VERSION ""

NS_ :

BS_:

BU_: TPMS iBooster_ADAS IM ESC_ADAS EPS1_ADAS CGW_ADAS VCU_ADAS FCM

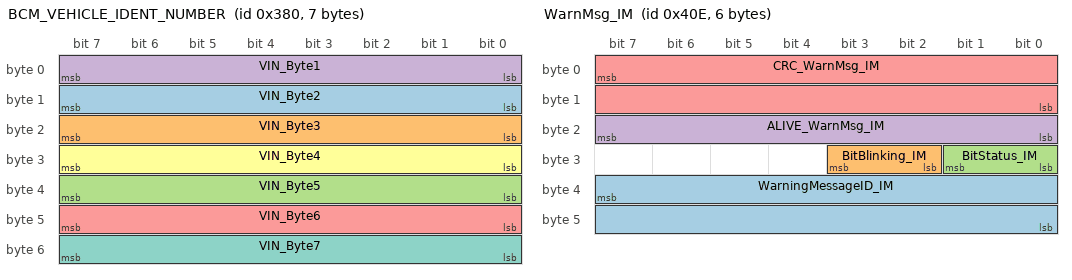
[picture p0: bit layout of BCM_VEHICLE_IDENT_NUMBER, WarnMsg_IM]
BO_ 896 BCM_VEHICLE_IDENT_NUMBER: 7 CGW_ADAS
 SG_ VIN_Byte2 : 15|8@0+ (1,0) [0|254] ""  VCU_ADAS,ESC_ADAS,iBooster_ADAS,EPS1_ADAS
 SG_ VIN_Byte3 : 23|8@0+ (1,0) [0|254] ""  VCU_ADAS,ESC_ADAS,iBooster_ADAS,EPS1_ADAS
 SG_ VIN_Byte5 : 39|8@0+ (1,0) [0|254] ""  VCU_ADAS,ESC_ADAS,iBooster_ADAS,EPS1_ADAS
 SG_ VIN_Byte1 : 7|8@0+ (1,0) [0|254] ""  VCU_ADAS,iBooster_ADAS,EPS1_ADAS,ESC_ADAS
 SG_ VIN_Byte6 : 47|8@0+ (1,0) [0|254] ""  VCU_ADAS,ESC_ADAS,iBooster_ADAS,EPS1_ADAS
 SG_ VIN_Byte4 : 31|8@0+ (1,0) [0|254] ""  VCU_ADAS,ESC_ADAS,iBooster_ADAS,EPS1_ADAS
 SG_ VIN_Byte7 : 55|8@0+ (1,0) [0|254] ""  VCU_ADAS,ESC_ADAS,iBooster_ADAS,EPS1_ADAS

BO_ 264 BCM_02_STAT_CENTRAL_LOCK_FLAP: 16 CGW_ADAS
 SG_ SSecOC_MAC_BCM_02 : 39|64@0+ (1,0) [0|1.84467440737096E+019] ""  FCM,ESC_ADAS,VCU_ADAS
 SG_ SSecOC_Fresh_BCM_02 : 31|8@0+ (1,0) [0|255] ""  FCM,ESC_ADAS,VCU_ADAS
 SG_ BCM_charging_flap_ajar_status : 115|2@0+ (1,0) [0|3] ""  VCU_ADAS,FCM,ESC_ADAS
 SG_ ALIVE_BCM_02 : 23|8@0+ (1,0) [0|255] ""  VCU_ADAS,FCM,ESC_ADAS
 SG_ CRC_BCM_02 : 7|16@0+ (1,0) [0|65535] ""  FCM,VCU_ADAS,ESC_ADAS
 SG_ STAT_BonnetAjar : 117|2@0+ (1,0) [0|3] "Bit"  VCU_ADAS,FCM,ESC_ADAS
 SG_ STAT_TrunkAjar : 119|2@0+ (1,0) [0|3] "Bit"  VCU_ADAS,FCM,ESC_ADAS
 SG_ STAT_DoorAjarRR : 105|2@0+ (1,0) [0|3] "Bit"  VCU_ADAS,FCM,ESC_ADAS
 SG_ STAT_DoorAjarPass : 109|2@0+ (1,0) [0|3] "Bit"  VCU_ADAS,FCM,ESC_ADAS
 SG_ STAT_DoorAjarRL : 107|2@0+ (1,0) [0|3] "Bit"  VCU_ADAS,FCM,ESC_ADAS
 SG_ STAT_DoorAjarDriver : 111|2@0+ (1,0) [0|3] "Bit"  VCU_ADAS,FCM,ESC_ADAS
 SG_ STAT_DoorLockPassenger : 101|2@0+ (1,0) [0|3] ""  VCU_ADAS,FCM,ESC_ADAS
 SG_ STAT_CDL_LED : 99|2@0+ (1,0) [0|3] ""  VCU_ADAS,FCM,ESC_ADAS
 SG_ STAT_ATWS : 127|3@0+ (1,0) [0|7] "Bit"  VCU_ADAS,FCM,ESC_ADAS
 SG_ STAT_DoorLockDriver : 103|2@0+ (1,0) [0|3] "Bit"  VCU_ADAS,FCM,ESC_ADAS

BO_ 433 CGW_01_CON_VEH: 16 CGW_ADAS
 SG_ SSecOC_MAC_CGW_01 : 39|64@0+ (1,0) [0|1.84467440737096E+019] ""  VCU_ADAS,ESC_ADAS,EPS1_ADAS,FCM,IM,iBooster_ADAS,TPMS
 SG_ ALIVE_CGW_01 : 23|8@0+ (1,0) [0|255] ""  VCU_ADAS,ESC_ADAS,EPS1_ADAS,FCM,IM,iBooster_ADAS,TPMS
 SG_ CRC_CGW_01 : 7|16@0+ (1,0) [0|65535] ""  VCU_ADAS,ESC_ADAS,EPS1_ADAS,FCM,IM,iBooster_ADAS,TPMS
 SG_ VEH_State : 103|4@0+ (1,0) [0|15] ""  VCU_ADAS,EPS1_ADAS,ESC_ADAS,FCM,IM,iBooster_ADAS,TPMS
 SG_ SSecOC_Fresh_CGW_01 : 31|8@0+ (1,0) [0|255] ""  VCU_ADAS,ESC_ADAS,EPS1_ADAS,FCM,IM,iBooster_ADAS,TPMS
 SG_ CGW_OBDConnectStatus : 99|2@0+ (1,0) [0|3] ""  VCU_ADAS,TPMS,IM,iBooster_ADAS,FCM,ESC_ADAS,EPS1_ADAS

BO_ 1040 WarnMsg_EPS1: 16 EPS1_ADAS
 SG_ SSecOC_MAC_EPS1WarnMsg : 39|64@0+ (1,0) [0|1.84467440737096E+019] ""  CGW_ADAS
 SG_ SSecOC_Fresh_EPS1WarnMsg : 31|8@0+ (1,0) [0|255] ""  CGW_ADAS
 SG_ WarningMessageID_EPS1 : 111|16@0+ (1,0) [0|65535] ""  CGW_ADAS
 SG_ BitBlinking_EPS1 : 99|2@0+ (1,0) [0|3] "Bit"  CGW_ADAS
 SG_ BitStatus_EPS1 : 97|2@0+ (1,0) [0|3] "Bit"  CGW_ADAS
 SG_ ALIVE_WarnMsg_EPS1 : 23|8@0+ (1,0) [0|255] ""  CGW_ADAS
 SG_ CRC_WarnMsg_EPS1 : 7|16@0+ (1,0) [0|65535] ""  CGW_ADAS

BO_ 1039 WarnMsg_ESC: 16 ESC_ADAS
 SG_ SSecOC_MAC_ESCWarnMsg : 39|64@0+ (1,0) [0|1.84467440737096E+019] ""  CGW_ADAS
 SG_ SSecOC_Fresh_ESCWarnMsg : 31|8@0+ (1,0) [0|255] ""  CGW_ADAS
 SG_ WarningMessageID_ESC : 111|16@0+ (1,0) [0|65535] ""  CGW_ADAS
 SG_ BitBlinking_ESC : 99|2@0+ (1,0) [0|3] "Bit"  CGW_ADAS
 SG_ BitStatus_ESC : 97|2@0+ (1,0) [0|3] "Bit"  CGW_ADAS
 SG_ ALIVE_WarnMsg_ESC : 23|8@0+ (1,0) [0|255] ""  CGW_ADAS
 SG_ CRC_WarnMsg_ESC : 7|16@0+ (1,0) [0|65535] ""  CGW_ADAS

BO_ 1038 WarnMsg_IM: 6 IM
 SG_ WarningMessageID_IM : 39|16@0+ (1,0) [0|65535] ""  CGW_ADAS
 SG_ BitBlinking_IM : 27|2@0+ (1,0) [0|3] "Bit"  CGW_ADAS
 SG_ BitStatus_IM : 25|2@0+ (1,0) [0|3] "Bit"  CGW_ADAS
 SG_ ALIVE_WarnMsg_IM : 23|8@0+ (1,0) [0|255] ""  CGW_ADAS
 SG_ CRC_WarnMsg_IM : 7|16@0+ (1,0) [0|65535] ""  CGW_ADAS

BO_ 247 BMS_01_HVB_status: 64 VCU_ADAS
 SG_ BMS_SOHlastUpdateInterval : 255|14@0+ (1,0) [0|16383] "km"  CGW_ADAS,FCM,EPS1_ADAS
 SG_ BMS_actPower : 503|10@0+ (1,-600) [-600|250] "kWh"  CGW_ADAS,FCM,EPS1_ADAS
 SG_ BMS_addedEnergyCharging : 204|9@0+ (1,-250) [-250|250] "kWh"  CGW_ADAS,FCM,EPS1_ADAS
 SG_ BMS_BattCellstartframeNum : 487|16@0+ (1,0) [1|65531] ""  CGW_ADAS,FCM,EPS1_ADAS
 SG_ BMS_HvBattSocinstalled : 109|10@0+ (0.1,0) [0|100] "percent (%)"  CGW_ADAS,EPS1_ADAS,FCM
 SG_ BMS_HvBattSt : 115|3@0+ (1,0) [0|7] ""  CGW_ADAS,FCM,EPS1_ADAS
 SG_ BMS_HvBattIMaxDchaLon : 223|11@0+ (1,0) [0|2047] "ampere (A)"  CGW_ADAS,EPS1_ADAS,FCM
 SG_ BMS_HvBattI : 327|16@0+ (0.1,-2047) [-2047|2047] "ampere (A)"  CGW_ADAS,EPS1_ADAS,FCM
 SG_ BMS_HvBattRlyPosSt : 157|2@0+ (1,0) [0|1] ""  CGW_ADAS,EPS1_ADAS,FCM
 SG_ BMS_HvBattRlyNegSt : 155|2@0+ (1,0) [0|1] ""  CGW_ADAS,EPS1_ADAS,FCM
 SG_ BMS_HvBattT30CVolt : 295|15@0+ (1,0) [0|32767] "mV"  CGW_ADAS,EPS1_ADAS,FCM
 SG_ BMS_HvBattPackUDchaLim : 151|10@0+ (1,0) [0|1023] "volt (V)"  CGW_ADAS,EPS1_ADAS,FCM
 SG_ BMS_HvBattSoeAct : 127|11@0+ (0.1,0) [0|204.7] "kWh"  CGW_ADAS,EPS1_ADAS,FCM
 SG_ BMS_HvBattU : 343|14@0+ (0.1,0) [0|1638.3] "volt (V)"  CGW_ADAS,EPS1_ADAS,FCM
 SG_ BMS_HvBattPackUChrgnLim : 167|10@0+ (1,0) [0|1023] "volt (V)"  CGW_ADAS,EPS1_ADAS,FCM
 SG_ BMS_HvBattDynChrgILim : 239|11@0+ (1,0) [0|2047] "ampere (A)"  CGW_ADAS,EPS1_ADAS,FCM
 SG_ SSecOC_MAC_BMS_01 : 39|64@0+ (1,0) [0|1.84467440737096E+019] ""  CGW_ADAS,EPS1_ADAS,FCM
 SG_ SSecOC_Fresh_BMS_01 : 31|8@0+ (1,0) [0|255] ""  CGW_ADAS,EPS1_ADAS,FCM
 SG_ ALIVE_BMS_01 : 23|8@0+ (1,0) [0|255] ""  CGW_ADAS,EPS1_ADAS,FCM
 SG_ CRC_BMS_01 : 7|16@0+ (1,0) [0|65535] ""  CGW_ADAS,EPS1_ADAS,FCM
 SG_ BMS_HvBattIMaxChrgLon : 271|11@0+ (1,0) [0|2047] "ampere (A)"  CGW_ADAS,EPS1_ADAS,FCM
 SG_ BMS_HvBattSoh : 143|7@0+ (1,0) [0|100] "percent (%)"  CGW_ADAS,EPS1_ADAS,FCM
 SG_ BMS_HvBattChrgnAllwd : 136|1@0+ (1,0) [0|1] ""  CGW_ADAS,EPS1_ADAS,FCM
 SG_ BMS_HvBattSdilSt : 425|2@0+ (1,0) [0|3] ""  CGW_ADAS,EPS1_ADAS,FCM
 SG_ BMS_HVBattCellVolt : 471|16@0+ (1,0) [0|65535] "mV"  CGW_ADAS,FCM,EPS1_ADAS
 SG_ BMS_HvBattIMaxDchaMidLon : 423|11@0+ (1,0) [0|2047] ""  CGW_ADAS,EPS1_ADAS,FCM
 SG_ BMS_HvBattUint : 407|13@0+ (0.1,0) [0|819.1] "volt (V)"  CGW_ADAS,EPS1_ADAS,FCM
 SG_ BMS_HvBattIsoR_status : 112|1@0+ (1,0) [0|1] ""  CGW_ADAS,EPS1_ADAS,FCM
 SG_ BMS_HvBattHvilSt : 427|2@0+ (1,0) [0|3] ""  CGW_ADAS,EPS1_ADAS,FCM
 SG_ BMS_HvBattIsoRNegGND_Ohm : 455|16@0+ (1,0) [0|65535] "kiloohm"  CGW_ADAS,EPS1_ADAS,FCM
 SG_ BMS_HvBattIsoRPosGND_Ohm : 439|16@0+ (1,0) [0|65535] "kiloohm"  CGW_ADAS,EPS1_ADAS,FCM
 SG_ BMS_HvBattCellVoltMax : 391|13@0+ (1,0) [0|8191] "mV"  CGW_ADAS,EPS1_ADAS,FCM
 SG_ BMS_HvBattCellVoltNom : 375|13@0+ (1,0) [0|8191] "mV"  CGW_ADAS,EPS1_ADAS,FCM
 SG_ BMS_HvBattCellVoltMin : 359|13@0+ (1,0) [0|8191] "mV"  CGW_ADAS,EPS1_ADAS,FCM
 SG_ BMS_HvBattT30Volt : 311|15@0+ (1,0) [0|32767] "mV"  CGW_ADAS,EPS1_ADAS,FCM
 SG_ BMS_HvBattRlyPrechSt : 153|2@0+ (1,0) [0|1] ""  CGW_ADAS,EPS1_ADAS,FCM
 SG_ BMS_HvBattIMaxChrgMidLon : 274|11@0+ (1,0) [0|2047] "ampere (A)"  CGW_ADAS,EPS1_ADAS,FCM
 SG_ BMS_HvBattDynDchaILim : 199|11@0+ (1,0) [0|2047] "ampere (A)"  CGW_ADAS,EPS1_ADAS,FCM
 SG_ BMS_HvBattCellUChrgnLim : 183|13@0+ (1,0) [0|8191] "mV"  CGW_ADAS,EPS1_ADAS,FCM
 SG_ BMS_HvBattSocAct_usable : 103|10@0+ (0.1,0) [0|100] "percent (%)"  CGW_ADAS,EPS1_ADAS,FCM

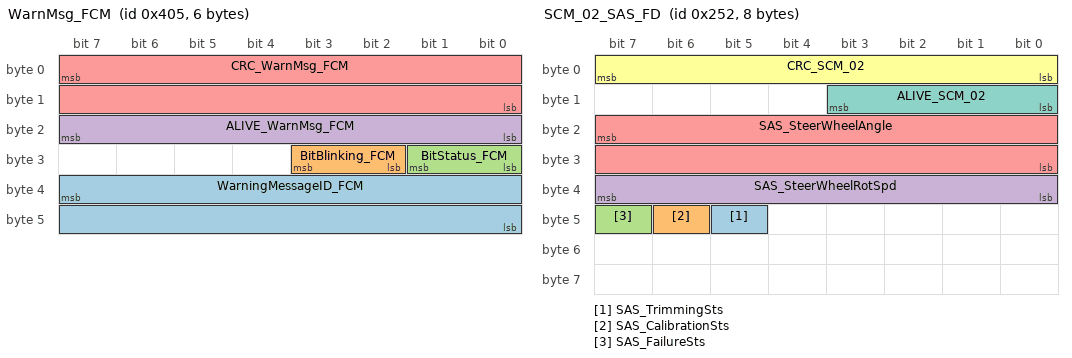
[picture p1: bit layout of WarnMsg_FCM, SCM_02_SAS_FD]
BO_ 1029 WarnMsg_FCM: 6 FCM
 SG_ WarningMessageID_FCM : 39|16@0+ (1,0) [0|65535] ""  CGW_ADAS
 SG_ BitBlinking_FCM : 27|2@0+ (1,0) [0|3] "Bit"  CGW_ADAS
 SG_ BitStatus_FCM : 25|2@0+ (1,0) [0|3] "Bit"  CGW_ADAS
 SG_ ALIVE_WarnMsg_FCM : 23|8@0+ (1,0) [0|255] ""  CGW_ADAS
 SG_ CRC_WarnMsg_FCM : 7|16@0+ (1,0) [0|65535] ""  CGW_ADAS

BO_ 258 BCM_01_LOGICAL_CLAMP: 16 CGW_ADAS
 SG_ SSecOC_MAC_BCM_01 : 39|64@0+ (1,0) [0|1.84467440737096E+019] ""  VCU_ADAS,TPMS,IM,iBooster_ADAS,FCM,ESC_ADAS,EPS1_ADAS
 SG_ SSecOC_Fresh_BCM_01 : 31|8@0+ (1,0) [0|255] ""  VCU_ADAS,TPMS,IM,iBooster_ADAS,FCM,ESC_ADAS,EPS1_ADAS
 SG_ STAT_StartStopButton : 115|2@0+ (1,0) [0|3] ""  VCU_ADAS,TPMS,IM,iBooster_ADAS,FCM,ESC_ADAS,EPS1_ADAS
 SG_ BCM_Cl30R_Off_Announcement : 125|2@0+ (1,0) [0|3] ""  VCU_ADAS,TPMS,IM,iBooster_ADAS,FCM,ESC_ADAS,EPS1_ADAS
 SG_ BCM_Cl30s_Off_Announcement : 127|2@0+ (1,0) [0|3] ""  VCU_ADAS,TPMS,IM,iBooster_ADAS,FCM,ESC_ADAS,EPS1_ADAS
 SG_ BCM_STAT_TransportMode : 117|2@0+ (1,0) [0|3] ""  VCU_ADAS,FCM,IM,ESC_ADAS,EPS1_ADAS,iBooster_ADAS,TPMS
 SG_ BCM_KL15_Off_Announcement : 119|2@0+ (1,0) [0|3] ""  VCU_ADAS,FCM,IM,ESC_ADAS,EPS1_ADAS,iBooster_ADAS,TPMS
 SG_ BCM_ST_KL : 108|4@0+ (1,0) [0|15] ""  VCU_ADAS,FCM,IM,ESC_ADAS,EPS1_ADAS,iBooster_ADAS,TPMS
 SG_ BCM_STAT_Terminal : 111|3@0+ (1,0) [0|7] ""  VCU_ADAS,FCM,IM,ESC_ADAS,EPS1_ADAS,iBooster_ADAS,TPMS
 SG_ BCM_STAT_CL30R_L : 99|2@0+ (1,0) [0|3] ""  VCU_ADAS,FCM,IM,ESC_ADAS,EPS1_ADAS,iBooster_ADAS,TPMS
 SG_ BCM_STAT_CL30s_L : 101|2@0+ (1,0) [0|3] ""  VCU_ADAS,FCM,IM,ESC_ADAS,EPS1_ADAS,iBooster_ADAS,TPMS
 SG_ CRC_BCM_01 : 7|16@0+ (1,0) [0|65535] ""  VCU_ADAS,FCM,IM,ESC_ADAS,EPS1_ADAS,iBooster_ADAS,TPMS
 SG_ ALIVE_BCM_01 : 23|8@0+ (1,0) [0|255] ""  VCU_ADAS,FCM,IM,ESC_ADAS,EPS1_ADAS,iBooster_ADAS,TPMS
 SG_ BCM_STAT_CL15_L : 103|2@0+ (1,0) [0|3] ""  VCU_ADAS,FCM,IM,ESC_ADAS,EPS1_ADAS,iBooster_ADAS,TPMS

BO_ 2564502513 Diag_FuncReq: 8 CGW_ADAS
 SG_ Diag_FuncReq_Data : 7|64@0+ (1,0) [0|1.84467440737096E+019] "N/A"  FCM,IM,ESC_ADAS,iBooster_ADAS,TPMS,EPS1_ADAS

BO_ 752 HU_OdoMeter: 16 CGW_ADAS
 SG_ SSecOC_MAC_HU_OdoMeter : 39|64@0+ (1,0) [0|255] ""  VCU_ADAS,IM,FCM,ESC_ADAS,iBooster_ADAS,EPS1_ADAS
 SG_ SSecOC_Fresh_HU_OdoMeter : 31|8@0+ (1,0) [0|255] ""  VCU_ADAS,IM,FCM,ESC_ADAS,iBooster_ADAS,EPS1_ADAS
 SG_ ALIVE_HU_OdoMeter : 23|8@0+ (1,0) [0|255] ""  VCU_ADAS,IM,FCM,ESC_ADAS,iBooster_ADAS,EPS1_ADAS
 SG_ CRC_HU_OdoMeter : 7|16@0+ (1,0) [0|65535] ""  VCU_ADAS,IM,FCM,ESC_ADAS,iBooster_ADAS,EPS1_ADAS
 SG_ HU_Odometer : 103|24@0+ (1,0) [0|16777215] "km"  VCU_ADAS,IM,FCM,ESC_ADAS,iBooster_ADAS,EPS1_ADAS

BO_ 513 ACM_02_SBR: 20 CGW_ADAS
 SG_ ST_OCS_CalRespSts : 147|2@0+ (1,0) [0|3] ""  VCU_ADAS,FCM,ESC_ADAS
 SG_ ST_OCS_CalVal : 150|3@0+ (1,0) [0|7] ""  VCU_ADAS,FCM,ESC_ADAS
 SG_ ST_OCS_EOL : 151|1@0+ (1,0) [0|1] ""  VCU_ADAS,FCM,ESC_ADAS
 SG_ ST_OCS_EcuFailr : 106|1@0+ (1,0) [0|1] ""  VCU_ADAS,FCM,ESC_ADAS
 SG_ ST_OCS_StsCntr : 139|4@0+ (1,0) [0|15] ""  VCU_ADAS,FCM,ESC_ADAS
 SG_ ST_OCS_AirbAllwdSts : 141|2@0+ (1,0) [0|3] ""  VCU_ADAS,FCM,ESC_ADAS
 SG_ ST_OCS_ERROR : 111|3@0+ (1,0) [0|7] ""  VCU_ADAS,FCM,ESC_ADAS
 SG_ SSecOC_MAC_ACM_02 : 39|64@0+ (1,0) [0|1.84467440737096E+019] ""  VCU_ADAS,FCM,ESC_ADAS
 SG_ SSecOC_Fresh_ACM_02 : 31|8@0+ (1,0) [0|255] ""  VCU_ADAS,FCM,ESC_ADAS
 SG_ ST_SEAT_POS_PAS : 127|2@0+ (1,0) [0|3] ""  VCU_ADAS,FCM,ESC_ADAS
 SG_ ST_SEAT_POS_DRV : 119|2@0+ (1,0) [0|3] ""  VCU_ADAS,FCM,ESC_ADAS
 SG_ ST_PAB_SW : 105|2@0+ (1,0) [0|3] ""  VCU_ADAS,FCM,ESC_ADAS
 SG_ ST_PAB_ON : 103|1@0+ (1,0) [0|1] ""  VCU_ADAS,FCM,ESC_ADAS
 SG_ ST_BELT_BUCK_RM : 129|2@0+ (1,0) [0|3] ""  VCU_ADAS,FCM,ESC_ADAS
 SG_ ST_IGN_ACM : 99|1@0+ (1,0) [0|1] ""  VCU_ADAS,FCM,ESC_ADAS
 SG_ ST_CRS_DET : 101|2@0+ (1,0) [0|3] ""  VCU_ADAS,FCM,ESC_ADAS
 SG_ ST_COD : 98|3@0+ (1,0) [0|7] ""  VCU_ADAS,FCM,ESC_ADAS
 SG_ ST_BELT_BUCK_RR : 143|2@0+ (1,0) [0|3] ""  VCU_ADAS,FCM,ESC_ADAS
 SG_ ST_BELT_BUCK_RL : 131|2@0+ (1,0) [0|3] ""  VCU_ADAS,FCM,ESC_ADAS
 SG_ ST_BELT_BUCK_PS : 133|2@0+ (1,0) [0|3] ""  VCU_ADAS,FCM,ESC_ADAS
 SG_ ST_SEAT_OCCU_PS : 108|2@0+ (1,0) [0|3] ""  VCU_ADAS,FCM,ESC_ADAS
 SG_ ST_BELT_BUCK_DR : 135|2@0+ (1,0) [0|3] ""  VCU_ADAS,FCM,ESC_ADAS
 SG_ ST_PAB_OFF : 102|1@0+ (1,0) [0|1] ""  VCU_ADAS,FCM,ESC_ADAS
 SG_ ALIVE_ACM_02 : 23|8@0+ (1,0) [0|255] ""  VCU_ADAS,FCM,ESC_ADAS
 SG_ CRC_ACM_02 : 7|16@0+ (1,0) [0|65535] ""  VCU_ADAS,FCM,ESC_ADAS

BO_ 2564485412 Diag_Resp_RadarRR: 64 FCM
 SG_ Diag_Resp_RadarRR : 7|64@0+ (1,0) [0|1.84467440737096E+019] "N/A"  CGW_ADAS

BO_ 2564485411 Diag_Resp_RadarRL: 64 FCM
 SG_ Diag_Resp_RadarRL : 7|64@0+ (1,0) [0|1.84467440737096E+019] "N/A"  CGW_ADAS

BO_ 2564485404 Diag_Resp_RF: 64 FCM
 SG_ Diag_Resp_RF : 7|64@0+ (1,0) [0|1.84467440737096E+019] "N/A"  CGW_ADAS

BO_ 2564433137 Diag_PhyReq_RadarRR: 64 CGW_ADAS
 SG_ Diag_PhyReq_RadarRR : 7|64@0+ (1,0) [0|1.84467440737096E+019] "N/A"  FCM

BO_ 2564432881 Diag_PhyReq_RadarRL: 64 CGW_ADAS
 SG_ Diag_PhyReq_RadarRL : 7|64@0+ (1,0) [0|1.84467440737096E+019] "N/A"  FCM

BO_ 2564431089 Diag_PhyReq_RF: 64 CGW_ADAS
 SG_ Diag_PhyReq_RF : 7|64@0+ (1,0) [0|1.84467440737096E+019] "N/A"  FCM

BO_ 1305 NM_TPMS: 8 TPMS
 SG_ usrData1_TPM_Bit7_ECUSPEC_AWAKE : 31|1@0+ (1,0) [0|1] ""  VCU_ADAS,IM,iBooster_ADAS,FCM,ESC_ADAS,EPS1_ADAS,CGW_ADAS
 SG_ usrData1_TPM_Bit6_DIAGN_AWAKE : 30|1@0+ (1,0) [0|1] ""  VCU_ADAS,IM,iBooster_ADAS,FCM,ESC_ADAS,EPS1_ADAS,CGW_ADAS
 SG_ usrData1_TPM_Bit5_IGNITION_AWAKE : 29|1@0+ (1,0) [0|1] ""  VCU_ADAS,IM,iBooster_ADAS,FCM,ESC_ADAS,EPS1_ADAS,CGW_ADAS
 SG_ usrData1_TPM_Bit4_NETWORK_AWAKE : 28|1@0+ (1,0) [0|1] ""  VCU_ADAS,IM,iBooster_ADAS,FCM,ESC_ADAS,EPS1_ADAS,CGW_ADAS
 SG_ usrData1_TPM_Bit3_ECUSPEC_WAKEUP : 27|1@0+ (1,0) [0|1] ""  VCU_ADAS,IM,iBooster_ADAS,FCM,ESC_ADAS,EPS1_ADAS,CGW_ADAS
 SG_ usrData1_TPM_Bit2_NETWORK_WAKEUP : 26|1@0+ (1,0) [0|1] ""  VCU_ADAS,IM,iBooster_ADAS,FCM,ESC_ADAS,EPS1_ADAS,CGW_ADAS
 SG_ usrData1_TPM_Bit1_RESET_WAKEUP : 25|1@0+ (1,0) [0|1] ""  VCU_ADAS,IM,iBooster_ADAS,FCM,ESC_ADAS,EPS1_ADAS,CGW_ADAS
 SG_ CtrlBitVector_TPM_Bit7_Res : 15|1@0+ (1,0) [0|1] ""  VCU_ADAS,IM,iBooster_ADAS,FCM,ESC_ADAS,EPS1_ADAS,CGW_ADAS
 SG_ CtrlBitVector_TPM_Bit6_PNI : 14|1@0+ (1,0) [0|1] ""  VCU_ADAS,IM,iBooster_ADAS,FCM,ESC_ADAS,EPS1_ADAS,CGW_ADAS
 SG_ CtrlBitVector_TPM_Bit5_Res : 13|1@0+ (1,0) [0|1] ""  VCU_ADAS,IM,iBooster_ADAS,FCM,ESC_ADAS,EPS1_ADAS,CGW_ADAS
 SG_ CtrlBitVector_TPM_Bit4_ActWake : 12|1@0+ (1,0) [0|1] ""  VCU_ADAS,IM,iBooster_ADAS,FCM,ESC_ADAS,EPS1_ADAS,CGW_ADAS
 SG_ CtrlBitVector_TPM_Bit3_NMCoord : 11|1@0+ (1,0) [0|1] ""  VCU_ADAS,IM,iBooster_ADAS,FCM,ESC_ADAS,EPS1_ADAS,CGW_ADAS
 SG_ CtrlBitVector_TPM_Bit2_Res : 10|1@0+ (1,0) [0|1] ""  VCU_ADAS,IM,iBooster_ADAS,FCM,ESC_ADAS,EPS1_ADAS,CGW_ADAS
 SG_ CtrlBitVector_TPM_Bit1_Res : 9|1@0+ (1,0) [0|1] ""  VCU_ADAS,IM,iBooster_ADAS,FCM,ESC_ADAS,EPS1_ADAS,CGW_ADAS
 SG_ usrData1_TPM_Bit0_IGN_WAKEUP : 24|1@0+ (1,0) [0|1] ""  VCU_ADAS,IM,iBooster_ADAS,FCM,ESC_ADAS,EPS1_ADAS,CGW_ADAS
 SG_ usrData0_TPM : 23|8@0+ (1,0) [0|255] ""  VCU_ADAS,IM,iBooster_ADAS,FCM,ESC_ADAS,EPS1_ADAS,CGW_ADAS
 SG_ srcNodeID_TPM : 7|8@0+ (1,0) [0|127] ""  VCU_ADAS,IM,iBooster_ADAS,FCM,ESC_ADAS,EPS1_ADAS,CGW_ADAS
 SG_ CtrlBitVector_TPM_Bit0_RMR : 8|1@0+ (1,0) [0|1] ""  VCU_ADAS,IM,iBooster_ADAS,FCM,ESC_ADAS,EPS1_ADAS,CGW_ADAS
 SG_ usrData2_TPM : 39|8@0+ (1,0) [0|255] ""  VCU_ADAS,IM,iBooster_ADAS,FCM,ESC_ADAS,EPS1_ADAS,CGW_ADAS
 SG_ usrData4_TPM_PN_Info1 : 55|8@0+ (1,0) [0|255] ""  VCU_ADAS,IM,iBooster_ADAS,FCM,ESC_ADAS,EPS1_ADAS,CGW_ADAS
 SG_ usrData5_TPM_PN_Info2 : 63|8@0+ (1,0) [0|255] ""  VCU_ADAS,IM,iBooster_ADAS,FCM,ESC_ADAS,EPS1_ADAS,CGW_ADAS
 SG_ usrData3_TPM : 47|8@0+ (1,0) [0|255] ""  VCU_ADAS,IM,iBooster_ADAS,FCM,ESC_ADAS,EPS1_ADAS,CGW_ADAS

BO_ 1913 Meas_TPMS_1: 8 TPMS
 SG_ TPMS_MEAS_ID M : 7|8@0+ (1,0) [0|0] ""  CGW_ADAS
 SG_ Meas_TPM_1H m1 : 63|8@0+ (1,0) [0|255] ""  CGW_ADAS
 SG_ Meas_TPM_1G m1 : 55|8@0+ (1,0) [0|255] ""  CGW_ADAS
 SG_ Meas_TPM_1F : 47|8@0+ (1,0) [0|255] ""  CGW_ADAS
 SG_ Meas_TPM_1E m2 : 39|8@0+ (1,0) [0|255] ""  CGW_ADAS
 SG_ Meas_TPM_1D m1 : 31|8@0+ (1,0) [0|255] ""  CGW_ADAS
 SG_ Meas_TPM_1C m1 : 23|8@0+ (1,0) [0|255] ""  CGW_ADAS
 SG_ Meas_TPM_1B m1 : 15|8@0+ (1,0) [0|255] ""  CGW_ADAS
 SG_ Meas_TPM_1A m1 : 39|8@0+ (1,0) [0|255] ""  CGW_ADAS

BO_ 1284 NM_VCU: 8 VCU_ADAS
 SG_ usrData1_VCU_Bit7_ECUSPEC_AWAKE : 31|1@0+ (1,0) [0|1] ""  TPMS,IM,iBooster_ADAS,FCM,ESC_ADAS,EPS1_ADAS
 SG_ usrData1_VCU_Bit6_DIAGN_AWAKE : 30|1@0+ (1,0) [0|1] ""  TPMS,IM,iBooster_ADAS,FCM,ESC_ADAS,EPS1_ADAS
 SG_ usrData1_VCU_Bit5_IGNITION_AWAKE : 29|1@0+ (1,0) [0|1] ""  TPMS,IM,iBooster_ADAS,FCM,ESC_ADAS,EPS1_ADAS
 SG_ usrData1_VCU_Bit4_NETWORK_AWAKE : 28|1@0+ (1,0) [0|1] ""  TPMS,IM,iBooster_ADAS,FCM,ESC_ADAS,EPS1_ADAS
 SG_ usrData1_VCU_Bit3_ECUSPEC_WAKEUP : 27|1@0+ (1,0) [0|1] ""  TPMS,IM,iBooster_ADAS,FCM,ESC_ADAS,EPS1_ADAS
 SG_ usrData1_VCU_Bit2_NETWORK_WAKEUP : 26|1@0+ (1,0) [0|1] ""  TPMS,IM,iBooster_ADAS,FCM,ESC_ADAS,EPS1_ADAS
 SG_ usrData1_VCU_Bit1_RESET_WAKEUP : 25|1@0+ (1,0) [0|1] ""  TPMS,IM,iBooster_ADAS,FCM,ESC_ADAS,EPS1_ADAS
 SG_ CtrlBitVector_VCU_Bit7_Res : 15|1@0+ (1,0) [0|1] ""  TPMS,IM,iBooster_ADAS,FCM,ESC_ADAS,EPS1_ADAS
 SG_ CtrlBitVector_VCU_Bit6_PNI : 14|1@0+ (1,0) [0|1] ""  TPMS,IM,iBooster_ADAS,FCM,ESC_ADAS,EPS1_ADAS
 SG_ CtrlBitVector_VCU_Bit5_Res : 13|1@0+ (1,0) [0|1] ""  TPMS,IM,iBooster_ADAS,FCM,ESC_ADAS,EPS1_ADAS
 SG_ CtrlBitVector_VCU_Bit4_ActWake : 12|1@0+ (1,0) [0|1] ""  TPMS,IM,iBooster_ADAS,FCM,ESC_ADAS,EPS1_ADAS
 SG_ CtrlBitVector_VCU_Bit3_NMCoord : 11|1@0+ (1,0) [0|1] ""  TPMS,IM,iBooster_ADAS,FCM,ESC_ADAS,EPS1_ADAS
 SG_ CtrlBitVector_VCU_Bit2_Res : 10|1@0+ (1,0) [0|1] ""  TPMS,IM,iBooster_ADAS,FCM,ESC_ADAS,EPS1_ADAS
 SG_ CtrlBitVector_VCU_Bit1_Res : 9|1@0+ (1,0) [0|1] ""  TPMS,IM,iBooster_ADAS,FCM,ESC_ADAS,EPS1_ADAS
 SG_ usrData1_VCU_Bit0_IGN_WAKEUP : 24|1@0+ (1,0) [0|1] ""  TPMS,IM,iBooster_ADAS,FCM,ESC_ADAS,EPS1_ADAS
 SG_ usrData0_VCU : 23|8@0+ (1,0) [0|255] ""  TPMS,IM,iBooster_ADAS,FCM,ESC_ADAS,EPS1_ADAS
 SG_ srcNodeID_VCU : 7|8@0+ (1,0) [0|127] ""  TPMS,IM,iBooster_ADAS,FCM,ESC_ADAS,EPS1_ADAS
 SG_ CtrlBitVector_VCU_Bit0_RMR : 8|1@0+ (1,0) [0|1] ""  TPMS,IM,iBooster_ADAS,FCM,ESC_ADAS,EPS1_ADAS
 SG_ usrData2_VCU : 39|8@0+ (1,0) [0|255] ""  TPMS,IM,iBooster_ADAS,FCM,ESC_ADAS,EPS1_ADAS
 SG_ usrData4_VCU_PN_Info1 : 55|8@0+ (1,0) [0|255] ""  TPMS,IM,iBooster_ADAS,FCM,ESC_ADAS,EPS1_ADAS
 SG_ usrData5_VCU_PN_Info2 : 63|8@0+ (1,0) [0|255] ""  TPMS,IM,iBooster_ADAS,FCM,ESC_ADAS,EPS1_ADAS
 SG_ usrData3_VCU : 47|8@0+ (1,0) [0|255] ""  TPMS,IM,iBooster_ADAS,FCM,ESC_ADAS,EPS1_ADAS

BO_ 594 SCM_02_SAS_FD: 8 CGW_ADAS
 SG_ SAS_TrimmingSts : 45|1@0+ (1,0) [0|1] ""  IM,FCM,EPS1_ADAS,VCU_ADAS
 SG_ SAS_CalibrationSts : 46|1@0+ (1,0) [0|1] ""  IM,FCM,EPS1_ADAS,VCU_ADAS
 SG_ SAS_FailureSts : 47|1@0+ (1,0) [0|1] ""  IM,FCM,EPS1_ADAS,VCU_ADAS
 SG_ SAS_SteerWheelRotSpd : 39|8@0+ (4,0) [0|1016] "deg/s"  IM,FCM,EPS1_ADAS,VCU_ADAS
 SG_ SAS_SteerWheelAngle : 23|16@0+ (0.1,-960) [-960|960] "deg"  IM,FCM,EPS1_ADAS,VCU_ADAS
 SG_ CRC_SCM_02 : 7|8@0+ (1,0) [0|255] ""  IM,FCM,EPS1_ADAS,VCU_ADAS
 SG_ ALIVE_SCM_02 : 11|4@0+ (1,0) [0|15] ""  IM,FCM,EPS1_ADAS,VCU_ADAS

BO_ 592 SCM_01_SwCtrl_FD: 8 CGW_ADAS
 SG_ SCM_SteeringWheel_rotation_flag : 55|1@0+ (1,0) [0|1] ""  FCM
 SG_ SCM_IHBC_MenuReq : 40|1@0+ (1,0) [0|1] ""  FCM
 SG_ SCM_IHBC_MenuReqInvalid : 41|1@0+ (1,0) [0|1] ""  FCM
 SG_ SCM_SW_MasterLightSwitch : 45|4@0+ (1,0) [0|15] ""  FCM
 SG_ SCM_SW_DaytimeLight : 46|1@0+ (1,0) [0|1] ""  FCM
 SG_ SCM_SW_DaytimeLightInvalid : 47|1@0+ (1,0) [0|1] ""  FCM
 SG_ SCM_SW_Trip : 33|2@0+ (1,0) [0|3] ""  FCM
 SG_ SCM_Req_TurnIndicationAct : 35|2@0+ (1,0) [0|3] ""  FCM
 SG_ SCM_RearWipingMode : 37|2@0+ (1,0) [0|3] ""  FCM
 SG_ SCM_SW_FrontFogLight : 38|1@0+ (1,0) [0|1] ""  FCM
 SG_ SCM_SW_FrontFogLightInvalid : 39|1@0+ (1,0) [0|1] ""  FCM
 SG_ SCM_SW_RearFogLight : 24|1@0+ (1,0) [0|1] ""  FCM
 SG_ SCM_SW_RearFogLightInvalid : 25|1@0+ (1,0) [0|1] ""  FCM
 SG_ SCM_WipingInterval_Sensitvity : 28|3@0+ (1,0) [0|7] ""  FCM
 SG_ SCM_FrontWipingMode : 31|3@0+ (1,0) [0|7] ""  FCM
 SG_ SCM_SW_FlashLightSts : 16|1@0+ (1,0) [0|1] ""  FCM
 SG_ SCM_SW_FlashLightStsInvalid : 17|1@0+ (1,0) [0|1] ""  FCM
 SG_ SCM_SW_RWasherSts : 18|1@0+ (1,0) [0|1] ""  FCM
 SG_ SCM_SW_RWasherStsInvalid : 19|1@0+ (1,0) [0|0] ""  FCM
 SG_ SCM_SW_FWasherSts : 20|1@0+ (1,0) [0|1] ""  FCM
 SG_ SCM_SW_FWasherStsInvalid : 21|1@0+ (1,0) [0|1] ""  FCM
 SG_ SCM_SW_HighBeam : 22|1@0+ (1,0) [0|1] ""  FCM
 SG_ SCM_SW_HighBeamInvalid : 23|1@0+ (1,0) [0|1] ""  FCM
 SG_ ALIVE_SCM_01 : 11|4@0+ (1,0) [0|15] ""  FCM
 SG_ CRC_SCM_01 : 7|8@0+ (1,0) [0|255] ""  FCM

BO_ 389 FCM_05_PDC: 32 FCM
 SG_ FCM_PDC_ROR_USSSts : 209|2@0+ (1,0) [0|3] ""  CGW_ADAS
 SG_ FCM_PDC_ROL_USSSts : 207|2@0+ (1,0) [0|3] ""  CGW_ADAS
 SG_ FCM_PDC_FOR_USSSts : 205|2@0+ (1,0) [0|3] ""  CGW_ADAS
 SG_ FCM_PDC_FOL_USSSts : 203|2@0+ (1,0) [0|3] ""  CGW_ADAS
 SG_ FCM_PDC_RIR_USSSts : 201|2@0+ (1,0) [0|3] ""  CGW_ADAS
 SG_ FCM_PDC_RIL_USSSts : 199|2@0+ (1,0) [0|3] ""  CGW_ADAS
 SG_ FCM_PDC_RearAudWarn : 179|3@0+ (1,0) [0|7] ""  CGW_ADAS
 SG_ FCM_PDC_FrontAudWarn : 182|3@0+ (1,0) [0|7] ""  CGW_ADAS
 SG_ FCM_PDC_FailrWarn : 183|1@0+ (1,0) [0|1] ""  CGW_ADAS
 SG_ ALIVE_FCM_05 : 23|8@0+ (1,0) [0|255] ""  CGW_ADAS
 SG_ CRC_FCM_05 : 7|16@0+ (1,0) [0|65535] ""  CGW_ADAS
 SG_ FCM_PDC_ToneVol : 175|8@0+ (1,0) [0|255] ""  CGW_ADAS
 SG_ FCM_PDC_Mode : 167|8@0+ (1,0) [0|255] ""  CGW_ADAS
 SG_ FCM_PDC_Distance_ROR : 159|8@0+ (1,0) [0|255] ""  CGW_ADAS
 SG_ FCM_PDC_Distance_RIR : 151|8@0+ (1,0) [0|255] ""  CGW_ADAS
 SG_ FCM_PDC_Distance_RIL : 143|8@0+ (1,0) [0|255] ""  CGW_ADAS
 SG_ FCM_PDC_Distance_ROL : 135|8@0+ (1,0) [0|255] ""  CGW_ADAS
 SG_ FCM_PDC_Distance_FOR : 127|8@0+ (1,0) [0|255] ""  CGW_ADAS
 SG_ FCM_PDC_Distance_FIR : 119|8@0+ (1,0) [0|255] ""  CGW_ADAS
 SG_ FCM_PDC_Distance_FIL : 111|8@0+ (1,0) [0|255] ""  CGW_ADAS
 SG_ FCM_PDC_Distance_FOL : 103|8@0+ (1,0) [0|0] ""  CGW_ADAS
 SG_ FCM_PDC_FIR_USSSts : 197|2@0+ (1,0) [0|3] ""  CGW_ADAS
 SG_ FCM_PDC_FIL_USSSts : 195|2@0+ (1,0) [0|3] ""  CGW_ADAS
 SG_ FCM_PDC_FltMod : 188|3@0+ (1,0) [0|7] ""  CGW_ADAS
 SG_ FCM_PDC_USSCoverSt : 193|2@0+ (1,0) [0|3] ""  CGW_ADAS
 SG_ FCM_PDC_FrntPDCBtnSts : 185|2@0+ (1,0) [0|3] ""  CGW_ADAS

BO_ 272 VCU_05: 20 VCU_ADAS
 SG_ VCU_AccelPedalSts : 97|2@0+ (1,0) [0|0] ""  TPMS,IM,iBooster_ADAS,FCM,ESC_ADAS,EPS1_ADAS
 SG_ SSecOC_MAC_VCU_05 : 39|64@0+ (1,0) [0|1.84467440737096E+019] ""  TPMS,IM,iBooster_ADAS,FCM,ESC_ADAS,EPS1_ADAS
 SG_ SSecOC_Fresh_VCU_05 : 31|8@0+ (1,0) [0|255] ""  TPMS,IM,iBooster_ADAS,FCM,ESC_ADAS,EPS1_ADAS
 SG_ VCU_CC_SpdLim_Sts : 107|3@0+ (1,0) [0|7] ""  TPMS,IM,iBooster_ADAS,FCM,ESC_ADAS,EPS1_ADAS
 SG_ ALIVE_VCU_05 : 23|8@0+ (1,0) [0|255] ""  IM,ESC_ADAS,FCM,iBooster_ADAS,EPS1_ADAS,TPMS
 SG_ CRC_VCU_05 : 7|16@0+ (1,0) [0|65535] ""  IM,ESC_ADAS,FCM,iBooster_ADAS,EPS1_ADAS,TPMS
 SG_ VCU_ActSt : 111|4@0+ (1,0) [0|15] ""  TPMS,iBooster_ADAS,EPS1_ADAS,IM,FCM,ESC_ADAS
 SG_ VCU_GearSig : 103|4@0+ (1,0) [0|15] ""  IM,FCM,ESC_ADAS,iBooster_ADAS,EPS1_ADAS,TPMS
 SG_ VCU_GearSig_Q : 99|2@0+ (1,0) [0|3] ""  IM,FCM,ESC_ADAS,iBooster_ADAS,EPS1_ADAS,TPMS

BO_ 327 EDU_F_03_Rx: 20 VCU_ADAS
 SG_ SSecOC_MAC_EDU_F_03 : 39|64@0+ (1,0) [0|1.84467440737096E+019] ""  iBooster_ADAS,ESC_ADAS,EPS1_ADAS
 SG_ SSecOC_Fresh_EDU_F_03 : 31|8@0+ (1,0) [0|255] ""  iBooster_ADAS,ESC_ADAS,EPS1_ADAS
 SG_ EDU_F_ParkLock_Sts : 139|3@0+ (1,0) [0|7] ""  EPS1_ADAS,ESC_ADAS,iBooster_ADAS
 SG_ EDU_F_ActTq_Q : 101|2@0+ (1,0) [0|3] ""  iBooster_ADAS,EPS1_ADAS,ESC_ADAS
 SG_ EDU_F_ActSpd : 111|16@0- (1,0) [-32768|32767] "rpm"  iBooster_ADAS,EPS1_ADAS,ESC_ADAS
 SG_ EDU_F_ActTq : 127|11@0- (1,0) [-512|511] "Nm"  iBooster_ADAS,ESC_ADAS,EPS1_ADAS
 SG_ EDU_F_ActSpdSig_Q : 132|2@0+ (1,0) [0|3] ""  iBooster_ADAS,ESC_ADAS,EPS1_ADAS
 SG_ EDU_F_ActMod : 99|4@0+ (1,0) [0|15] ""  iBooster_ADAS,EPS1_ADAS,ESC_ADAS
 SG_ EDU_F_HVActvDcha_Sts : 130|3@0+ (1,0) [0|7] ""  iBooster_ADAS,EPS1_ADAS,ESC_ADAS
 SG_ EDU_F_SlipCtrlAct_Sts : 141|2@0+ (1,0) [0|3] ""  iBooster_ADAS,EPS1_ADAS,ESC_ADAS
 SG_ EDU_F_WarningLamp_FS : 142|1@0+ (1,0) [0|1] ""  iBooster_ADAS,EPS1_ADAS,ESC_ADAS
 SG_ EDU_F_HVChkEnd_Sts : 143|1@0+ (1,0) [0|1] ""  iBooster_ADAS,EPS1_ADAS,ESC_ADAS
 SG_ ALIVE_EDU_F_03 : 23|8@0+ (1,0) [0|255] ""  iBooster_ADAS,EPS1_ADAS,ESC_ADAS
 SG_ CRC_EDU_F_03 : 7|16@0+ (1,0) [0|65535] ""  iBooster_ADAS,EPS1_ADAS,ESC_ADAS
 SG_ EDU_F_SlipCtrlOffsetTq : 151|10@0- (1,0) [-512|511] "Nm"  iBooster_ADAS,EPS1_ADAS,ESC_ADAS

BO_ 328 EDU_R_03_Rx: 24 VCU_ADAS
 SG_ SSecOC_MAC_EDU_R_03 : 39|64@0+ (1,0) [0|1.84467440737096E+019] ""  iBooster_ADAS,ESC_ADAS
 SG_ SSecOC_Fresh_EDU_R_03 : 31|8@0+ (1,0) [0|255] ""  iBooster_ADAS,ESC_ADAS
 SG_ EDU_R_SlipCtrlOffsetTq : 159|10@0- (1,0) [-512|511] "Nm"  iBooster_ADAS,ESC_ADAS
 SG_ EDU_R_Trans_gear_Sts : 151|4@0+ (1,0) [0|15] ""  iBooster_ADAS,ESC_ADAS
 SG_ EDU_R_ActSpd : 135|16@0- (1,0) [-32768|32767] "rpm"  ESC_ADAS,iBooster_ADAS
 SG_ EDU_R_ActTq : 119|11@0- (1,0) [-512|511] "Nm"  iBooster_ADAS,ESC_ADAS
 SG_ EDU_R_ActTq_Q : 101|2@0+ (1,0) [0|3] ""  iBooster_ADAS,ESC_ADAS
 SG_ EDU_R_ActSpdSig_Q : 99|2@0+ (1,0) [0|3] ""  ESC_ADAS,iBooster_ADAS
 SG_ EDU_R_ActMod : 107|4@0+ (1,0) [0|15] ""  iBooster_ADAS,ESC_ADAS
 SG_ EDU_R_HVActvDcha_Sts : 124|3@0+ (1,0) [0|7] ""  iBooster_ADAS,ESC_ADAS
 SG_ EDU_R_SlipCtrlAct_Sts : 165|2@0+ (1,0) [0|3] ""  iBooster_ADAS,ESC_ADAS
 SG_ EDU_R_Warninglamp_FS : 96|1@0+ (1,0) [0|1] ""  iBooster_ADAS,ESC_ADAS
 SG_ EDU_R_HVChkEnd_Sts : 97|1@0+ (1,0) [0|1] ""  iBooster_ADAS,ESC_ADAS
 SG_ ALIVE_EDU_R_03 : 23|8@0+ (1,0) [0|255] ""  ESC_ADAS,iBooster_ADAS
 SG_ CRC_EDU_R_03 : 7|16@0+ (1,0) [0|65535] ""  ESC_ADAS,iBooster_ADAS

BO_ 589 CGW_SyncSecOC: 20 CGW_ADAS
 SG_ Syn_RstCtrlVal : 127|20@0+ (1,0) [0|1048575] ""  FCM,EPS1_ADAS,ESC_ADAS,VCU_ADAS
 SG_ Syn_TripCtrlVal : 103|24@0+ (1,0) [0|16777215] ""  FCM,EPS1_ADAS,ESC_ADAS,VCU_ADAS
 SG_ SSecOC_MAC_CGW_Sync : 39|64@0+ (1,0) [0|1.84467440737096E+019] ""  FCM,EPS1_ADAS,ESC_ADAS,VCU_ADAS
 SG_ SSecOC_Fresh_CGW_Sync : 31|8@0+ (1,0) [0|255] ""  FCM,EPS1_ADAS,ESC_ADAS,VCU_ADAS
 SG_ CRC_CGW_Sync : 7|16@0+ (1,0) [0|65535] ""  FCM,EPS1_ADAS,ESC_ADAS,VCU_ADAS
 SG_ ALIVE_CGW_Sync : 23|8@0+ (1,0) [0|255] ""  FCM,EPS1_ADAS,ESC_ADAS,VCU_ADAS

BO_ 1285 NM_FCM: 8 FCM
 SG_ usrData1_FCM_Bit7_ECUSPEC_AWAKE : 31|1@0+ (1,0) [0|1] ""  VCU_ADAS,TPMS,IM,iBooster_ADAS,ESC_ADAS,EPS1_ADAS,CGW_ADAS
 SG_ usrData1_FCM_Bit6_DIAGN_AWAKE : 30|1@0+ (1,0) [0|1] ""  VCU_ADAS,TPMS,IM,iBooster_ADAS,ESC_ADAS,EPS1_ADAS,CGW_ADAS
 SG_ usrData1_FCM_Bit5_IGNITION_AWAKE : 29|1@0+ (1,0) [0|1] ""  VCU_ADAS,TPMS,IM,iBooster_ADAS,ESC_ADAS,EPS1_ADAS,CGW_ADAS
 SG_ usrData1_FCM_Bit4_NETWORK_AWAKE : 28|1@0+ (1,0) [0|1] ""  VCU_ADAS,TPMS,IM,iBooster_ADAS,ESC_ADAS,EPS1_ADAS,CGW_ADAS
 SG_ usrData1_FCM_Bit3_ECUSPEC_WAKEUP : 27|1@0+ (1,0) [0|1] ""  VCU_ADAS,TPMS,IM,iBooster_ADAS,ESC_ADAS,EPS1_ADAS,CGW_ADAS
 SG_ usrData1_FCM_Bit2_NETWORK_WAKEUP : 26|1@0+ (1,0) [0|1] ""  VCU_ADAS,TPMS,IM,iBooster_ADAS,ESC_ADAS,EPS1_ADAS,CGW_ADAS
 SG_ usrData1_FCM_Bit1_RESET_WAKEUP : 25|1@0+ (1,0) [0|1] ""  VCU_ADAS,TPMS,IM,iBooster_ADAS,ESC_ADAS,EPS1_ADAS,CGW_ADAS
 SG_ CtrlBitVector_FCM_Bit7_Res : 15|1@0+ (1,0) [0|1] ""  VCU_ADAS,TPMS,IM,iBooster_ADAS,ESC_ADAS,EPS1_ADAS,CGW_ADAS
 SG_ CtrlBitVector_FCM_Bit6_PNI : 14|1@0+ (1,0) [0|1] ""  VCU_ADAS,TPMS,IM,iBooster_ADAS,ESC_ADAS,EPS1_ADAS,CGW_ADAS
 SG_ CtrlBitVector_FCM_Bit5_Res : 13|1@0+ (1,0) [0|1] ""  VCU_ADAS,TPMS,IM,iBooster_ADAS,ESC_ADAS,EPS1_ADAS,CGW_ADAS
 SG_ CtrlBitVector_FCM_Bit4_ActWake : 12|1@0+ (1,0) [0|1] ""  VCU_ADAS,TPMS,IM,iBooster_ADAS,ESC_ADAS,EPS1_ADAS,CGW_ADAS
 SG_ CtrlBitVector_FCM_Bit3_NMCoord : 11|1@0+ (1,0) [0|1] ""  VCU_ADAS,TPMS,IM,iBooster_ADAS,ESC_ADAS,EPS1_ADAS,CGW_ADAS
 SG_ CtrlBitVector_FCM_Bit2_Res : 10|1@0+ (1,0) [0|1] ""  VCU_ADAS,TPMS,IM,iBooster_ADAS,ESC_ADAS,EPS1_ADAS,CGW_ADAS
 SG_ CtrlBitVector_FCM_Bit1_Res : 9|1@0+ (1,0) [0|1] ""  VCU_ADAS,TPMS,IM,iBooster_ADAS,ESC_ADAS,EPS1_ADAS,CGW_ADAS
 SG_ usrData1_FCM_Bit0_IGN_WAKEUP : 24|1@0+ (1,0) [0|1] ""  VCU_ADAS,TPMS,IM,iBooster_ADAS,ESC_ADAS,EPS1_ADAS,CGW_ADAS
 SG_ usrData0_FCM : 23|8@0+ (1,0) [0|255] ""  VCU_ADAS,TPMS,IM,iBooster_ADAS,ESC_ADAS,EPS1_ADAS,CGW_ADAS
 SG_ srcNodeID_FCM : 7|8@0+ (1,0) [0|127] ""  VCU_ADAS,TPMS,IM,iBooster_ADAS,ESC_ADAS,EPS1_ADAS,CGW_ADAS
 SG_ CtrlBitVector_FCM_Bit0_RMR : 8|1@0+ (1,0) [0|1] ""  VCU_ADAS,TPMS,IM,iBooster_ADAS,ESC_ADAS,EPS1_ADAS,CGW_ADAS
 SG_ usrData2_FCM : 39|8@0+ (1,0) [0|255] ""  VCU_ADAS,TPMS,IM,iBooster_ADAS,ESC_ADAS,EPS1_ADAS,CGW_ADAS
 SG_ usrData4_FCM_PN_Info1 : 55|8@0+ (1,0) [0|255] ""  VCU_ADAS,TPMS,IM,iBooster_ADAS,ESC_ADAS,EPS1_ADAS,CGW_ADAS
 SG_ usrData5_FCM_PN_Info2 : 63|8@0+ (1,0) [0|255] ""  VCU_ADAS,TPMS,IM,iBooster_ADAS,ESC_ADAS,EPS1_ADAS,CGW_ADAS
 SG_ usrData3_FCM : 47|8@0+ (1,0) [0|255] ""  VCU_ADAS,TPMS,IM,iBooster_ADAS,ESC_ADAS,EPS1_ADAS,CGW_ADAS

BO_ 384 FCM_01: 64 FCM
 SG_ FCM_AESA_IndcrLiReq : 359|3@0+ (1,0) [0|7] ""  VCU_ADAS,ESC_ADAS,EPS1_ADAS,CGW_ADAS
 SG_ SSecOC_MAC_FCM_01 : 39|64@0+ (1,0) [0|1.84467440737096E+019] ""  VCU_ADAS,ESC_ADAS,EPS1_ADAS,CGW_ADAS
 SG_ SSecOC_Fresh_FCM_01 : 31|8@0+ (1,0) [0|255] ""  VCU_ADAS,ESC_ADAS,EPS1_ADAS,CGW_ADAS
 SG_ FCM_PDC_BtnLEDSts : 320|1@0+ (1,0) [0|1] ""  VCU_ADAS,ESC_ADAS,EPS1_ADAS,CGW_ADAS
 SG_ FCM_ELK_WarnSts : 391|8@0+ (1,0) [0|255] ""  CGW_ADAS,VCU_ADAS,EPS1_ADAS,ESC_ADAS
 SG_ FCM_ELK_WarnLvl : 153|2@0+ (1,0) [0|3] ""  CGW_ADAS,VCU_ADAS,EPS1_ADAS,ESC_ADAS
 SG_ FCM_AEB_Req : 189|2@0+ (1,0) [0|3] ""  VCU_ADAS,ESC_ADAS,EPS1_ADAS,CGW_ADAS
 SG_ FCM_AEB_BrkDecelVal : 207|11@0+ (0.01,-10) [-10|10] "m/s²"  CGW_ADAS,VCU_ADAS,EPS1_ADAS,ESC_ADAS
 SG_ FCM_AEB_PrefillReq : 192|1@0+ (1,0) [0|1] ""  CGW_ADAS,VCU_ADAS,EPS1_ADAS,ESC_ADAS
 SG_ FCM_DBS_Req : 191|2@0+ (1,0) [0|3] ""  CGW_ADAS,VCU_ADAS,EPS1_ADAS,ESC_ADAS
 SG_ FCM_AEB_FCWAlertReq : 169|2@0+ (1,0) [0|3] ""  CGW_ADAS,VCU_ADAS,EPS1_ADAS,ESC_ADAS
 SG_ FCM_AEB_CnclReasn : 173|4@0+ (1,0) [0|15] ""  CGW_ADAS,VCU_ADAS,EPS1_ADAS,ESC_ADAS
 SG_ FCM_AEB_FCWSnvtySt : 177|2@0+ (1,0) [0|3] ""  CGW_ADAS,VCU_ADAS,EPS1_ADAS,ESC_ADAS
 SG_ FCM_AEB_StsDisp : 180|3@0+ (1,0) [0|7] ""  CGW_ADAS,VCU_ADAS,EPS1_ADAS,ESC_ADAS
 SG_ FCM_AEB_ActvnSt : 340|3@0+ (1,0) [0|7] ""  CGW_ADAS,VCU_ADAS,EPS1_ADAS,ESC_ADAS
 SG_ FCM_ASA_Fuli_MainSignSL : 167|8@0+ (1,0) [0|3] ""  CGW_ADAS,VCU_ADAS,EPS1_ADAS,ESC_ADAS
 SG_ FCM_ASA_TFMapExpired : 104|1@0+ (1,0) [0|1] ""  CGW_ADAS,VCU_ADAS,EPS1_ADAS,ESC_ADAS
 SG_ FCM_ASA_TFDrivgSide : 156|3@0+ (1,0) [0|4] ""  CGW_ADAS,VCU_ADAS,EPS1_ADAS,ESC_ADAS
 SG_ FCM_ASA_ReconstructorSts : 159|3@0+ (1,0) [0|7] ""  CGW_ADAS,VCU_ADAS,EPS1_ADAS,ESC_ADAS
 SG_ FCM_ASA_CondlInfoMapSL : 131|4@0+ (1,0) [0|15] ""  CGW_ADAS,VCU_ADAS,EPS1_ADAS,ESC_ADAS
 SG_ FCM_ASA_SpdLimMai : 151|8@0+ (5,5) [5|255] ""  CGW_ADAS,VCU_ADAS,EPS1_ADAS,ESC_ADAS
 SG_ FCM_LCDAS_SoundWarnReq : 333|1@0+ (1,0) [0|1] ""  VCU_ADAS,ESC_ADAS,EPS1_ADAS,CGW_ADAS
 SG_ FCM_RCTA_RiAlertSt : 383|8@0+ (1,0) [0|255] ""  CGW_ADAS,VCU_ADAS,EPS1_ADAS,ESC_ADAS
 SG_ FCM_RCTA_LeAlertSt : 375|8@0+ (1,0) [0|255] ""  CGW_ADAS,VCU_ADAS,EPS1_ADAS,ESC_ADAS
 SG_ FCM_RCTA_Sts : 367|8@0+ (1,0) [0|255] ""  CGW_ADAS,VCU_ADAS,EPS1_ADAS,ESC_ADAS
 SG_ FCM_LCDAS_RiAlertSt : 348|3@0+ (1,0) [0|7] ""  CGW_ADAS,VCU_ADAS,EPS1_ADAS,ESC_ADAS
 SG_ FCM_LCDAS_LeAlertSt : 351|3@0+ (1,0) [0|7] ""  CGW_ADAS,VCU_ADAS,EPS1_ADAS,ESC_ADAS
 SG_ FCM_LCDAS_Sts : 343|3@0+ (1,0) [0|7] ""  CGW_ADAS,VCU_ADAS,EPS1_ADAS,ESC_ADAS
 SG_ FCM_HzrdLampReq : 321|1@0+ (1,0) [0|1] ""  CGW_ADAS,VCU_ADAS,EPS1_ADAS,ESC_ADAS
 SG_ FCM_SteerWheelTakeoverAlert : 324|3@0+ (1,0) [0|7] ""  CGW_ADAS,VCU_ADAS,EPS1_ADAS,ESC_ADAS
 SG_ FCM_LKA_WarnLvl : 326|2@0+ (1,0) [0|3] ""  CGW_ADAS,VCU_ADAS,EPS1_ADAS,ESC_ADAS
 SG_ FCM_LCS_Actv : 327|1@0+ (1,0) [0|1] ""  CGW_ADAS,VCU_ADAS,EPS1_ADAS,ESC_ADAS
 SG_ FCM_LCA_Actv : 312|1@0+ (1,0) [0|1] ""  CGW_ADAS,VCU_ADAS,EPS1_ADAS,ESC_ADAS
 SG_ FCM_LatFctCnclReason : 315|3@0+ (1,0) [0|7] ""  CGW_ADAS,VCU_ADAS,EPS1_ADAS,ESC_ADAS
 SG_ FCM_LatFctSts : 318|3@0+ (1,0) [0|7] ""  CGW_ADAS,VCU_ADAS,EPS1_ADAS,ESC_ADAS
 SG_ FCM_SteerWhlCtrlOrder : 319|1@0+ (1,0) [0|1] ""  CGW_ADAS,VCU_ADAS,EPS1_ADAS,ESC_ADAS
 SG_ FCM_ADAS_SteerCtrlFac : 311|8@0+ (1,0) [0|100] ""  CGW_ADAS,VCU_ADAS,EPS1_ADAS,ESC_ADAS
 SG_ FCM_ADAS_LatTqReq : 295|16@0+ (0.01,-327.68) [-327.68|327.67] "Nm"  CGW_ADAS,VCU_ADAS,EPS1_ADAS,ESC_ADAS
 SG_ FCM_ADAS_SteerAgReq : 279|16@0+ (0.01,-327.68) [-327.68|327.67] "deg"  CGW_ADAS,VCU_ADAS,EPS1_ADAS,ESC_ADAS
 SG_ FCM_ACC_WarnLvl : 251|2@0+ (1,0) [0|3] ""  CGW_ADAS,VCU_ADAS,EPS1_ADAS,ESC_ADAS
 SG_ FCM_ACC_SetSpdUnit : 249|2@0+ (1,0) [0|3] ""  CGW_ADAS,VCU_ADAS,EPS1_ADAS,ESC_ADAS
 SG_ FCM_ACC_SetSpd : 271|8@0+ (1,0) [0|250] ""  CGW_ADAS,VCU_ADAS,EPS1_ADAS,ESC_ADAS
 SG_ FCM_ACC_SetDst : 263|3@0+ (1,0) [0|7] "m"  CGW_ADAS,VCU_ADAS,EPS1_ADAS,ESC_ADAS
 SG_ FCM_ACC_CuttingInSts : 252|1@0+ (1,0) [0|1] ""  CGW_ADAS,VCU_ADAS,EPS1_ADAS,ESC_ADAS
 SG_ FCM_ACC_OffWeather : 253|1@0+ (1,0) [0|1] ""  CGW_ADAS,VCU_ADAS,EPS1_ADAS,ESC_ADAS
 SG_ FCM_ACC_DrvrBrkReq : 254|1@0+ (1,0) [0|1] ""  CGW_ADAS,VCU_ADAS,EPS1_ADAS,ESC_ADAS
 SG_ FCM_ACC_CtrlActv : 255|1@0+ (1,0) [0|1] ""  CGW_ADAS,VCU_ADAS,EPS1_ADAS,ESC_ADAS
 SG_ FCM_ACC_LeadingCarDisplay : 208|1@0+ (1,0) [0|1] ""  CGW_ADAS,VCU_ADAS,EPS1_ADAS,ESC_ADAS
 SG_ FCM_ACC_CnclReasn : 212|4@0+ (1,0) [0|15] ""  CGW_ADAS,VCU_ADAS,EPS1_ADAS,ESC_ADAS
 SG_ FCM_ACC_Sts : 227|4@0+ (1,0) [0|15] ""  CGW_ADAS,VCU_ADAS,EPS1_ADAS,ESC_ADAS
 SG_ FCM_ACC_TarDst : 239|16@0+ (1,0) [0|65535] "cm"  CGW_ADAS,VCU_ADAS,EPS1_ADAS,ESC_ADAS
 SG_ FCM_ACC_AReq : 223|12@0+ (1,-2048) [-2048|2047] "cm/s²"  CGW_ADAS,VCU_ADAS,EPS1_ADAS,ESC_ADAS
 SG_ FCM_ASA_DrvgContext : 114|3@0+ (1,0) [0|7] ""  CGW_ADAS,VCU_ADAS,EPS1_ADAS,ESC_ADAS
 SG_ FCM_ASA_SpdLimMap : 143|8@0+ (5,5) [5|255] ""  CGW_ADAS,VCU_ADAS,EPS1_ADAS,ESC_ADAS
 SG_ FCM_ASA_SpdUnit : 116|2@0+ (1,0) [0|3] ""  CGW_ADAS,VCU_ADAS,EPS1_ADAS,ESC_ADAS
 SG_ FCM_ASA_OperCtry : 127|12@0+ (1,0) [0|999] ""  CGW_ADAS,VCU_ADAS,EPS1_ADAS,ESC_ADAS
 SG_ FCM_ASA_FailrReasn : 119|3@0+ (1,0) [0|7] ""  CGW_ADAS,VCU_ADAS,EPS1_ADAS,ESC_ADAS
 SG_ FCM_ASA_ConditionalInfo : 111|4@0+ (1,0) [0|15] ""  CGW_ADAS,VCU_ADAS,EPS1_ADAS,ESC_ADAS
 SG_ FCM_ASA_Mod : 107|3@0+ (1,0) [0|7] ""  CGW_ADAS,VCU_ADAS,EPS1_ADAS,ESC_ADAS
 SG_ ALIVE_FCM_01 : 23|8@0+ (1,0) [0|255] ""  CGW_ADAS,VCU_ADAS,EPS1_ADAS,ESC_ADAS
 SG_ CRC_FCM_01 : 7|16@0+ (1,0) [0|65535] ""  CGW_ADAS,VCU_ADAS,EPS1_ADAS,ESC_ADAS
 SG_ FCM_ASA_SpdLimConfd : 103|8@0+ (1,0) [0|100] "%"  CGW_ADAS,VCU_ADAS,EPS1_ADAS,ESC_ADAS
 SG_ FCM_DRA_AESA_DoorUnlock_Req : 174|1@0+ (1,0) [0|1] ""  CGW_ADAS
 SG_ FCM_ADB_Failr : 330|2@0+ (1,0) [0|3] ""  VCU_ADAS,ESC_ADAS,EPS1_ADAS,CGW_ADAS
 SG_ FCM_ADB_Req : 332|2@0+ (1,0) [0|3] ""  VCU_ADAS,ESC_ADAS,EPS1_ADAS,CGW_ADAS

BO_ 416 EDU_F_01_Output: 20 VCU_ADAS
 SG_ EDU_F_Difflock_Sts : 122|3@0+ (1,0) [0|7] ""  ESC_ADAS
 SG_ CRC_EDU_F_01 : 7|16@0+ (1,0) [0|65535] ""  ESC_ADAS
 SG_ ALIVE_EDU_F_01 : 23|8@0+ (1,0) [0|255] ""  ESC_ADAS
 SG_ EDU_F_DCCurrInvt : 151|11@0- (1,0) [-1024|1023] "A"  ESC_ADAS
 SG_ EDU_F_HVVoltInvt : 103|10@0+ (1,0) [0|1023] "V"  ESC_ADAS
 SG_ EDU_F_AvlTorqMax : 119|13@0- (1,0) [-4096|4095] "Nm"  ESC_ADAS
 SG_ EDU_F_AvlTorqMin : 135|13@0- (1,0) [-4096|4095] "Nm"  ESC_ADAS
 SG_ EDU_F_Interlock_Sts : 109|2@0+ (1,0) [0|3] ""  ESC_ADAS

BO_ 419 EDU_R_01_Output: 32 VCU_ADAS
 SG_ EDU_R_Difflock_Sts : 122|3@0+ (1,0) [0|7] ""  ESC_ADAS
 SG_ CRC_EDU_R_01 : 7|16@0+ (1,0) [0|65535] ""  ESC_ADAS
 SG_ ALIVE_EDU_R_01 : 23|8@0+ (1,0) [0|255] ""  ESC_ADAS
 SG_ EDU_R_DCCurrInvt : 151|11@0- (1,0) [-1024|1023] "A"  ESC_ADAS
 SG_ EDU_R_HVVoltInvt : 103|10@0+ (1,0) [0|1023] "V"  ESC_ADAS
 SG_ EDU_R_AvlTorqMax : 119|13@0- (1,0) [-4096|4095] "Nm"  ESC_ADAS
 SG_ EDU_R_AvlTorqMin : 135|13@0- (1,0) [-4096|4095] "Nm"  ESC_ADAS
 SG_ EDU_R_Interlock_Sts : 109|2@0+ (1,0) [0|3] ""  ESC_ADAS

BO_ 422 VCUtoEDU_OutPut1: 48 VCU_ADAS
 SG_ SSecOC_MAC_VCUtoEDU_Output : 39|64@0+ (1,0) [0|1.84467440737096E+019] ""  FCM,ESC_ADAS,EPS1_ADAS,IM
 SG_ SSecOC_Fresh_VCUtoEDU_Output : 31|8@0+ (1,0) [0|255] ""  FCM,ESC_ADAS,EPS1_ADAS,IM
 SG_ VCU_ModeReq_EDU_R : 207|3@0+ (1,0) [0|7] ""  FCM,ESC_ADAS,IM,EPS1_ADAS
 SG_ VCU_Difflockreq_EDU_R : 154|2@0+ (1,0) [0|3] ""  ESC_ADAS,EPS1_ADAS,IM,FCM
 SG_ VCU_Difflockreq_EDU_F : 156|2@0+ (1,0) [0|3] ""  ESC_ADAS,EPS1_ADAS,IM,FCM
 SG_ VCU_HVActvDchaReq_EDU_R : 204|2@0+ (1,0) [0|3] ""  FCM,IM,ESC_ADAS,EPS1_ADAS
 SG_ VCU_HVActvDchaReq_EDU_F : 196|2@0+ (1,0) [0|3] ""  FCM,ESC_ADAS,IM,EPS1_ADAS
 SG_ VCU_TqReq_EDU_R : 183|13@0- (1,0) [-512|511] "Nm"  ESC_ADAS,EPS1_ADAS,IM,FCM
 SG_ VCU_AntiOsciReq_EDU_R : 121|2@0+ (1,0) [0|3] ""  ESC_ADAS,IM,EPS1_ADAS,FCM
 SG_ VCU_MaxAllwdCurrGen_EDU_R : 151|11@0+ (1,0) [0|2047] "A"  EPS1_ADAS,ESC_ADAS,IM,FCM
 SG_ VCU_MaxAllwdCurrMot_EDU_R : 119|11@0+ (1,0) [0|2047] "A"  IM,EPS1_ADAS,FCM,ESC_ADAS
 SG_ VCU_DriveMode : 108|3@0+ (1,0) [0|7] ""  ESC_ADAS,IM,EPS1_ADAS,FCM
 SG_ CRC_VCUtoEDU : 7|16@0+ (1,0) [0|65535] ""  IM,FCM,EPS1_ADAS,ESC_ADAS
 SG_ ALIVE_VCUtoEDU : 23|8@0+ (1,0) [0|255] ""  IM,FCM,EPS1_ADAS,ESC_ADAS
 SG_ VCU_TqReq_EDU_F : 167|13@0- (1,0) [-512|511] "Nm"  EPS1_ADAS,IM,FCM,ESC_ADAS
 SG_ VCU_ModeReq_EDU_F : 199|3@0+ (1,0) [0|7] ""  IM,EPS1_ADAS,FCM,ESC_ADAS
 SG_ VCU_ParklockReq_EDU_F : 170|2@0+ (1,0) [0|3] ""  IM,EPS1_ADAS,FCM,ESC_ADAS
 SG_ VCU_AntiOsciReq_EDU_F : 105|2@0+ (1,0) [0|3] ""  IM,EPS1_ADAS,FCM,ESC_ADAS
 SG_ VCU_MaxAllwdCurrMot_EDU_F : 103|11@0+ (1,0) [0|2047] "A"  IM,EPS1_ADAS,FCM,ESC_ADAS
 SG_ VCU_MaxAllwdCurrGen_EDU_F : 135|11@0+ (1,0) [0|2047] "A"  IM,EPS1_ADAS,FCM,ESC_ADAS
 SG_ VCU_EmgyReq : 124|1@0+ (1,0) [0|1] ""  IM,FCM,EPS1_ADAS,ESC_ADAS
 SG_ VCU_TransgearReq_EDU_R : 140|4@0+ (1,0) [0|15] ""  ESC_ADAS,IM,EPS1_ADAS,FCM

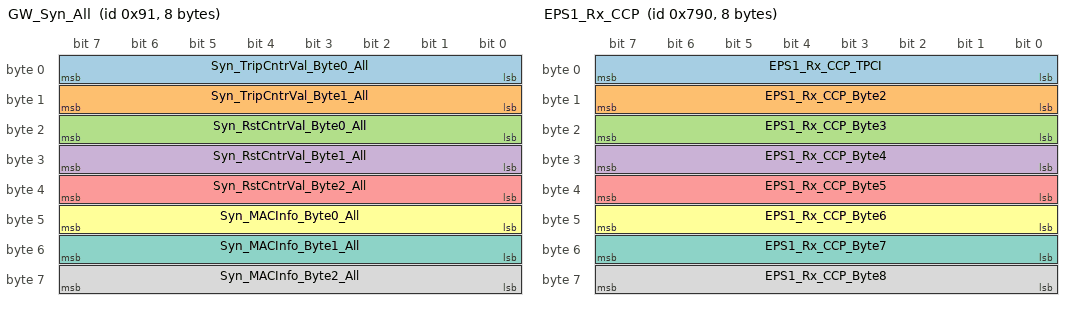
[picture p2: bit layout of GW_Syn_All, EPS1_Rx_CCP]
BO_ 145 GW_Syn_All: 8 CGW_ADAS
 SG_ Syn_TripCntrVal_Byte0_All : 7|8@0+ (1,0) [0|255] ""  VCU_ADAS,EPS1_ADAS
 SG_ Syn_TripCntrVal_Byte1_All : 15|8@0+ (1,0) [0|255] ""  VCU_ADAS,EPS1_ADAS
 SG_ Syn_RstCntrVal_Byte0_All : 23|8@0+ (1,0) [0|255] ""  VCU_ADAS,EPS1_ADAS
 SG_ Syn_RstCntrVal_Byte1_All : 31|8@0+ (1,0) [0|255] ""  VCU_ADAS,EPS1_ADAS
 SG_ Syn_RstCntrVal_Byte2_All : 39|8@0+ (1,0) [0|255] ""  VCU_ADAS,EPS1_ADAS
 SG_ Syn_MACInfo_Byte0_All : 47|8@0+ (1,0) [0|255] ""  VCU_ADAS,EPS1_ADAS
 SG_ Syn_MACInfo_Byte1_All : 55|8@0+ (1,0) [0|255] ""  VCU_ADAS,EPS1_ADAS
 SG_ Syn_MACInfo_Byte2_All : 63|8@0+ (1,0) [0|255] ""  VCU_ADAS,EPS1_ADAS

BO_ 300 iBooster_01_DRIVER_BRAKE_FORCE: 32 iBooster_ADAS
 SG_ iBooster_ExtBrkReqSts : 202|2@0+ (1,0) [0|3] ""  CGW_ADAS,FCM
 SG_ iBooster_ExtReqPrioFlg : 203|1@0+ (1,0) [0|1] ""  CGW_ADAS,FCM
 SG_ iBooster_MstCylBrkPedlActTrvl : 215|12@0+ (0.015625,-5) [-5|47] "mm"  CGW_ADAS,FCM
 SG_ iBooster_DrvrBrkPedlTrvlSts : 185|2@0+ (1,0) [0|3] ""  CGW_ADAS,FCM
 SG_ iBooster_MstCylBrkPedlActTrvlSts : 187|2@0+ (1,0) [0|3] ""  CGW_ADAS,FCM
 SG_ iBooster_DrvrBrkPedlTrvl : 199|12@0+ (0.015625,-5) [-5|47] "mm"  FCM,CGW_ADAS
 SG_ iBooster_StopBackupState2Main : 191|4@0+ (1,0) [0|15] ""  CGW_ADAS,FCM
 SG_ iBooster_TarStgyMod : 243|3@0+ (1,0) [0|7] ""  CGW_ADAS,FCM
 SG_ iBooster_SwCmpbltyIdx : 247|4@0+ (1,0) [0|15] ""  CGW_ADAS,FCM
 SG_ iBooster_ReqFlg_HBC : 240|1@0+ (1,0) [0|1] ""  CGW_ADAS,FCM
 SG_ iBooster_PdelFPotlPSts : 219|2@0+ (1,0) [0|3] ""  CGW_ADAS,FCM
 SG_ iBooster_PdelFPotlP : 239|8@0+ (0.5,0) [0|125] ""  CGW_ADAS,FCM
 SG_ iBooster_MaxMstCylPSts : 217|2@0+ (1,0) [0|3] ""  CGW_ADAS,FCM
 SG_ iBooster_MaxMstCylP : 231|8@0+ (1,0) [0|250] ""  CGW_ADAS,FCM
 SG_ iBooster_DiagFlg : 200|1@0+ (1,0) [0|1] ""  CGW_ADAS,FCM
 SG_ ALIVE_iBooster_01 : 23|8@0+ (1,0) [0|255] ""  FCM,CGW_ADAS
 SG_ CRC_iBooster_01 : 7|16@0+ (1,0) [0|65535] ""  FCM,CGW_ADAS

BO_ 448 FCM_04: 20 FCM
 SG_ SSecOC_MAC_FCM_04 : 39|64@0+ (1,0) [0|1.84467440737096E+019] ""  EPS1_ADAS,VCU_ADAS
 SG_ SSecOC_Fresh_FCM_04 : 31|8@0+ (1,0) [0|255] ""  EPS1_ADAS,VCU_ADAS
 SG_ FCM_LDW_SteerWheelVibrReq : 135|2@0+ (1,0) [0|3] ""  EPS1_ADAS,VCU_ADAS
 SG_ ADAS_FCM_ACC_PopUpMsg : 143|4@0+ (1,0) [0|15] ""  EPS1_ADAS,VCU_ADAS
 SG_ FCM_ACC_StandstillReq : 133|2@0+ (1,0) [0|3] ""  EPS1_ADAS,VCU_ADAS
 SG_ ALIVE_FCM_04 : 23|8@0+ (1,0) [0|255] ""  VCU_ADAS,EPS1_ADAS
 SG_ CRC_FCM_04 : 7|16@0+ (1,0) [0|65535] ""  VCU_ADAS,EPS1_ADAS
 SG_ FCM_ADAS_LatCtrlSteerAnReq : 119|16@0+ (0.0625,-780) [-780|780] "deg"  VCU_ADAS,EPS1_ADAS
 SG_ FCM_ADAS_LatCtrlSts : 98|3@0+ (1,0) [0|7] ""  VCU_ADAS,EPS1_ADAS
 SG_ FCM_ADAS_LatCtrlStsVld : 100|2@0+ (1,0) [0|3] ""  VCU_ADAS,EPS1_ADAS
 SG_ FCM_ADAS_LatCtrlDrvrOvrd : 101|1@0+ (1,0) [0|1] ""  VCU_ADAS,EPS1_ADAS
 SG_ FCM_ADAS_LatCtrlDrvrOvrdVld : 103|2@0+ (1,0) [0|3] ""  VCU_ADAS,EPS1_ADAS
 SG_ FCM_ADAS_LatCtrlTyp : 107|4@0+ (1,0) [0|15] ""  VCU_ADAS,EPS1_ADAS
 SG_ FCM_ADAS_LatCtrlReqVld : 109|2@0+ (1,0) [0|3] ""  VCU_ADAS,EPS1_ADAS
 SG_ FCM_ADAS_LatCtrlReq : 111|2@0+ (1,0) [0|3] ""  VCU_ADAS,EPS1_ADAS
 SG_ FCM_ACC_AccelDecelFlg : 151|2@0+ (1,0) [0|3] ""  EPS1_ADAS,VCU_ADAS

BO_ 856 VCU_06: 24 VCU_ADAS
 SG_ VCU_MaxChrgPower : 175|8@0+ (1,0) [0|255] "kW"  iBooster_ADAS,FCM,EPS1_ADAS,CGW_ADAS,IM
 SG_ VCU_MaxChrgCurrent : 152|9@0+ (1,0) [0|500] "A"  iBooster_ADAS,FCM,EPS1_ADAS,CGW_ADAS,IM
 SG_ VCU_IntSocket230VButtonLEDSts : 121|2@0+ (1,0) [0|0] ""  iBooster_ADAS,FCM,EPS1_ADAS,CGW_ADAS,IM
 SG_ SSecOC_MAC_VCU_06 : 39|64@0+ (1,0) [0|1.84467440737096E+019] ""  iBooster_ADAS,FCM,EPS1_ADAS,CGW_ADAS,IM
 SG_ SSecOC_Fresh_VCU_06 : 31|8@0+ (1,0) [0|255] ""  iBooster_ADAS,FCM,EPS1_ADAS,CGW_ADAS,IM
 SG_ VCU_LV_SoH : 151|8@0+ (1,0) [0|255] ""  FCM,CGW_ADAS,iBooster_ADAS,EPS1_ADAS,IM
 SG_ VCU_LV_Batt_Temp : 143|8@0+ (1,-40) [-40|215] ""  FCM,CGW_ADAS,iBooster_ADAS,EPS1_ADAS,IM
 SG_ ALIVE_VCU_06 : 23|8@0+ (1,0) [0|255] ""  FCM,IM,CGW_ADAS,iBooster_ADAS,EPS1_ADAS
 SG_ CRC_VCU_06 : 7|16@0+ (1,0) [0|65535] ""  FCM,IM,CGW_ADAS,iBooster_ADAS,EPS1_ADAS
 SG_ VCU_IMMO_Sts : 123|2@0+ (1,0) [0|3] ""  iBooster_ADAS,EPS1_ADAS,CGW_ADAS,FCM,IM
 SG_ VCU_LV_Batt_SoC : 135|7@0+ (1,0) [0|100] ""  iBooster_ADAS,EPS1_ADAS,CGW_ADAS,FCM,IM
 SG_ VCU_BattVolt : 111|16@0+ (0.001,0) [0|65.535] "V"  IM,iBooster_ADAS,FCM,EPS1_ADAS,CGW_ADAS

BO_ 1016 TBOX_06: 16 CGW_ADAS
 SG_ ALIVE_TBOX_06 : 23|8@0+ (1,0) [0|255] ""  VCU_ADAS,iBooster_ADAS,EPS1_ADAS
 SG_ CRC_TBOX_06 : 7|16@0+ (1,0) [0|65535] ""  VCU_ADAS,iBooster_ADAS,EPS1_ADAS
 SG_ IgnOffTime : 111|16@0+ (1,0) [0|65535] "s"  iBooster_ADAS,EPS1_ADAS,VCU_ADAS
 SG_ TBOX_OTA_ownCondchk : 103|2@0+ (1,0) [0|3] ""  VCU_ADAS,iBooster_ADAS,EPS1_ADAS
 SG_ TBOX_Flsflg : 98|3@0+ (1,0) [0|7] ""  VCU_ADAS,iBooster_ADAS,EPS1_ADAS
 SG_ TBOX_RemFlsh : 101|3@0+ (1,0) [0|7] ""  VCU_ADAS,iBooster_ADAS,EPS1_ADAS

BO_ 450 EPS_01: 20 EPS1_ADAS
 SG_ SSecOC_MAC_EPS_01 : 39|64@0+ (1,0) [0|1.84467440737096E+019] ""  IM,FCM,CGW_ADAS
 SG_ SSecOC_Fresh_EPS_01 : 31|8@0+ (1,0) [0|255] ""  IM,FCM,CGW_ADAS
 SG_ ALIVE_EPS_01 : 23|8@0+ (1,0) [0|255] ""  IM,FCM,CGW_ADAS
 SG_ CRC_EPS_01 : 7|16@0+ (1,0) [0|65535] ""  IM,FCM,CGW_ADAS
 SG_ EPS_DrvrSteerTqDir : 147|2@0+ (1,0) [0|3] ""  IM,FCM,CGW_ADAS
 SG_ EPS_DrvrSteerTqVld : 130|2@0+ (1,0) [0|3] ""  IM,FCM,CGW_ADAS
 SG_ EPS_DrvrSteerTq : 143|12@0+ (0.01,0) [0|8] "Nm"  IM,FCM,CGW_ADAS
 SG_ EPS_OTARdy_Fb : 132|2@0+ (1,0) [0|3] ""  FCM,IM,CGW_ADAS
 SG_ EPS_DrvrIntvSteerWhlDetd : 133|1@0+ (1,0) [0|1] ""  IM,FCM,CGW_ADAS
 SG_ EPS_DrvrIntvSteerWhlVld : 135|2@0+ (1,0) [0|3] ""  IM,FCM,CGW_ADAS
 SG_ EPS_PinionAg : 119|16@0+ (0.0625,-780) [-780|780] "deg"  IM,FCM,CGW_ADAS
 SG_ EPS_AbortFb : 107|4@0+ (1,0) [0|15] ""  IM,FCM,CGW_ADAS
 SG_ EPS_AdasLatCtrlSts : 109|2@0+ (1,0) [0|3] ""  IM,FCM,CGW_ADAS
 SG_ EPS_AdasLatCtrlStsVld : 111|2@0+ (1,0) [0|3] ""  IM,FCM,CGW_ADAS
 SG_ EPS_AsscMotCrtTq : 103|8@0+ (0.1,0) [0|10] "Nm"  FCM,IM,CGW_ADAS

BO_ 880 EPS_02: 20 EPS1_ADAS
 SG_ EPSdeedlatCtrlMod : 146|2@0+ (1,0) [0|3] ""  IM,CGW_ADAS,FCM
 SG_ ALIVE_EPS_02 : 23|8@0+ (1,0) [0|255] ""  IM,CGW_ADAS,FCM
 SG_ CRC_EPS_02 : 7|16@0+ (1,0) [0|65535] ""  IM,CGW_ADAS,FCM
 SG_ EPS_PwrSplyOverVoltFlt : 149|1@0+ (1,0) [0|1] ""  IM,FCM,CGW_ADAS
 SG_ EPS_PwrSplyUnderVoltFlt : 147|1@0+ (1,0) [0|1] ""  IM,FCM,CGW_ADAS
 SG_ EPS_SnsrSplyVoltFlt : 148|1@0+ (1,0) [0|1] ""  IM,FCM,CGW_ADAS
 SG_ EPS_MotShoOpenFlt : 120|1@0+ (1,0) [0|1] ""  IM,FCM,CGW_ADAS
 SG_ EPS_ThermProtnFlt : 113|1@0+ (1,0) [0|1] ""  IM,FCM,CGW_ADAS
 SG_ EPS_NVMFlt : 117|1@0+ (1,0) [0|1] ""  IM,FCM,CGW_ADAS
 SG_ EPS_RunngRstFlt : 126|1@0+ (1,0) [0|1] ""  IM,FCM,CGW_ADAS
 SG_ EPS_ModSts : 151|2@0+ (1,0) [0|3] ""  IM,CGW_ADAS,FCM
 SG_ EPS_IninSts : 115|1@0+ (1,0) [0|1] ""  IM,FCM,CGW_ADAS
 SG_ EPS_CrtSts : 116|1@0+ (1,0) [0|1] ""  IM,FCM,CGW_ADAS
 SG_ EPS_SteerWhlBackStsFb : 119|2@0+ (1,0) [0|3] ""  IM,FCM,CGW_ADAS
 SG_ EPS_AsscRate : 103|8@0+ (1,0) [0|100] "%"  FCM,IM,CGW_ADAS
 SG_ EPS_AsscMotCrtPwr : 111|8@0+ (5,0) [0|1200] "W"  FCM,IM,CGW_ADAS
 SG_ EPS_TqSnsrSigErr : 112|1@0+ (1,0) [0|1] ""  IM,FCM,CGW_ADAS
 SG_ EPS_TSnsrFlt : 114|1@0+ (1,0) [0|1] ""  IM,FCM,CGW_ADAS
 SG_ EPS_ComLostFlt_ESP : 121|1@0+ (1,0) [0|1] ""  IM,FCM,CGW_ADAS
 SG_ EPS_SpdDataErr : 122|1@0+ (1,0) [0|1] ""  IM,FCM,CGW_ADAS
 SG_ EPS_HwFlt : 123|1@0+ (1,0) [0|1] ""  IM,FCM,CGW_ADAS
 SG_ EPS_RlyFlt : 124|1@0+ (1,0) [0|1] ""  IM,FCM,CGW_ADAS
 SG_ EPS_MotPosnSnsrFlt : 125|1@0+ (1,0) [0|1] ""  IM,FCM,CGW_ADAS
 SG_ EPS_MotCrtFlt : 127|1@0+ (1,0) [0|1] ""  IM,FCM,CGW_ADAS
 SG_ EPS_AsscMotCrt : 135|16@0+ (0.01,-150) [-150|150] "A"  IM,FCM,CGW_ADAS

BO_ 1936 EPS1_Rx_CCP: 8 CGW_ADAS
 SG_ EPS1_Rx_CCP_TPCI : 7|8@0+ (1,0) [0|255] ""  EPS1_ADAS
 SG_ EPS1_Rx_CCP_Byte2 : 15|8@0+ (1,0) [0|255] ""  EPS1_ADAS
 SG_ EPS1_Rx_CCP_Byte3 : 23|8@0+ (1,0) [0|255] ""  EPS1_ADAS
 SG_ EPS1_Rx_CCP_Byte4 : 31|8@0+ (1,0) [0|255] ""  EPS1_ADAS
 SG_ EPS1_Rx_CCP_Byte5 : 39|8@0+ (1,0) [0|255] ""  EPS1_ADAS
 SG_ EPS1_Rx_CCP_Byte6 : 47|8@0+ (1,0) [0|255] ""  EPS1_ADAS
 SG_ EPS1_Rx_CCP_Byte7 : 55|8@0+ (1,0) [0|255] ""  EPS1_ADAS
 SG_ EPS1_Rx_CCP_Byte8 : 63|8@0+ (1,0) [0|255] ""  EPS1_ADAS

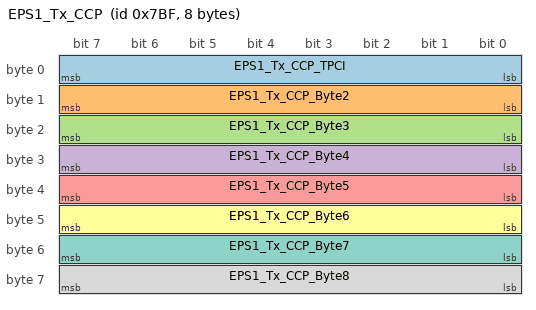
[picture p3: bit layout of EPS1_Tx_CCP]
BO_ 1983 EPS1_Tx_CCP: 8 EPS1_ADAS
 SG_ EPS1_Tx_CCP_TPCI : 7|8@0+ (1,0) [0|255] ""  CGW_ADAS
 SG_ EPS1_Tx_CCP_Byte2 : 15|8@0+ (1,0) [0|255] ""  CGW_ADAS
 SG_ EPS1_Tx_CCP_Byte3 : 23|8@0+ (1,0) [0|255] ""  CGW_ADAS
 SG_ EPS1_Tx_CCP_Byte4 : 31|8@0+ (1,0) [0|255] ""  CGW_ADAS
 SG_ EPS1_Tx_CCP_Byte5 : 39|8@0+ (1,0) [0|255] ""  CGW_ADAS
 SG_ EPS1_Tx_CCP_Byte6 : 47|8@0+ (1,0) [0|255] ""  CGW_ADAS
 SG_ EPS1_Tx_CCP_Byte7 : 55|8@0+ (1,0) [0|255] ""  CGW_ADAS
 SG_ EPS1_Tx_CCP_Byte8 : 63|8@0+ (1,0) [0|255] ""  CGW_ADAS

BO_ 895 EPS_03: 20 EPS1_ADAS
 SG_ ALIVE_EPS_03 : 23|8@0+ (1,0) [0|255] ""  CGW_ADAS
 SG_ CRC_EPS_03 : 7|16@0+ (1,0) [0|65535] ""  CGW_ADAS
 SG_ EPS_SwVersS : 103|8@0+ (1,0) [0|255] ""  CGW_ADAS
 SG_ EPS_PartVers : 111|32@0+ (1,0) [0|4294967295] ""  CGW_ADAS
 SG_ EPS_HwVers : 143|8@0+ (1,0) [0|255] ""  CGW_ADAS
 SG_ EPS_SwVersM : 151|8@0+ (1,0) [0|255] ""  CGW_ADAS

BO_ 2564485392 Diag_Resp_EPS1: 64 EPS1_ADAS
 SG_ Diag_Resp_EPS1 : 7|64@0+ (1,0) [0|1.84467440737096E+019] "N/A"  CGW_ADAS

BO_ 2564485391 Diag_Resp_ESC: 64 ESC_ADAS
 SG_ Diag_Resp_ESC : 7|64@0+ (1,0) [0|1.84467440737096E+019] "N/A"  CGW_ADAS

BO_ 2564485390 Diag_Resp_IM: 64 IM
 SG_ Diag_Resp_IM : 7|64@0+ (1,0) [0|1.84467440737096E+019] "N/A"  CGW_ADAS

BO_ 2564428017 Diag_PhyReq_EPS1: 64 CGW_ADAS
 SG_ Diag_PhyReq_EPS1 : 7|64@0+ (1,0) [0|1.84467440737096E+019] "N/A"  EPS1_ADAS

BO_ 2564427761 Diag_PhyReq_ESC: 64 CGW_ADAS
 SG_ Diag_PhyReq_ESC : 7|64@0+ (1,0) [0|1.84467440737096E+019] "N/A"  ESC_ADAS

BO_ 2564427505 Diag_PhyReq_IM: 64 CGW_ADAS
 SG_ Diag_PhyReq_IM : 7|64@0+ (1,0) [0|1.84467440737096E+019] "N/A"  IM

BO_ 2564485381 Diag_Resp_FCM: 64 FCM
 SG_ Diag_Resp_FCM : 7|64@0+ (1,0) [0|1.84467440737096E+019] "N/A"  CGW_ADAS

BO_ 2564425201 Diag_PhyReq_FCM: 64 CGW_ADAS
 SG_ Diag_PhyReq_FCM : 7|64@0+ (1,0) [0|1.84467440737096E+019] "N/A"  FCM

CM_ BO_ 896 "Last 7 bytes of VIN
VIN_Byte 1 (seventh-last byte)
VIN_Byte 2 (sixth-last byte)
VIN_Byte 3 (fifth-last byte)
VIN_Byte 4 (fourth-last byte)
VIN_Byte 5 (third-last byte)
VIN_Byte 6 (second-last byte)
VIN_Byte 7 (last byte)";
CM_ SG_ 896 VIN_Byte2 "This Signal contains the sixth-last position of the vehicle identification number (positions are coded in ASCII). Bit 0: LSB, Bit 7: MSB";
CM_ SG_ 896 VIN_Byte3 "This Signal contains the fifth-last position of the vehicle identification number (positions are coded in ASCII). Bit 0: LSB, Bit 7: MSB";
CM_ SG_ 896 VIN_Byte5 "This Signal contains the third-last position of the vehicle identification number (positions are coded in ASCII). Bit 0: LSB, Bit 7: MSB";
CM_ SG_ 896 VIN_Byte1 "This Signal contains the seventh-last position of the vehicle identification number (positions are coded in ASCII). Bit 0: LSB, Bit 7: MSB";
CM_ SG_ 896 VIN_Byte6 "This Signal contains the second-last position of the vehicle identification number (positions are coded in ASCII). Bit 0: LSB, Bit 7: MSB";
CM_ SG_ 896 VIN_Byte4 "This Signal contains the fourth-last position of the vehicle identification number (positions are coded in ASCII). Bit 0: LSB, Bit 7: MSB";
CM_ SG_ 896 VIN_Byte7 "This Signal contains the last position of the vehicle identification number (positions are coded in ASCII). Bit 0: LSB, Bit 7: MSB";
CM_ BO_ 264 "BCM Status central lock, anti theft system, Status for doors and flaps like bonnet and trunk 
";
CM_ SG_ 264 SSecOC_MAC_BCM_02 "Short SecOC MAC signal byte 0 on CAN";
CM_ SG_ 264 SSecOC_Fresh_BCM_02 "Short SecOC Fresh signal byte 0 on CAN";
CM_ SG_ 264 ALIVE_BCM_02 "Alive Counter";
CM_ SG_ 264 CRC_BCM_02 "DataID=0x0008. Checksum calculation accordig CAN Specification. Cyclic Redundancy Check";
CM_ SG_ 264 STAT_BonnetAjar "Ajar Bonnet Status ST_CT_BON";
CM_ SG_ 264 STAT_TrunkAjar "Trunk Ajar Door Status";
CM_ SG_ 264 STAT_DoorAjarRR "Ajar Door Rearr Rear Right Status";
CM_ SG_ 264 STAT_DoorAjarPass "Ajar Door Passenger Status";
CM_ SG_ 264 STAT_DoorAjarRL "Ajar Door Rear Left Status
";
CM_ SG_ 264 STAT_DoorAjarDriver "Ajar Door Driver Status 
ST_DSW_DRD";
CM_ SG_ 264 STAT_DoorLockPassenger "Lock Status Passenger Door used as central lock information";
CM_ SG_ 264 STAT_CDL_LED "Status of functional CDL button LED, value 3 represents implausible state";
CM_ SG_ 264 STAT_ATWS "Status Anti theft 
Set: Arming, all trigger conditions will be monitored 
Unset: Disarming, no alarm triggering 
Triggered: Alarm activation due to state change of a trigger 
Partially Set:-Arming, Tilt sensor is not taken into account
";
CM_ SG_ 264 STAT_DoorLockDriver "Lock Status Driver Door used as central lock information";
CM_ BO_ 433 "CES clamp";
CM_ SG_ 433 SSecOC_MAC_CGW_01 "Short SecOC MAC signal byte 0 on CAN";
CM_ SG_ 433 ALIVE_CGW_01 "Alive Counter";
CM_ SG_ 433 CRC_CGW_01 "DataID=0x0018. Checksum calculation accordig CAN Specification. Cyclic Redundancy Check";
CM_ SG_ 433 VEH_State "Vehicle Mode";
CM_ SG_ 433 SSecOC_Fresh_CGW_01 "Short SecOC Fresh signal byte 0 on CAN";
CM_ SG_ 433 CGW_OBDConnectStatus "CGW send the OBD port connection status to All CANFD buses";
CM_ BO_ 1040 "Warning message to HU";
CM_ SG_ 1040 SSecOC_MAC_EPS1WarnMsg "Short SecOC MAC signal byte 0 on CAN";
CM_ SG_ 1040 SSecOC_Fresh_EPS1WarnMsg "Short SecOC Fresh signal byte 0 on CAN";
CM_ SG_ 1040 WarningMessageID_EPS1 "The value (0-65534) defines the warning message ID (details see warning message cataloge). ";
CM_ SG_ 1040 BitBlinking_EPS1 "This parameter defines the blinking frequency of a telltale";
CM_ SG_ 1040 BitStatus_EPS1 "The status defines if a warning message is set or reset";
CM_ SG_ 1040 ALIVE_WarnMsg_EPS1 "Alive Counter";
CM_ SG_ 1040 CRC_WarnMsg_EPS1 "DataID=0x007B. Checksum calculation accordig CAN Specification. Cyclic Redundancy Check";
CM_ BO_ 1039 "Warning message to HU";
CM_ SG_ 1039 SSecOC_MAC_ESCWarnMsg "Short SecOC MAC signal byte 0 on CAN";
CM_ SG_ 1039 SSecOC_Fresh_ESCWarnMsg "Short SecOC Fresh signal byte 0 on CAN";
CM_ SG_ 1039 WarningMessageID_ESC "The value (0-65534) defines the warning message ID (details see warning message cataloge). ";
CM_ SG_ 1039 BitBlinking_ESC "This parameter defines the blinking frequency of a telltale";
CM_ SG_ 1039 BitStatus_ESC "The status defines if a warning message is set or reset";
CM_ SG_ 1039 ALIVE_WarnMsg_ESC "Alive Counter";
CM_ SG_ 1039 CRC_WarnMsg_ESC "DataID=0x007C. Checksum calculation accordig CAN Specification. Cyclic Redundancy Check";
CM_ BO_ 1038 "Warning message to HU";
CM_ SG_ 1038 WarningMessageID_IM "The value (0-65534) defines the warning message ID (details see warning message cataloge). ";
CM_ SG_ 1038 BitBlinking_IM "This parameter defines the blinking frequency of a telltale";
CM_ SG_ 1038 BitStatus_IM "The status defines if a warning message is set or reset";
CM_ SG_ 1038 ALIVE_WarnMsg_IM "Alive Counter";
CM_ SG_ 1038 CRC_WarnMsg_IM "DataID=0x0080. Checksum calculation accordig CAN Specification. Cyclic Redundancy Check";
CM_ SG_ 247 BMS_SOHlastUpdateInterval "Distance driven from the last SOH update";
CM_ SG_ 247 BMS_actPower "calculated actual power of HVB based on actual pack current and pack voltage measurements";
CM_ SG_ 247 BMS_addedEnergyCharging "current amount of received energy during the charging (counting energy while charging)";
CM_ SG_ 247 BMS_BattCellstartframeNum "The starting battery cell number of this frame";
CM_ SG_ 247 BMS_HvBattSocinstalled "INSTALLED SOC from Hv battery";
CM_ SG_ 247 BMS_HvBattSt "HV battery state Statemachine
";
CM_ SG_ 247 BMS_HvBattIMaxDchaLon "maximum long term discharge current of HV battery";
CM_ SG_ 247 BMS_HvBattI "Current of HV battery (positive range -> discharging; negative range ->  charging)";
CM_ SG_ 247 BMS_HvBattRlyPosSt "Positive main relay state";
CM_ SG_ 247 BMS_HvBattRlyNegSt "Negative main relay state";
CM_ SG_ 247 BMS_HvBattT30CVolt "actual voltage of the contactor 12V supply line @ BMS";
CM_ SG_ 247 BMS_HvBattPackUDchaLim "minimum allowed discharge Pack Voltage";
CM_ SG_ 247 BMS_HvBattSoeAct "State of Energy";
CM_ SG_ 247 BMS_HvBattU "Pack Voltage - HVB output";
CM_ SG_ 247 BMS_HvBattPackUChrgnLim "maximum allowed charging Pack voltage ";
CM_ SG_ 247 BMS_HvBattDynChrgILim "dynamic current limit from Hv battery for charging";
CM_ SG_ 247 SSecOC_MAC_BMS_01 "Short SecOC MAC signal byte 0 on CAN";
CM_ SG_ 247 SSecOC_Fresh_BMS_01 "Short SecOC Fresh signal byte 0 on CAN";
CM_ SG_ 247 ALIVE_BMS_01 "Alive Counter";
CM_ SG_ 247 CRC_BMS_01 "DataID=0x0013. Checksum calculation accordig CAN Specification. Cyclic Redundancy Check";
CM_ SG_ 247 BMS_HvBattIMaxChrgLon "maximum long term charge current of HV battery";
CM_ SG_ 247 BMS_HvBattSoh "State of Health of HV battery";
CM_ SG_ 247 BMS_HvBattChrgnAllwd "charging permission flag, based on SOC (Target SOC, actual SOC and max SOC and errors)";
CM_ SG_ 247 BMS_HvBattSdilSt "State of SDIL";
CM_ SG_ 247 BMS_HVBattCellVolt "HV Battery Cell voltage(need to send corresponding with BMS_BattCellstartframeNum)";
CM_ SG_ 247 BMS_HvBattIMaxDchaMidLon "maximum mid-long term discharge current of HV battery";
CM_ SG_ 247 BMS_HvBattUint "Pack Voltage - HVB internal";
CM_ SG_ 247 BMS_HvBattIsoR_status "Status of Isolation monitorgin at BMS – running/dissabled";
CM_ SG_ 247 BMS_HvBattHvilSt "State of HVIL";
CM_ SG_ 247 BMS_HvBattIsoRNegGND_Ohm " Isolation resistance of the HV system Ohm.Isolation resistance from 0 to 10000. If resistance is higher than 10000 than 10000 is sent.";
CM_ SG_ 247 BMS_HvBattIsoRPosGND_Ohm "Isolation resistance of the HV system Ohm.Isolation resistance from 0 to 10000. If resistance is higher than 10000 than 10000 is sent.";
CM_ SG_ 247 BMS_HvBattCellVoltMax "maximum cell voltage";
CM_ SG_ 247 BMS_HvBattCellVoltNom "nominal cell voltage";
CM_ SG_ 247 BMS_HvBattCellVoltMin "minimum cell voltage";
CM_ SG_ 247 BMS_HvBattT30Volt "actual voltage of the BMS 12V supply line @ BMS";
CM_ SG_ 247 BMS_HvBattRlyPrechSt "Precharge switch relay state";
CM_ SG_ 247 BMS_HvBattIMaxChrgMidLon "maximum Mid-long term charge current of HV battery";
CM_ SG_ 247 BMS_HvBattDynDchaILim "dynamic current limit from Hv battery for discharging";
CM_ SG_ 247 BMS_HvBattCellUChrgnLim "maximum allowed charging cell voltage ";
CM_ SG_ 247 BMS_HvBattSocAct_usable "USABLE SOC from Hv battery";
CM_ BO_ 1029 "Warning message to HU";
CM_ SG_ 1029 WarningMessageID_FCM "The value (0-65534) defines the warning message ID (details see warning message cataloge). ";
CM_ SG_ 1029 BitBlinking_FCM "This parameter defines the blinking frequency of a telltale";
CM_ SG_ 1029 BitStatus_FCM "The status defines if a warning message is set or reset";
CM_ SG_ 1029 ALIVE_WarnMsg_FCM "Alive Counter";
CM_ SG_ 1029 CRC_WarnMsg_FCM "DataID=0x007D. Checksum calculation accordig CAN Specification. Cyclic Redundancy Check";
CM_ BO_ 258 "Logical clamps, crank and starter relais (controlled by BCM)  /clamp CES";
CM_ SG_ 258 SSecOC_MAC_BCM_01 "Short SecOC MAC signal byte 0 on CAN";
CM_ SG_ 258 SSecOC_Fresh_BCM_01 "Short SecOC Fresh signal byte 0 on CAN";
CM_ SG_ 258 BCM_STAT_TransportMode "Transport Mode";
CM_ SG_ 258 BCM_KL15_Off_Announcement "Before switching off the KL15 (5s), this signal gets active to inform other ECUs that the KL15 will be disabled in 5seconds if there are still no triggers to keep it active";
CM_ SG_ 258 BCM_ST_KL "Clamp Status";
CM_ SG_ 258 BCM_STAT_Terminal "Represent the status of physical terminal";
CM_ SG_ 258 BCM_STAT_CL30R_L "CL30R clamp status";
CM_ SG_ 258 BCM_STAT_CL30s_L "CL30s clamp status";
CM_ SG_ 258 CRC_BCM_01 "DataID=0x0007. Checksum calculation accordig CAN Specification. Cyclic Redundancy Check";
CM_ SG_ 258 ALIVE_BCM_01 "Alive Counter";
CM_ SG_ 258 BCM_STAT_CL15_L "CL15 clamp status";
CM_ SG_ 2564502513 Diag_FuncReq_Data "Diagnostic Functional Request Data.";
CM_ SG_ 752 SSecOC_MAC_HU_OdoMeter "Short SecOC MAC signal byte 0 on CAN";
CM_ SG_ 752 SSecOC_Fresh_HU_OdoMeter "Short SecOC Fresh signal byte 0 on CAN";
CM_ SG_ 752 ALIVE_HU_OdoMeter "Alive Counter";
CM_ SG_ 752 CRC_HU_OdoMeter "DataID=0x0036. Checksum calculation accordig CAN Specification. Cyclic Redundancy Check";
CM_ SG_ 752 HU_Odometer "Odometer information";
CM_ BO_ 513 "Seat Belt Reminder";
CM_ SG_ 513 SSecOC_MAC_ACM_02 "Short SecOC MAC signal byte 0 on CAN";
CM_ SG_ 513 SSecOC_Fresh_ACM_02 "Short SecOC Fresh signal byte 0 on CAN";
CM_ SG_ 513 ST_SEAT_POS_PAS "Seat Position Passenger(US) (debug)";
CM_ SG_ 513 ST_SEAT_POS_DRV "Seat Position Driver (US) (debug)";
CM_ SG_ 513 ST_PAB_SW "Status of Passenger Airbag OFF switch (PAB-SW) (debug)";
CM_ SG_ 513 ST_PAB_ON "Status of PAB ON LED (debug)";
CM_ SG_ 513 ST_BELT_BUCK_RM "The signal indicates whether the occupant in the rear seat (in the middle) has fastened the seat belt.";
CM_ SG_ 513 ST_IGN_ACM "Status of IGN input of ACM (debug)";
CM_ SG_ 513 ST_CRS_DET "Status of crash detection algorithm in ACM (debug)";
CM_ SG_ 513 ST_COD "Coding Status of ACM (debug)";
CM_ SG_ 513 ST_BELT_BUCK_RR "The signal indicates whether the occupant in the rear seat (right side) has fastened the seat belt..";
CM_ SG_ 513 ST_BELT_BUCK_RL "The signal indicates whether the occupant in the rear seat (left side) has fastened the seat belt.";
CM_ SG_ 513 ST_BELT_BUCK_PS "The signal indicates whether the passenger has fastened the seat belt.";
CM_ SG_ 513 ST_SEAT_OCCU_PS "This signal gives the occupancy information from the passenger seat. For US vehicles the status 'Seat occupied by child seat' is also displayed.";
CM_ SG_ 513 ST_BELT_BUCK_DR "The signal indicates whether the driver has fastened the seat belt.";
CM_ SG_ 513 ST_PAB_OFF "Status of PAB OFF LED (debug)";
CM_ SG_ 513 ALIVE_ACM_02 "Alive Counter";
CM_ SG_ 513 CRC_ACM_02 "DataID=0x0002. Checksum calculation accordig CAN Specification. Cyclic Redundancy Check";
CM_ SG_ 2564485412 Diag_Resp_RadarRR "Diagnostic physical response data from RadarRR";
CM_ SG_ 2564485411 Diag_Resp_RadarRL "Diagnostic physical response data from RadarRL";
CM_ SG_ 2564485404 Diag_Resp_RF "Diagnostic physical response data from RF";
CM_ SG_ 2564433137 Diag_PhyReq_RadarRR "Diagnostic physical request data to RadarRR";
CM_ SG_ 2564432881 Diag_PhyReq_RadarRL "Diagnostic physical request data to RadarRL";
CM_ SG_ 2564431089 Diag_PhyReq_RF "Diagnostic physical request data to RF";
CM_ BO_ 1305 "Networkmanagement message";
CM_ BO_ 1284 "Networkmanagement message";
CM_ SG_ 594 SAS_TrimmingSts "SAS trimming status";
CM_ SG_ 594 SAS_CalibrationSts "SAS calibration status";
CM_ SG_ 594 SAS_FailureSts "SAS failure status";
CM_ SG_ 594 SAS_SteerWheelRotSpd "Steering wheel rotational speed";
CM_ SG_ 594 SAS_SteerWheelAngle "Actual steering wheel angle";
CM_ SG_ 594 CRC_SCM_02 "DataID=0x0049. Checksum calculation accordig CAN Specification. Cyclic Redundancy Check";
CM_ SG_ 594 ALIVE_SCM_02 "Alive Counter";
CM_ BO_ 592 "This message includes the status information of light lever left and wiper lever right, included with rolling counter and checksum.";
CM_ SG_ 592 SCM_SteeringWheel_rotation_flag "Steering Wheel Rotation Status after IGN ON";
CM_ SG_ 592 SCM_IHBC_MenuReq "IHBC switch request from SCM (Tip SW)";
CM_ SG_ 592 SCM_IHBC_MenuReqInvalid "Indicating the SCM_IHBC_MenuReq is valid or invalid ";
CM_ SG_ 592 SCM_SW_MasterLightSwitch "Combination of the all Light switches";
CM_ SG_ 592 SCM_SW_DaytimeLight "Signal from SCM to Indicate daytime running light swith status (Tip SW)";
CM_ SG_ 592 SCM_SW_DaytimeLightInvalid "Indicating the SCM_SW_DaytimeLight is valid or invalid ";
CM_ SG_ 592 SCM_SW_Trip "Trip to page up/down";
CM_ SG_ 592 SCM_Req_TurnIndicationAct "Signal from SCM to request the turn indication active (Block SW)";
CM_ SG_ 592 SCM_RearWipingMode "Signal from SCM to request Rear wiping mode (Block SW)";
CM_ SG_ 592 SCM_SW_FrontFogLight "Signal from SCM to Indicate front fog light swith status (Tip SW)";
CM_ SG_ 592 SCM_SW_FrontFogLightInvalid "Indicating the SCM_SW_FrontFogLight is valid or invalid ";
CM_ SG_ 592 SCM_SW_RearFogLight "Signal from SCM to Indicate rear fog light swith status (Tip SW)";
CM_ SG_ 592 SCM_SW_RearFogLightInvalid "Indicating the SCM_SW_RearFogLight is valid or invalid ";
CM_ SG_ 592 SCM_WipingInterval_Sensitvity "The signal indicates the stage preselection of the wiper interval function (Block SW)";
CM_ SG_ 592 SCM_FrontWipingMode "Signal from SCM to request front wiping mode (Block SW)";
CM_ SG_ 592 SCM_SW_FlashLightSts "Signal from SCM to Indicate flash light swith status (Tip SW)";
CM_ SG_ 592 SCM_SW_FlashLightStsInvalid "Indicating the SCM_SW_FlashLightSts is valid or invalid ";
CM_ SG_ 592 SCM_SW_RWasherSts "Signal from SCM to indicate the rear window washer  switch status (Tip SW)";
CM_ SG_ 592 SCM_SW_RWasherStsInvalid "Indicating the SCM_SW_RWasherSts is valid or invalid ";
CM_ SG_ 592 SCM_SW_FWasherSts "Signal from SCM to indicate the front window washer switch status (Tip SW)";
CM_ SG_ 592 SCM_SW_FWasherStsInvalid "Indicating the SCM_SW_FWasherSts is valid or invalid ";
CM_ SG_ 592 SCM_SW_HighBeam "Signal from SCM to Indicate high beam swith status (Tip SW)";
CM_ SG_ 592 SCM_SW_HighBeamInvalid "Indicating the SCM_SW_HighBeam is valid or invalid ";
CM_ SG_ 592 ALIVE_SCM_01 "Alive Counter";
CM_ SG_ 592 CRC_SCM_01 "DataID=0x0048. Checksum calculation accordig CAN Specification. Cyclic Redundancy Check";
CM_ SG_ 389 FCM_PDC_ROR_USSSts "USS Status RearOuter Right";
CM_ SG_ 389 FCM_PDC_ROL_USSSts "USS Status Rear Outer Left";
CM_ SG_ 389 FCM_PDC_FOR_USSSts "USS Status Front Outer Right";
CM_ SG_ 389 FCM_PDC_FOL_USSSts "USS Status Front Outer Left";
CM_ SG_ 389 FCM_PDC_RIR_USSSts "USS Status Rear Inner Right";
CM_ SG_ 389 FCM_PDC_RIL_USSSts "USS Status Rear Inner Left";
CM_ SG_ 389 FCM_PDC_RearAudWarn "Rear PDC audible warning";
CM_ SG_ 389 FCM_PDC_FrontAudWarn "Front PDC audible warning";
CM_ SG_ 389 FCM_PDC_FailrWarn "PDC failure  warning sound";
CM_ SG_ 389 ALIVE_FCM_05 "Alive Counter";
CM_ SG_ 389 CRC_FCM_05 "DataID=0x0044. Checksum calculation accordig CAN Specification. Cyclic Redundancy Check";
CM_ SG_ 389 FCM_PDC_ToneVol "PDC Tone Volume";
CM_ SG_ 389 FCM_PDC_Mode "PDC MODE active/standby/error...";
CM_ SG_ 389 FCM_PDC_Distance_ROR "PDC distance of Rear Outer Right sensor";
CM_ SG_ 389 FCM_PDC_Distance_RIR "PDC distance of Rear Inner Right sensor";
CM_ SG_ 389 FCM_PDC_Distance_RIL "PDC distance of Rear Inner Left sensor";
CM_ SG_ 389 FCM_PDC_Distance_ROL "PDC distance of Rear Outer Left sensor";
CM_ SG_ 389 FCM_PDC_Distance_FOR "PDC distance of Front Outer Right sensor";
CM_ SG_ 389 FCM_PDC_Distance_FIR "PDC distance of Front Inner Right sensor";
CM_ SG_ 389 FCM_PDC_Distance_FIL "PDC distance of Front Inner Left sensor";
CM_ SG_ 389 FCM_PDC_Distance_FOL "PDC distance of Front Outer Left sensor";
CM_ SG_ 389 FCM_PDC_FIR_USSSts "USS Status Front Inner Right";
CM_ SG_ 389 FCM_PDC_FIL_USSSts "USS Status Front Inner Left";
CM_ SG_ 389 FCM_PDC_FltMod "PDC fault mode";
CM_ SG_ 389 FCM_PDC_USSCoverSt "When one or more USS is covered, PDC should send it to HMI to make relevant display";
CM_ SG_ 389 FCM_PDC_FrntPDCBtnSts "PDC front soft button activation deaction";
CM_ SG_ 272 VCU_AccelPedalSts "Accelerator Pedal Status";
CM_ SG_ 272 SSecOC_MAC_VCU_05 "Short SecOC MAC signal byte 0 on CAN";
CM_ SG_ 272 SSecOC_Fresh_VCU_05 "Short SecOC Fresh signal byte 0 on CAN";
CM_ SG_ 272 VCU_CC_SpdLim_Sts "Cruise Control and Speed limiter ";
CM_ SG_ 272 ALIVE_VCU_05 "Alive Counter";
CM_ SG_ 272 CRC_VCU_05 "DataID=0x0060. Checksum calculation accordig CAN Specification. Cyclic Redundancy Check";
CM_ SG_ 272 VCU_ActSt "VCU Actual Status";
CM_ SG_ 272 VCU_GearSig "Gear signal";
CM_ SG_ 272 VCU_GearSig_Q "Effective bit of gear signal";
CM_ SG_ 327 SSecOC_MAC_EDU_F_03 "Short SecOC MAC signal byte 0 on CAN";
CM_ SG_ 327 SSecOC_Fresh_EDU_F_03 "Short SecOC Fresh signal byte 0 on CAN";
CM_ SG_ 327 EDU_F_ParkLock_Sts "State Parklock EDU Front";
CM_ SG_ 327 EDU_F_ActTq_Q "Qualifier Current Torque Signal EDU Front";
CM_ SG_ 327 EDU_F_ActSpd "Actual Motor Speed EDU Front";
CM_ SG_ 327 EDU_F_ActTq "Actual torque axial Level EDU Front";
CM_ SG_ 327 EDU_F_ActSpdSig_Q "Qualifier Current Speed Signal EDU Front";
CM_ SG_ 327 EDU_F_ActMod "Actual Mode EDU Front";
CM_ SG_ 327 EDU_F_HVActvDcha_Sts "State High-voltage active discharge EDU Front";
CM_ SG_ 327 EDU_F_SlipCtrlAct_Sts "State Slip Control EDU Front";
CM_ SG_ 327 EDU_F_WarningLamp_FS "Warning lamp (functional safety) EDU Front";
CM_ SG_ 327 EDU_F_HVChkEnd_Sts "State High Voltage Detection Completion EDU Front";
CM_ SG_ 327 ALIVE_EDU_F_03 "Alive Counter";
CM_ SG_ 327 CRC_EDU_F_03 "DataID=0x001C. Checksum calculation accordig CAN Specification. Cyclic Redundancy Check";
CM_ SG_ 327 EDU_F_SlipCtrlOffsetTq "Offset Slip Torque EDU Front";
CM_ SG_ 328 SSecOC_MAC_EDU_R_03 "Short SecOC MAC signal byte 0 on CAN";
CM_ SG_ 328 SSecOC_Fresh_EDU_R_03 "Short SecOC Fresh signal byte 0 on CAN";
CM_ SG_ 328 EDU_R_SlipCtrlOffsetTq "Offset Slip Torque EDU Rear";
CM_ SG_ 328 EDU_R_Trans_gear_Sts "State Transmission Gear Coupling EDU Rear";
CM_ SG_ 328 EDU_R_ActSpd "Actual Motor Speed EDU Rear";
CM_ SG_ 328 EDU_R_ActTq "Actual Torque axial level EDU Rear";
CM_ SG_ 328 EDU_R_ActTq_Q "Qualifier Current Torque Signal Flag Rear";
CM_ SG_ 328 EDU_R_ActSpdSig_Q "Qualifier Current Speed Signal EDU Rear";
CM_ SG_ 328 EDU_R_ActMod "Actual Mode EDU Rear";
CM_ SG_ 328 EDU_R_HVActvDcha_Sts "State High-voltage active discharge EDU Rear";
CM_ SG_ 328 EDU_R_SlipCtrlAct_Sts "State Slip Control EDU Rear";
CM_ SG_ 328 EDU_R_Warninglamp_FS "Warning lamp (functional safety) EDU Rear";
CM_ SG_ 328 EDU_R_HVChkEnd_Sts "State High Voltage Detection Completion EDU Rear";
CM_ SG_ 328 ALIVE_EDU_R_03 "Alive Counter";
CM_ SG_ 328 CRC_EDU_R_03 "DataID=0x0020. Checksum calculation accordig CAN Specification. Cyclic Redundancy Check";
CM_ BO_ 589 "SecOC Sync Message";
CM_ SG_ 589 SSecOC_MAC_CGW_Sync "Short SecOC MAC signal byte 0 on CAN";
CM_ SG_ 589 SSecOC_Fresh_CGW_Sync "Short SecOC Fresh signal byte 0 on CAN";
CM_ SG_ 589 CRC_CGW_Sync "DataID=0x009D. Checksum calculation accordig CAN Specification. Cyclic Redundancy Check";
CM_ SG_ 589 ALIVE_CGW_Sync "Alive Counter";
CM_ BO_ 1285 "Networkmanagement message";
CM_ SG_ 384 FCM_AESA_IndcrLiReq "AutomaticEmergencyStoppingAssist hazard light warning request";
CM_ SG_ 384 SSecOC_MAC_FCM_01 "Short SecOC MAC signal byte 0 on CAN";
CM_ SG_ 384 SSecOC_Fresh_FCM_01 "Short SecOC Fresh signal byte 0 on CAN";
CM_ SG_ 384 FCM_PDC_BtnLEDSts "ParkDistanceControl LED button status";
CM_ SG_ 384 FCM_ELK_WarnSts "EmergencyLaneKeep warning level status";
CM_ SG_ 384 FCM_ELK_WarnLvl "EmergencyLaneKeep, warning level of ELK function";
CM_ SG_ 384 FCM_AEB_Req "AEB braking request to ESC";
CM_ SG_ 384 FCM_AEB_BrkDecelVal "AutomatedEmergencyBraking bake deceleration request value";
CM_ SG_ 384 FCM_AEB_PrefillReq "AutomatedEmergencyBraking brake prefill request";
CM_ SG_ 384 FCM_DBS_Req "DBS (Dynamic Brake Support) braking request for AEB function to ESC";
CM_ SG_ 384 FCM_AEB_FCWAlertReq "AutomatedEmergencyBraking ForwardCollisionWarning request";
CM_ SG_ 384 FCM_AEB_CnclReasn "AutomatedEmergencyBraking reason of AEB cancellation for development purposes";
CM_ SG_ 384 FCM_AEB_FCWSnvtySt "AutomatedEmergencyBraking ForwardCollisionWarning sensitivity state";
CM_ SG_ 384 FCM_AEB_StsDisp "AutomatedEmergencyBraking function status for telltale request on HU";
CM_ SG_ 384 FCM_AEB_ActvnSt "Automated Emergency Braking Activation Status";
CM_ SG_ 384 FCM_ASA_Fuli_MainSignSL "FSA: Fusion Speed Assist (INEOS ASA). Represents the speed limit value from vision.";
CM_ SG_ 384 FCM_ASA_TFMapExpired "FSA: Fusion Speed Assist (INEOS ASA). Flag to indicate if the Map is expired.";
CM_ SG_ 384 FCM_ASA_TFDrivgSide "FSA: Fusion Speed Assist (INEOS ASA). Parameter describes, the driving side of the ego vehicle according to the navigation data.";
CM_ SG_ 384 FCM_ASA_ReconstructorSts "FSA: Fusion Speed Assist (INEOS ASA). Status of the E-Horizon Reconstructor.";
CM_ SG_ 384 FCM_ASA_CondlInfoMapSL "FSA: Fusion Speed Assist (INEOS ASA). If conditional circumstances are affecting the pValue of the main speed limit display, the reason is provided by the signal.";
CM_ SG_ 384 FCM_ASA_SpdLimMai "FSA: Fusion Speed Assist (INEOS ASA). The speed limit pValue claculated by the Fusion.";
CM_ SG_ 384 FCM_LCDAS_SoundWarnReq "LaneChangeDecisionAssist Audible Warning level 2 request";
CM_ SG_ 384 FCM_RCTA_RiAlertSt "RearCrossTrafficAlert, Flag to indicate RCTA alert to the right, u8 (bits 3 and 4)";
CM_ SG_ 384 FCM_RCTA_LeAlertSt "RearCrossTrafficAlert, Flag to indicate RCTA alert to the left, u8 (bits 5 and 6)";
CM_ SG_ 384 FCM_RCTA_Sts "RearCrossTrafficAlert, Flag to indicate if RCTA is active, u8 (bit 7)";
CM_ SG_ 384 FCM_LCDAS_RiAlertSt "LaneChangeDecisionAid, Flag to indicate alert to the right, u8 (bits 3 and 4)";
CM_ SG_ 384 FCM_LCDAS_LeAlertSt "LaneChangeDecisionAid, Flag to indicate alert to the left, u8 (bits 5 and 6)";
CM_ SG_ 384 FCM_LCDAS_Sts "Lane Change Decision Aid status of function";
CM_ SG_ 384 FCM_HzrdLampReq "LKA Lane Keep Assist, LCS Lane Centering Support, Request to set the hazard lamp probably nobody uses it.";
CM_ SG_ 384 FCM_SteerWheelTakeoverAlert "LKA Lane Keep Assist, LCS Lane Centering Support, Takeover alert for the driver to put hands on steering wheel";
CM_ SG_ 384 FCM_LKA_WarnLvl "LKA Lane Keep Assist, warning level of LKA function will be removed";
CM_ SG_ 384 FCM_LCS_Actv "LCS Lane Centering Support, flag to indicate if LCS function is active";
CM_ SG_ 384 FCM_LCA_Actv "LaneCenteringAssist, flag to indicate if LCA function is active";
CM_ SG_ 384 FCM_LatFctCnclReason "LKA Lane Keep Assist, LCS Lane Centering Support, cancel reason of Lateral function, ENUM to be defined";
CM_ SG_ 384 FCM_LatFctSts "LKA Lane Keep Assist, LCS Lane Centering Support, information about the status of lateral function";
CM_ SG_ 384 FCM_SteerWhlCtrlOrder "LKA Lane Keep Assist, LCS Lane Centering Support, Flag indicating if lateral function requests to take control of the steering wheel";
CM_ SG_ 384 FCM_ADAS_SteerCtrlFac "ADAS steering control factor will be removed";
CM_ SG_ 384 FCM_ADAS_LatTqReq "ADAS lateral torque request for steering functions(for torque interface)";
CM_ SG_ 384 FCM_ADAS_SteerAgReq "ADAS steering angle request from steering function (for angle interface)";
CM_ SG_ 384 FCM_ACC_WarnLvl "AdaptiveCruiseControl, warning level of ACC function";
CM_ SG_ 384 FCM_ACC_SetSpdUnit "AdaptiveCruiseControl, Unit of the set speed limit: km/h, miles/h; dependent on the country";
CM_ SG_ 384 FCM_ACC_SetSpd "AdaptiveCruiseControl, Current set speed to display";
CM_ SG_ 384 FCM_ACC_SetDst "AdaptiveCruiseControl, Current set distance to display";
CM_ SG_ 384 FCM_ACC_CuttingInSts "AdaptiveCruiseControl, Is cutting in target detected will be removed";
CM_ SG_ 384 FCM_ACC_OffWeather "AdaptiveCruiseControl, flag to indicate if ACC is off due to weather will be removed";
CM_ SG_ 384 FCM_ACC_DrvrBrkReq "AdaptiveCruiseControl, flag to indicate if there is a brake request by the driver";
CM_ SG_ 384 FCM_ACC_CtrlActv "AdaptiveCruiseControl, flag to indicate if ACC is active";
CM_ SG_ 384 FCM_ACC_LeadingCarDisplay "AdaptiveCruiseControl, information, if leading car display is requested";
CM_ SG_ 384 FCM_ACC_CnclReasn "AdaptiveCruiseControll, cancel reason of ACC function, ENUM to be defined";
CM_ SG_ 384 FCM_ACC_Sts "AdaptiveCruiseControl, information about the status of ACC function";
CM_ SG_ 384 FCM_ACC_TarDst "AdaptiveCruiseControl, distance to the ACC target";
CM_ SG_ 384 FCM_ACC_AReq "AdaptiveCruiseControl, requested ACC Target Acceleration/Deceleration value";
CM_ SG_ 384 FCM_ASA_DrvgContext "FSA: Fusion Speed Assist (INEOS ASA). Provides driving context of the EGO vehicle based on current location. ";
CM_ SG_ 384 FCM_ASA_SpdLimMap "FSA: Fusion Speed Assist (INEOS ASA). The speed limit pValue claculated by the Fusion";
CM_ SG_ 384 FCM_ASA_SpdUnit "FSA: Fusion Speed Assist (INEOS ASA). Output Speed Limit pUnit based on EGO vehicle location and country. ";
CM_ SG_ 384 FCM_ASA_OperCtry "FSA: Fusion Speed Assist (INEOS ASA). ISO 3166-1 based numeric country code output retrieved from input ADASIS data.";
CM_ SG_ 384 FCM_ASA_FailrReasn "FSA: Fusion Speed Assist (INEOS ASA). Failure reason of the function.";
CM_ SG_ 384 FCM_ASA_ConditionalInfo "FSA: Fusion Speed Assist (INEOS ASA). If conditional circumstances are affecting the pValue of the main speed limit display, the reason is provided by the signal.";
CM_ SG_ 384 FCM_ASA_Mod "FSA: Fusion Speed Assist (INEOS ASA). Status Indicates operating mode of the function.";
CM_ SG_ 384 ALIVE_FCM_01 "Alive Counter";
CM_ SG_ 384 CRC_FCM_01 "DataID=0x002A. Checksum calculation accordig CAN Specification. Cyclic Redundancy Check";
CM_ SG_ 384 FCM_ASA_SpdLimConfd "FSA: Fusion Speed Assist (INEOS ASA). Confidence pValue of the speed limit computed by fusion. ";
CM_ SG_ 384 FCM_DRA_AESA_DoorUnlock_Req "The signal will be used to trigger the DoorUnlock once the AESA control is done and the vehicle is brought to stop.";
CM_ SG_ 384 FCM_ADB_Failr "AdaptiveDrivingBeam Light Assist Failure";
CM_ SG_ 384 FCM_ADB_Req "AdaptiveDrivingBeam Light Assist Request lowbeam highbeam";
CM_ SG_ 416 EDU_F_Difflock_Sts "State Difflock EDU Front";
CM_ SG_ 416 CRC_EDU_F_01 "DataID=0x001A. Checksum calculation accordig CAN Specification. Cyclic Redundancy Check";
CM_ SG_ 416 ALIVE_EDU_F_01 "Alive Counter";
CM_ SG_ 416 EDU_F_DCCurrInvt "DC current Inverter EDU Front ";
CM_ SG_ 416 EDU_F_HVVoltInvt "HV Voltage Inverter EDU Front";
CM_ SG_ 416 EDU_F_AvlTorqMax "Available torque max EDU Front";
CM_ SG_ 416 EDU_F_AvlTorqMin "Available torque min EDU Front ";
CM_ SG_ 416 EDU_F_Interlock_Sts "State Interlock EDU Front";
CM_ SG_ 419 EDU_R_Difflock_Sts "State Difflock EDU Rear";
CM_ SG_ 419 CRC_EDU_R_01 "DataID=0x001E. Checksum calculation accordig CAN Specification. Cyclic Redundancy Check";
CM_ SG_ 419 ALIVE_EDU_R_01 "Alive Counter";
CM_ SG_ 419 EDU_R_DCCurrInvt "DC Current Inverter EDU Rear";
CM_ SG_ 419 EDU_R_HVVoltInvt "HV Voltage Inverter EDU Rear";
CM_ SG_ 419 EDU_R_AvlTorqMax "Available torque max EDU Rear";
CM_ SG_ 419 EDU_R_AvlTorqMin "Available torque min EDU Rear";
CM_ SG_ 419 EDU_R_Interlock_Sts "State Interlock EDU Rear";
CM_ SG_ 422 SSecOC_MAC_VCUtoEDU_Output "Short SecOC MAC signal byte 0 on CAN";
CM_ SG_ 422 SSecOC_Fresh_VCUtoEDU_Output "Short SecOC Fresh signal byte 0 on CAN";
CM_ SG_ 422 VCU_ModeReq_EDU_R "Request EDU Rear Mode (Torque Mode, Standby, Freewheeling)";
CM_ SG_ 422 VCU_Difflockreq_EDU_R "Request Difflock state EDU Rear";
CM_ SG_ 422 VCU_Difflockreq_EDU_F "Request Difflock state EDU Front";
CM_ SG_ 422 VCU_HVActvDchaReq_EDU_R "Request: High-voltage active discharge of rear EDU. HVActiveDischargeRequest  (discharge, no_discharge)";
CM_ SG_ 422 VCU_HVActvDchaReq_EDU_F "Request: High-voltage active discharge request of front EDU.";
CM_ SG_ 422 VCU_TqReq_EDU_R "Target Torque Motorlevel EDU Rear";
CM_ SG_ 422 VCU_AntiOsciReq_EDU_R "Request Anti Oscillation state EDU Rear";
CM_ SG_ 422 VCU_MaxAllwdCurrGen_EDU_R "maximum allowed inverter current generation (generator mode) for short term EDU Rear";
CM_ SG_ 422 VCU_MaxAllwdCurrMot_EDU_R "maximum allowed inverter current consumption (motor mode) for short term EDU Rear";
CM_ SG_ 422 VCU_DriveMode "Status Drive Mode";
CM_ SG_ 422 CRC_VCUtoEDU "DataID=0x0071. Checksum calculation accordig CAN Specification. Cyclic Redundancy Check";
CM_ SG_ 422 ALIVE_VCUtoEDU "Alive Counter";
CM_ SG_ 422 VCU_TqReq_EDU_F "Target Torque Motorlevel EDU Front";
CM_ SG_ 422 VCU_ModeReq_EDU_F "Request EDU Front Mode (Torque Mode, Standby, Freewheeling) ";
CM_ SG_ 422 VCU_ParklockReq_EDU_F "Request Parklock (engange parklock, disengange parklock, init)";
CM_ SG_ 422 VCU_AntiOsciReq_EDU_F "Request Anti Oscillation state EDU Front";
CM_ SG_ 422 VCU_MaxAllwdCurrMot_EDU_F "maximum allowed inverter current consumption (motor mode) for short term EDU Front";
CM_ SG_ 422 VCU_MaxAllwdCurrGen_EDU_F "maximum allowed inverter current generation (generator mode) for short term EDU Front";
CM_ SG_ 422 VCU_EmgyReq "Emergency release request; note: for CV degradation concept necessary (action TBD)";
CM_ SG_ 422 VCU_TransgearReq_EDU_R "Request Transmission Gear Coupling EDU Rear";
CM_ SG_ 145 Syn_TripCntrVal_Byte0_All "Trip Counter Value";
CM_ SG_ 145 Syn_TripCntrVal_Byte1_All "Trip Counter Value";
CM_ SG_ 145 Syn_RstCntrVal_Byte0_All "Reset Counter Value";
CM_ SG_ 145 Syn_RstCntrVal_Byte1_All "Reset Counter Value";
CM_ SG_ 145 Syn_RstCntrVal_Byte2_All "Reset Counter Value";
CM_ SG_ 145 Syn_MACInfo_Byte0_All "Synchronization message Mac Info";
CM_ SG_ 145 Syn_MACInfo_Byte1_All "Synchronization message Mac Info";
CM_ SG_ 145 Syn_MACInfo_Byte2_All "Synchronization message Mac Info";
CM_ SG_ 300 iBooster_ExtBrkReqSts "External brake request stateStatus of external brake request (EBR) function.";
CM_ SG_ 300 iBooster_ExtReqPrioFlg "Whether external request is executedFlag to signal if driver request or external brake request is dominating.";
CM_ SG_ 300 iBooster_MstCylBrkPedlActTrvl "Actual stroke of master cylinder push rodCurrent value for output rod in iBooster indicates the shifted volume in master cylinder. Gives information, if the compensation port is closed.Includes e.g. the pedal force compensation control for Hev.";
CM_ SG_ 300 iBooster_DrvrBrkPedlTrvlSts "Driver target push rod stroke state positionQualifier for sOutputRodDriver.";
CM_ SG_ 300 iBooster_MstCylBrkPedlActTrvlSts "Actual travel status of master cylinder push rodQualifier for sOutputRodAct.";
CM_ SG_ 300 iBooster_DrvrBrkPedlTrvl "Driver target push rod stroke pedal travel of driver brake request.";
CM_ SG_ 300 iBooster_StopBackupState2Main "Brake backup mode to brake master control state";
CM_ SG_ 300 iBooster_TarStgyMod "Residual hydraulic control mode of wheel cylinderTarget strategy mode to activate residual pressure logic for ESPhev-X.Logic is triggered and coordinated by iBooster.";
CM_ SG_ 300 iBooster_SwCmpbltyIdx "ESP and ibooster software compatibility verification code index to ensure the compatibility between iB and ESP software.";
CM_ SG_ 300 iBooster_ReqFlg_HBC "HBC request flag bit, hydraulic assist request sent by iooster to ESPWith this signal iBooster requests the fail boost function of ESP.";
CM_ SG_ 300 iBooster_PdelFPotlPSts "IBooster Coordination Pressure Capacity Value Status BitQualifier for pForceBlendingPotential.";
CM_ SG_ 300 iBooster_PdelFPotlP "IBooster Coordination Pressure Capacity ValueRepresent the potential of iBooster pedal force compensation as pressure.Consider the DRR adjustment due to mechanical limitations and current pressure.";
CM_ SG_ 300 iBooster_MaxMstCylPSts "iBooster maximum boost pressure state bitQualifier for pRunout.";
CM_ SG_ 300 iBooster_MaxMstCylP "IBooster maximum boost pressureIn driver braking: maximum achievable master cylinder pressure with boost (runout.)With an active pressure increase: maximum achievable brake master cylinder pressure.";
CM_ SG_ 300 iBooster_DiagFlg "iooster Diagnostic flag positioniBooster must set this signal to TRUE, if the iBooster is in diagnosis mode.";
CM_ SG_ 300 ALIVE_iBooster_01 "Alive Counter";
CM_ SG_ 300 CRC_iBooster_01 "DataID=0x0037. Checksum calculation accordig CAN Specification. Cyclic Redundancy Check";
CM_ SG_ 448 SSecOC_MAC_FCM_04 "Short SecOC MAC signal byte 0 on CAN";
CM_ SG_ 448 SSecOC_Fresh_FCM_04 "Short SecOC Fresh signal byte 0 on CAN";
CM_ SG_ 448 FCM_LDW_SteerWheelVibrReq "LDW steering wheel vibration request flag";
CM_ SG_ 448 ADAS_FCM_ACC_PopUpMsg "PopUP Messaging for ACC function";
CM_ SG_ 448 FCM_ACC_StandstillReq "ACC standstill and drive off request";
CM_ SG_ 448 ALIVE_FCM_04 "Alive Counter";
CM_ SG_ 448 CRC_FCM_04 "DataID=0x0004. Checksum calculation accordig CAN Specification. Cyclic Redundancy Check";
CM_ SG_ 448 FCM_ADAS_LatCtrlSteerAnReq "Lateral control steering angle request value";
CM_ SG_ 448 FCM_ADAS_LatCtrlSts "Lateral control function status for ADAS steering functions";
CM_ SG_ 448 FCM_ADAS_LatCtrlStsVld "Lateral control function status validity for ADAS steering functions";
CM_ SG_ 448 FCM_ADAS_LatCtrlDrvrOvrd "Lateral control driver overide for ADAS steering functions";
CM_ SG_ 448 FCM_ADAS_LatCtrlDrvrOvrdVld "Lateral control driver overide validity for ADAS steering functions";
CM_ SG_ 448 FCM_ADAS_LatCtrlTyp "Lateral control type of request for ADAS steering functions";
CM_ SG_ 448 FCM_ADAS_LatCtrlReqVld "Lateral control request validity for ADAS steering functions";
CM_ SG_ 448 FCM_ADAS_LatCtrlReq "Lateral control command for activation of the request";
CM_ SG_ 448 FCM_ACC_AccelDecelFlg "one flag which indicates, if the acceleration OR deceleration request from ADAS system is valid";
CM_ SG_ 856 VCU_MaxChrgPower "maximum power the vehicle could charge at present state";
CM_ SG_ 856 VCU_MaxChrgCurrent "maximum current the vehicle could charge at present state";
CM_ SG_ 856 VCU_IntSocket230VButtonLEDSts "InteriorSocket 230V Button LED State (OHC)";
CM_ SG_ 856 SSecOC_MAC_VCU_06 "Short SecOC MAC signal byte 0 on CAN";
CM_ SG_ 856 SSecOC_Fresh_VCU_06 "Short SecOC Fresh signal byte 0 on CAN";
CM_ SG_ 856 VCU_LV_SoH "LV Battery SoH";
CM_ SG_ 856 VCU_LV_Batt_Temp "LV Battery Temperature";
CM_ SG_ 856 ALIVE_VCU_06 "Alive Counter";
CM_ SG_ 856 CRC_VCU_06 "DataID=0x0061. Checksum calculation accordig CAN Specification. Cyclic Redundancy Check";
CM_ SG_ 856 VCU_IMMO_Sts "Immobilizer Status";
CM_ SG_ 856 VCU_LV_Batt_SoC "LV Battery SoC";
CM_ SG_ 856 VCU_BattVolt "Battery voltage";
CM_ SG_ 1016 ALIVE_TBOX_06 "Alive Counter";
CM_ SG_ 1016 CRC_TBOX_06 "DataID=0x0054. Checksum calculation accordig CAN Specification. Cyclic Redundancy Check";
CM_ SG_ 1016 TBOX_OTA_ownCondchk "TBOX request ECUs to check own conditions for OTA";
CM_ SG_ 1016 TBOX_Flsflg "TBOX Flash flag";
CM_ SG_ 450 SSecOC_MAC_EPS_01 "Short SecOC MAC signal byte 0 on CAN";
CM_ SG_ 450 SSecOC_Fresh_EPS_01 "Short SecOC Fresh signal byte 0 on CAN";
CM_ SG_ 450 ALIVE_EPS_01 "Alive Counter";
CM_ SG_ 450 CRC_EPS_01 "DataID=0x0022. Checksum calculation accordig CAN Specification. Cyclic Redundancy Check";
CM_ SG_ 450 EPS_DrvrSteerTqDir "Driver steering torque direction (0 in counterclockwise and 1 in clockwise)";
CM_ SG_ 450 EPS_DrvrSteerTqVld "Effective Position of Driver Steering Torque";
CM_ SG_ 450 EPS_DrvrSteerTq "Driver steering torque";
CM_ SG_ 450 EPS_OTARdy_Fb "EPS OTA ready status feedback";
CM_ SG_ 450 EPS_DrvrIntvSteerWhlDetd "Detect driver intervention on steering wheel Driver Steering Interference Detected.";
CM_ SG_ 450 EPS_DrvrIntvSteerWhlVld "Effective position of driver intervention on steering wheel Driver Steering Interference Detected Validity.";
CM_ SG_ 450 EPS_PinionAg "Pinion rotation angle (positive counterclockwise, negative clockwise)";
CM_ SG_ 450 EPS_AbortFb "EPS control interruption reason";
CM_ SG_ 450 EPS_AdasLatCtrlSts "EPS system available state Electrical Power Steering Available Status.";
CM_ SG_ 450 EPS_AdasLatCtrlStsVld "EPS system available state Electrical Power Steering Available valid Status.";
CM_ SG_ 450 EPS_AsscMotCrtTq "Current torque of EPS booster motor";
CM_ SG_ 880 ALIVE_EPS_02 "Alive Counter";
CM_ SG_ 880 CRC_EPS_02 "DataID=0x0023. Checksum calculation accordig CAN Specification. Cyclic Redundancy Check";
CM_ SG_ 880 EPS_PwrSplyOverVoltFlt "High fault of EPS supply voltage_C20C917_Voltage High Error.";
CM_ SG_ 880 EPS_PwrSplyUnderVoltFlt "Low fault of EPS supply voltage_C20CA16_Voltage Low Error.";
CM_ SG_ 880 EPS_SnsrSplyVoltFlt "EPS sensor power supply voltage faulty_C20CB01_C20CC01_Sensor Supply Voltage Error.";
CM_ SG_ 880 EPS_MotShoOpenFlt "EPS motor short circuit or open fault_C20D196_C20D201_Motor Short or Open Error.";
CM_ SG_ 880 EPS_ThermProtnFlt "EPS thermal protection fail_C20D698_EPS Thermal Protection Error.";
CM_ SG_ 880 EPS_NVMFlt "EPS nonvolatile memory faulty_C20D804_NVM Error.";
CM_ SG_ 880 EPS_RunngRstFlt "EPS operation reset faila_C20D901_Running Reset Error.";
CM_ SG_ 880 EPS_ModSts "EPS mode status";
CM_ SG_ 880 EPS_IninSts "EPS initialization state EPS Initiaf States Options.";
CM_ SG_ 880 EPS_CrtSts "EPS current state EPS Current States.";
CM_ SG_ 880 EPS_SteerWhlBackStsFb "Return state feedback";
CM_ SG_ 880 EPS_AsscRate "EPS boost ratio";
CM_ SG_ 880 EPS_AsscMotCrtPwr "EPS power assisted motor current power";
CM_ SG_ 880 EPS_TqSnsrSigErr "EPS torque sensor main and auxiliary road signal calibration fault_C20CF02_Torque Sensor Signal Error.";
CM_ SG_ 880 EPS_TSnsrFlt "EPS temperature detection signal invalid fault_C20D704_Temperature Sensor Error.";
CM_ SG_ 880 EPS_ComLostFlt_ESP "EPS and ESP communication failure_U12FC87_Lost Communication with ESP Error.";
CM_ SG_ 880 EPS_SpdDataErr "EPS inspection ESP speed data error_U12FC86_Implausible Signal Received from ESP Error.";
CM_ SG_ 880 EPS_HwFlt "EPS controller malfunction_C20DB04_ECU Hardware Error.";
CM_ SG_ 880 EPS_RlyFlt "EPS relay fault_C20DA01_ECU Fail-Safe Relay Error.";
CM_ SG_ 880 EPS_MotPosnSnsrFlt "EPS motor rotor position signal fault_C20D001_Motor Position Sensor Error.";
CM_ SG_ 880 EPS_MotCrtFlt "EPS current abnormal fault_C20D528_C20D362_Motor Current Error.";
CM_ SG_ 880 EPS_AsscMotCrt "EPS booster motor current";
CM_ SG_ 1936 EPS1_Rx_CCP_TPCI "CCP signal";
CM_ SG_ 1936 EPS1_Rx_CCP_Byte2 "CCP signal";
CM_ SG_ 1936 EPS1_Rx_CCP_Byte3 "CCP signal";
CM_ SG_ 1936 EPS1_Rx_CCP_Byte4 "CCP signal";
CM_ SG_ 1936 EPS1_Rx_CCP_Byte5 "CCP signal";
CM_ SG_ 1936 EPS1_Rx_CCP_Byte6 "CCP signal";
CM_ SG_ 1936 EPS1_Rx_CCP_Byte7 "CCP signal";
CM_ SG_ 1936 EPS1_Rx_CCP_Byte8 "CCP signal";
CM_ SG_ 1983 EPS1_Tx_CCP_TPCI "CCP signal";
CM_ SG_ 1983 EPS1_Tx_CCP_Byte2 "CCP signal";
CM_ SG_ 1983 EPS1_Tx_CCP_Byte3 "CCP signal";
CM_ SG_ 1983 EPS1_Tx_CCP_Byte4 "CCP signal";
CM_ SG_ 1983 EPS1_Tx_CCP_Byte5 "CCP signal";
CM_ SG_ 1983 EPS1_Tx_CCP_Byte6 "CCP signal";
CM_ SG_ 1983 EPS1_Tx_CCP_Byte7 "CCP signal";
CM_ SG_ 1983 EPS1_Tx_CCP_Byte8 "CCP signal";
CM_ SG_ 895 ALIVE_EPS_03 "Alive Counter";
CM_ SG_ 895 CRC_EPS_03 "DataID=0x0024. Checksum calculation accordig CAN Specification. Cyclic Redundancy Check";
CM_ SG_ 895 EPS_SwVersS "Second two digits of EPS software version number";
CM_ SG_ 895 EPS_PartVers "EPS part number";
CM_ SG_ 895 EPS_HwVers "Second two digits of EPS hardware version number";
CM_ SG_ 895 EPS_SwVersM "Second two digits of EPS main software version number";
CM_ SG_ 2564485392 Diag_Resp_EPS1 "Diagnostic physical response data from EPS";
CM_ SG_ 2564485391 Diag_Resp_ESC "Diagnostic physical response data from ESC";
CM_ SG_ 2564485390 Diag_Resp_IM "Diagnostic physical response data from DMS";
CM_ SG_ 2564428017 Diag_PhyReq_EPS1 "Diagnostic physical request data to EPS";
CM_ SG_ 2564427761 Diag_PhyReq_ESC "Diagnostic physical request data to ESC";
CM_ SG_ 2564427505 Diag_PhyReq_IM "Diagnostic physical request data to DMS";
CM_ SG_ 2564485381 Diag_Resp_FCM "Diagnostic physical response data from FCM";
CM_ SG_ 2564425201 Diag_PhyReq_FCM "Diagnostic physical request data to FCM";
BA_DEF_ SG_  "GenSigSendType" ENUM  "Cyclic","OnWrite","OnWriteWithRepetition","OnChange","OnChangeWithRepetition","NotUsed","NotUsed","NoSigSendType";
BA_DEF_ SG_  "GenSigInactiveValue" INT 0 65535;
BA_DEF_ SG_  "GenSigStartValue" HEX 0 65535;
BA_DEF_ BO_  "GenMsgTimeoutTime" INT 0 65535;
BA_DEF_ BO_  "E2EDataId" INT 0 65535;
BA_DEF_ BO_  "SCP_FreshnessValueTxLength" INT 0 512;
BA_DEF_ BO_  "SCP_FreshnessValueLength" INT 0 512;
BA_DEF_ BO_  "SCP_AuthInfoTxLength" INT 0 512;
BA_DEF_ BO_  "GenMsgSendType" ENUM  "Cyclic","NotUsed","NotUsed","NotUsed","NotUsed","NotUsed","NotUsed","IfActive","NoMsgSendType";
BA_DEF_ BO_  "NmAsrMessage" ENUM  "No","Yes";
BA_DEF_ BO_  "Transmitter" STRING ;
BA_DEF_ BO_  "Gateway" STRING ;
BA_DEF_ BO_  "VFrameFormat" ENUM  "CAN Standard","CAN Extended","reserved","reserved","reserved","reserved","reserved","reserved","reserved","reserved","reserved","reserved","reserved","reserved","CAN FD Standard","CAN FD Extended";
BA_DEF_ BO_  "DiagRequest" ENUM  "No","Yes";
BA_DEF_ BO_  "DiagResponse" ENUM  "No","Yes";
BA_DEF_ BO_  "DiagState" ENUM  "No","Yes";
BA_DEF_ BO_  "GenMsgCycleTime" INT 0 65535;
BA_DEF_ BO_  "GenMsgCycleTimeFast" INT 0 65535;
BA_DEF_ BO_  "GenMsgDelayTime" INT 0 65535;
BA_DEF_ BO_  "GenMsgILSupport" ENUM  "No","Yes";
BA_DEF_ BO_  "GenMsgNrOfRepetition" INT 0 255;
BA_DEF_ BO_  "GenMsgStartDelayTime" INT 0 65535;
BA_DEF_DEF_  "GenSigSendType" "Cyclic";
BA_DEF_DEF_  "GenSigInactiveValue" 0;
BA_DEF_DEF_  "GenSigStartValue" 0;
BA_DEF_DEF_  "GenMsgTimeoutTime" 0;
BA_DEF_DEF_  "E2EDataId" 0;
BA_DEF_DEF_  "SCP_FreshnessValueTxLength" 4;
BA_DEF_DEF_  "SCP_FreshnessValueLength" 48;
BA_DEF_DEF_  "SCP_AuthInfoTxLength" 64;
BA_DEF_DEF_  "GenMsgSendType" "NoMsgSendType";
BA_DEF_DEF_  "NmAsrMessage" "No";
BA_DEF_DEF_  "Transmitter" "Default";
BA_DEF_DEF_  "Gateway" "Default";
BA_DEF_DEF_  "VFrameFormat" "CAN FD Standard";
BA_DEF_DEF_  "DiagRequest" "No";
BA_DEF_DEF_  "DiagResponse" "No";
BA_DEF_DEF_  "DiagState" "No";
BA_DEF_DEF_  "GenMsgCycleTime" 0;
BA_DEF_DEF_  "GenMsgCycleTimeFast" 0;
BA_DEF_DEF_  "GenMsgDelayTime" 0;
BA_DEF_DEF_  "GenMsgILSupport" "Yes";
BA_DEF_DEF_  "GenMsgNrOfRepetition" 0;
BA_DEF_DEF_  "GenMsgStartDelayTime" 0;
BA_ "GenMsgTimeoutTime" BO_ 896 3000;
BA_ "GenMsgSendType" BO_ 896 0;
BA_ "Transmitter" BO_ 896 "BCM";
BA_ "Gateway" BO_ 896 "CGW, VCU";
BA_ "GenMsgCycleTime" BO_ 896 1000;
BA_ "GenMsgTimeoutTime" BO_ 264 300;
BA_ "E2EDataId" BO_ 264 8;
BA_ "GenMsgSendType" BO_ 264 0;
BA_ "Transmitter" BO_ 264 "BCM";
BA_ "Gateway" BO_ 264 "CGW, HU";
BA_ "GenMsgCycleTime" BO_ 264 100;
BA_ "GenMsgCycleTimeFast" BO_ 264 10;
BA_ "GenMsgNrOfRepetition" BO_ 264 3;
BA_ "GenMsgTimeoutTime" BO_ 433 300;
BA_ "E2EDataId" BO_ 433 24;
BA_ "GenMsgSendType" BO_ 433 0;
BA_ "Transmitter" BO_ 433 "CGW";
BA_ "Gateway" BO_ 433 "VCU, HU";
BA_ "GenMsgCycleTime" BO_ 433 100;
BA_ "GenMsgTimeoutTime" BO_ 1040 300;
BA_ "E2EDataId" BO_ 1040 123;
BA_ "GenMsgSendType" BO_ 1040 0;
BA_ "Transmitter" BO_ 1040 "EPS1";
BA_ "Gateway" BO_ 1040 "CGW";
BA_ "GenMsgCycleTime" BO_ 1040 100;
BA_ "GenMsgCycleTimeFast" BO_ 1040 25;
BA_ "GenMsgDelayTime" BO_ 1040 25;
BA_ "GenMsgNrOfRepetition" BO_ 1040 3;
BA_ "GenMsgTimeoutTime" BO_ 1039 900;
BA_ "E2EDataId" BO_ 1039 124;
BA_ "GenMsgSendType" BO_ 1039 0;
BA_ "Transmitter" BO_ 1039 "ESC";
BA_ "Gateway" BO_ 1039 "CGW";
BA_ "GenMsgCycleTime" BO_ 1039 300;
BA_ "GenMsgCycleTimeFast" BO_ 1039 25;
BA_ "GenMsgDelayTime" BO_ 1039 25;
BA_ "GenMsgNrOfRepetition" BO_ 1039 3;
BA_ "GenMsgTimeoutTime" BO_ 1038 3000;
BA_ "E2EDataId" BO_ 1038 128;
BA_ "GenMsgSendType" BO_ 1038 0;
BA_ "Transmitter" BO_ 1038 "IM";
BA_ "Gateway" BO_ 1038 "CGW";
BA_ "GenMsgCycleTime" BO_ 1038 1000;
BA_ "GenMsgCycleTimeFast" BO_ 1038 25;
BA_ "GenMsgDelayTime" BO_ 1038 25;
BA_ "GenMsgNrOfRepetition" BO_ 1038 3;
BA_ "GenMsgTimeoutTime" BO_ 247 60;
BA_ "E2EDataId" BO_ 247 19;
BA_ "GenMsgSendType" BO_ 247 0;
BA_ "Transmitter" BO_ 247 "BMS";
BA_ "Gateway" BO_ 247 "CGW, VCU, HU";
BA_ "GenMsgCycleTime" BO_ 247 20;
BA_ "GenMsgTimeoutTime" BO_ 1029 3000;
BA_ "E2EDataId" BO_ 1029 125;
BA_ "GenMsgSendType" BO_ 1029 0;
BA_ "Transmitter" BO_ 1029 "FCM";
BA_ "Gateway" BO_ 1029 "CGW";
BA_ "GenMsgCycleTime" BO_ 1029 1000;
BA_ "GenMsgCycleTimeFast" BO_ 1029 25;
BA_ "GenMsgDelayTime" BO_ 1029 25;
BA_ "GenMsgNrOfRepetition" BO_ 1029 3;
BA_ "GenMsgTimeoutTime" BO_ 258 300;
BA_ "E2EDataId" BO_ 258 7;
BA_ "GenMsgSendType" BO_ 258 0;
BA_ "Transmitter" BO_ 258 "BCM";
BA_ "Gateway" BO_ 258 "CGW, VCU, HU";
BA_ "GenMsgCycleTime" BO_ 258 100;
BA_ "Transmitter" BO_ 2564502513 "Tester";
BA_ "Gateway" BO_ 2564502513 "CGW, VCU, HU";
BA_ "DiagState" BO_ 2564502513 1;
BA_ "VFrameFormat" BO_ 2564502513 15;
BA_ "GenMsgTimeoutTime" BO_ 752 3000;
BA_ "E2EDataId" BO_ 752 54;
BA_ "GenMsgSendType" BO_ 752 0;
BA_ "Transmitter" BO_ 752 "HU";
BA_ "Gateway" BO_ 752 "CGW, VCU";
BA_ "GenMsgCycleTime" BO_ 752 1000;
BA_ "GenMsgTimeoutTime" BO_ 513 300;
BA_ "E2EDataId" BO_ 513 2;
BA_ "GenMsgSendType" BO_ 513 0;
BA_ "Transmitter" BO_ 513 "ACM";
BA_ "Gateway" BO_ 513 "CGW";
BA_ "GenMsgCycleTime" BO_ 513 100;
BA_ "GenMsgCycleTimeFast" BO_ 513 10;
BA_ "GenMsgNrOfRepetition" BO_ 513 2;
BA_ "Transmitter" BO_ 2564485412 "FCM";
BA_ "Gateway" BO_ 2564485412 "CGW";
BA_ "DiagResponse" BO_ 2564485412 1;
BA_ "VFrameFormat" BO_ 2564485412 15;
BA_ "Transmitter" BO_ 2564485411 "FCM";
BA_ "Gateway" BO_ 2564485411 "CGW";
BA_ "DiagResponse" BO_ 2564485411 1;
BA_ "VFrameFormat" BO_ 2564485411 15;
BA_ "Transmitter" BO_ 2564485404 "FCM";
BA_ "Gateway" BO_ 2564485404 "CGW";
BA_ "DiagResponse" BO_ 2564485404 1;
BA_ "VFrameFormat" BO_ 2564485404 15;
BA_ "Transmitter" BO_ 2564433137 "Tester";
BA_ "Gateway" BO_ 2564433137 "CGW";
BA_ "DiagRequest" BO_ 2564433137 1;
BA_ "VFrameFormat" BO_ 2564433137 15;
BA_ "Transmitter" BO_ 2564432881 "Tester";
BA_ "Gateway" BO_ 2564432881 "CGW";
BA_ "DiagRequest" BO_ 2564432881 1;
BA_ "VFrameFormat" BO_ 2564432881 15;
BA_ "Transmitter" BO_ 2564431089 "Tester";
BA_ "Gateway" BO_ 2564431089 "CGW";
BA_ "DiagRequest" BO_ 2564431089 1;
BA_ "VFrameFormat" BO_ 2564431089 15;
BA_ "NmAsrMessage" BO_ 1305 1;
BA_ "Transmitter" BO_ 1305 "TPMS";
BA_ "Gateway" BO_ 1305 "-";
BA_ "GenMsgILSupport" BO_ 1305 0;
BA_ "Transmitter" BO_ 1913 "TPMS";
BA_ "Gateway" BO_ 1913 "CGW";
BA_ "GenMsgILSupport" BO_ 1913 0;
BA_ "NmAsrMessage" BO_ 1284 1;
BA_ "Transmitter" BO_ 1284 "VCU";
BA_ "Gateway" BO_ 1284 "-";
BA_ "GenMsgILSupport" BO_ 1284 0;
BA_ "GenMsgTimeoutTime" BO_ 594 300;
BA_ "E2EDataId" BO_ 594 73;
BA_ "GenMsgSendType" BO_ 594 0;
BA_ "Transmitter" BO_ 594 "SCM";
BA_ "Gateway" BO_ 594 "CGW, VCU";
BA_ "GenMsgCycleTime" BO_ 594 10;
BA_ "GenMsgTimeoutTime" BO_ 592 300;
BA_ "E2EDataId" BO_ 592 72;
BA_ "GenMsgSendType" BO_ 592 0;
BA_ "Transmitter" BO_ 592 "SCM";
BA_ "Gateway" BO_ 592 "CGW";
BA_ "GenMsgCycleTime" BO_ 592 100;
BA_ "GenMsgTimeoutTime" BO_ 389 3000;
BA_ "E2EDataId" BO_ 389 68;
BA_ "GenMsgSendType" BO_ 389 0;
BA_ "Transmitter" BO_ 389 "FCM";
BA_ "Gateway" BO_ 389 "CGW";
BA_ "GenMsgCycleTime" BO_ 389 100;
BA_ "GenMsgTimeoutTime" BO_ 272 30;
BA_ "E2EDataId" BO_ 272 96;
BA_ "GenMsgSendType" BO_ 272 0;
BA_ "Transmitter" BO_ 272 "VCU";
BA_ "Gateway" BO_ 272 "CGW, HU";
BA_ "GenMsgCycleTime" BO_ 272 10;
BA_ "GenMsgTimeoutTime" BO_ 327 30;
BA_ "E2EDataId" BO_ 327 28;
BA_ "GenMsgSendType" BO_ 327 0;
BA_ "Transmitter" BO_ 327 "EDU_F";
BA_ "Gateway" BO_ 327 "CGW, VCU, HU";
BA_ "GenMsgCycleTime" BO_ 327 10;
BA_ "GenMsgTimeoutTime" BO_ 328 30;
BA_ "E2EDataId" BO_ 328 32;
BA_ "GenMsgSendType" BO_ 328 0;
BA_ "Transmitter" BO_ 328 "EDU_R";
BA_ "Gateway" BO_ 328 "CGW, VCU, HU";
BA_ "GenMsgCycleTime" BO_ 328 10;
BA_ "E2EDataId" BO_ 589 157;
BA_ "GenMsgSendType" BO_ 589 0;
BA_ "Transmitter" BO_ 589 "CGW";
BA_ "GenMsgCycleTime" BO_ 589 3000;
BA_ "NmAsrMessage" BO_ 1285 1;
BA_ "Transmitter" BO_ 1285 "FCM";
BA_ "Gateway" BO_ 1285 "-";
BA_ "GenMsgILSupport" BO_ 1285 0;
BA_ "GenMsgTimeoutTime" BO_ 384 30;
BA_ "E2EDataId" BO_ 384 42;
BA_ "GenMsgSendType" BO_ 384 0;
BA_ "Transmitter" BO_ 384 "FCM";
BA_ "Gateway" BO_ 384 "CGW, VCU";
BA_ "GenMsgCycleTime" BO_ 384 10;
BA_ "GenMsgTimeoutTime" BO_ 416 30;
BA_ "E2EDataId" BO_ 416 26;
BA_ "GenMsgSendType" BO_ 416 0;
BA_ "Transmitter" BO_ 416 "EDU_F";
BA_ "Gateway" BO_ 416 "VCU";
BA_ "GenMsgCycleTime" BO_ 416 10;
BA_ "GenMsgTimeoutTime" BO_ 419 30;
BA_ "E2EDataId" BO_ 419 30;
BA_ "GenMsgSendType" BO_ 419 0;
BA_ "Transmitter" BO_ 419 "EDU_R";
BA_ "Gateway" BO_ 419 "VCU";
BA_ "GenMsgCycleTime" BO_ 419 10;
BA_ "GenMsgTimeoutTime" BO_ 422 30;
BA_ "E2EDataId" BO_ 422 113;
BA_ "GenMsgSendType" BO_ 422 0;
BA_ "Transmitter" BO_ 422 "VCU";
BA_ "Gateway" BO_ 422 "CGW";
BA_ "GenMsgCycleTime" BO_ 422 10;
BA_ "Transmitter" BO_ 145 "CGW";
BA_ "Gateway" BO_ 145 "VCU";
BA_ "GenMsgCycleTimeFast" BO_ 145 50;
BA_ "GenMsgDelayTime" BO_ 145 50;
BA_ "GenMsgNrOfRepetition" BO_ 145 3;
BA_ "GenMsgTimeoutTime" BO_ 300 30;
BA_ "E2EDataId" BO_ 300 55;
BA_ "GenMsgSendType" BO_ 300 0;
BA_ "Transmitter" BO_ 300 "iBooster";
BA_ "Gateway" BO_ 300 "CGW";
BA_ "GenMsgCycleTime" BO_ 300 10;
BA_ "GenMsgTimeoutTime" BO_ 448 30;
BA_ "E2EDataId" BO_ 448 4;
BA_ "GenMsgSendType" BO_ 448 0;
BA_ "Transmitter" BO_ 448 "FCM";
BA_ "Gateway" BO_ 448 "VCU";
BA_ "GenMsgCycleTime" BO_ 448 10;
BA_ "GenMsgTimeoutTime" BO_ 856 150;
BA_ "E2EDataId" BO_ 856 97;
BA_ "GenMsgSendType" BO_ 856 0;
BA_ "Transmitter" BO_ 856 "VCU";
BA_ "Gateway" BO_ 856 "CGW, HU";
BA_ "GenMsgCycleTime" BO_ 856 50;
BA_ "GenMsgTimeoutTime" BO_ 1016 300;
BA_ "E2EDataId" BO_ 1016 84;
BA_ "GenMsgSendType" BO_ 1016 0;
BA_ "Transmitter" BO_ 1016 "TBOX";
BA_ "Gateway" BO_ 1016 "CGW, VCU";
BA_ "GenMsgCycleTime" BO_ 1016 100;
BA_ "GenMsgTimeoutTime" BO_ 450 30;
BA_ "E2EDataId" BO_ 450 34;
BA_ "GenMsgSendType" BO_ 450 0;
BA_ "Transmitter" BO_ 450 "EPS1";
BA_ "Gateway" BO_ 450 "CGW";
BA_ "GenMsgCycleTime" BO_ 450 10;
BA_ "GenMsgTimeoutTime" BO_ 880 300;
BA_ "E2EDataId" BO_ 880 35;
BA_ "GenMsgSendType" BO_ 880 0;
BA_ "Transmitter" BO_ 880 "EPS1";
BA_ "Gateway" BO_ 880 "CGW";
BA_ "GenMsgCycleTime" BO_ 880 100;
BA_ "Transmitter" BO_ 1936 "CGW";
BA_ "Gateway" BO_ 1936 "-";
BA_ "GenMsgILSupport" BO_ 1936 0;
BA_ "Transmitter" BO_ 1983 "EPS1";
BA_ "Gateway" BO_ 1983 "-";
BA_ "GenMsgILSupport" BO_ 1983 0;
BA_ "GenMsgTimeoutTime" BO_ 895 3000;
BA_ "E2EDataId" BO_ 895 36;
BA_ "GenMsgSendType" BO_ 895 0;
BA_ "Transmitter" BO_ 895 "EPS1";
BA_ "Gateway" BO_ 895 "CGW";
BA_ "GenMsgCycleTime" BO_ 895 1000;
BA_ "Transmitter" BO_ 2564485392 "EPS1";
BA_ "Gateway" BO_ 2564485392 "CGW";
BA_ "DiagResponse" BO_ 2564485392 1;
BA_ "VFrameFormat" BO_ 2564485392 15;
BA_ "Transmitter" BO_ 2564485391 "ESC";
BA_ "Gateway" BO_ 2564485391 "CGW";
BA_ "DiagResponse" BO_ 2564485391 1;
BA_ "VFrameFormat" BO_ 2564485391 15;
BA_ "Transmitter" BO_ 2564485390 "IM";
BA_ "Gateway" BO_ 2564485390 "CGW";
BA_ "DiagResponse" BO_ 2564485390 1;
BA_ "VFrameFormat" BO_ 2564485390 15;
BA_ "Transmitter" BO_ 2564428017 "Tester";
BA_ "Gateway" BO_ 2564428017 "CGW";
BA_ "DiagRequest" BO_ 2564428017 1;
BA_ "VFrameFormat" BO_ 2564428017 15;
BA_ "Transmitter" BO_ 2564427761 "Tester";
BA_ "Gateway" BO_ 2564427761 "CGW";
BA_ "DiagRequest" BO_ 2564427761 1;
BA_ "VFrameFormat" BO_ 2564427761 15;
BA_ "Transmitter" BO_ 2564427505 "Tester";
BA_ "Gateway" BO_ 2564427505 "CGW";
BA_ "DiagRequest" BO_ 2564427505 1;
BA_ "VFrameFormat" BO_ 2564427505 15;
BA_ "Transmitter" BO_ 2564485381 "FCM";
BA_ "Gateway" BO_ 2564485381 "CGW";
BA_ "DiagResponse" BO_ 2564485381 1;
BA_ "VFrameFormat" BO_ 2564485381 15;
BA_ "Transmitter" BO_ 2564425201 "Tester";
BA_ "Gateway" BO_ 2564425201 "CGW";
BA_ "DiagRequest" BO_ 2564425201 1;
BA_ "VFrameFormat" BO_ 2564425201 15;
BA_ "GenSigSendType" SG_ 264 STAT_BonnetAjar 4;
BA_ "GenSigSendType" SG_ 264 STAT_TrunkAjar 4;
BA_ "GenSigSendType" SG_ 264 STAT_DoorAjarRR 4;
BA_ "GenSigSendType" SG_ 264 STAT_DoorAjarPass 4;
BA_ "GenSigSendType" SG_ 264 STAT_DoorAjarRL 4;
BA_ "GenSigSendType" SG_ 264 STAT_DoorAjarDriver 4;
BA_ "GenSigStartValue" SG_ 1040 BitStatus_EPS1 1;
BA_ "GenSigStartValue" SG_ 1039 BitStatus_ESC 1;
BA_ "GenSigStartValue" SG_ 1038 BitStatus_IM 1;
BA_ "GenSigStartValue" SG_ 247 BMS_actPower 600;
BA_ "GenSigStartValue" SG_ 247 BMS_addedEnergyCharging 250;
BA_ "GenSigStartValue" SG_ 247 BMS_BattCellstartframeNum 65535;
BA_ "GenSigStartValue" SG_ 247 BMS_HvBattI 65535;
BA_ "GenSigStartValue" SG_ 247 BMS_HvBattSoh 127;
BA_ "GenSigStartValue" SG_ 1029 BitStatus_FCM 1;
BA_ "GenSigStartValue" SG_ 258 BCM_STAT_CL30R_L 3;
BA_ "GenSigStartValue" SG_ 258 BCM_STAT_CL30s_L 3;
BA_ "GenSigStartValue" SG_ 258 BCM_STAT_CL15_L 3;
BA_ "GenSigSendType" SG_ 2564502513 Diag_FuncReq_Data 1;
BA_ "GenSigSendType" SG_ 513 ST_PAB_SW 3;
BA_ "GenSigStartValue" SG_ 513 ST_PAB_SW 2;
BA_ "GenSigSendType" SG_ 513 ST_BELT_BUCK_RM 3;
BA_ "GenSigStartValue" SG_ 513 ST_BELT_BUCK_RM 2;
BA_ "GenSigStartValue" SG_ 513 ST_COD 4;
BA_ "GenSigSendType" SG_ 513 ST_BELT_BUCK_RR 3;
BA_ "GenSigStartValue" SG_ 513 ST_BELT_BUCK_RR 2;
BA_ "GenSigSendType" SG_ 513 ST_BELT_BUCK_RL 3;
BA_ "GenSigStartValue" SG_ 513 ST_BELT_BUCK_RL 2;
BA_ "GenSigSendType" SG_ 513 ST_BELT_BUCK_PS 3;
BA_ "GenSigStartValue" SG_ 513 ST_BELT_BUCK_PS 2;
BA_ "GenSigStartValue" SG_ 513 ST_SEAT_OCCU_PS 2;
BA_ "GenSigSendType" SG_ 513 ST_BELT_BUCK_DR 3;
BA_ "GenSigStartValue" SG_ 513 ST_BELT_BUCK_DR 2;
BA_ "GenSigSendType" SG_ 2564485412 Diag_Resp_RadarRR 1;
BA_ "GenSigSendType" SG_ 2564485411 Diag_Resp_RadarRL 1;
BA_ "GenSigSendType" SG_ 2564485404 Diag_Resp_RF 1;
BA_ "GenSigSendType" SG_ 2564433137 Diag_PhyReq_RadarRR 1;
BA_ "GenSigSendType" SG_ 2564432881 Diag_PhyReq_RadarRL 1;
BA_ "GenSigSendType" SG_ 2564431089 Diag_PhyReq_RF 1;
BA_ "GenSigSendType" SG_ 1305 usrData1_TPM_Bit7_ECUSPEC_AWAKE 7;
BA_ "GenSigSendType" SG_ 1305 usrData1_TPM_Bit6_DIAGN_AWAKE 7;
BA_ "GenSigSendType" SG_ 1305 usrData1_TPM_Bit5_IGNITION_AWAKE 7;
BA_ "GenSigSendType" SG_ 1305 usrData1_TPM_Bit4_NETWORK_AWAKE 7;
BA_ "GenSigSendType" SG_ 1305 usrData1_TPM_Bit3_ECUSPEC_WAKEUP 7;
BA_ "GenSigSendType" SG_ 1305 usrData1_TPM_Bit2_NETWORK_WAKEUP 7;
BA_ "GenSigSendType" SG_ 1305 usrData1_TPM_Bit1_RESET_WAKEUP 7;
BA_ "GenSigSendType" SG_ 1305 CtrlBitVector_TPM_Bit7_Res 7;
BA_ "GenSigSendType" SG_ 1305 CtrlBitVector_TPM_Bit6_PNI 7;
BA_ "GenSigSendType" SG_ 1305 CtrlBitVector_TPM_Bit5_Res 7;
BA_ "GenSigSendType" SG_ 1305 CtrlBitVector_TPM_Bit4_ActWake 7;
BA_ "GenSigSendType" SG_ 1305 CtrlBitVector_TPM_Bit3_NMCoord 7;
BA_ "GenSigSendType" SG_ 1305 CtrlBitVector_TPM_Bit2_Res 7;
BA_ "GenSigSendType" SG_ 1305 CtrlBitVector_TPM_Bit1_Res 7;
BA_ "GenSigSendType" SG_ 1305 usrData1_TPM_Bit0_IGN_WAKEUP 7;
BA_ "GenSigSendType" SG_ 1305 usrData0_TPM 7;
BA_ "GenSigSendType" SG_ 1305 srcNodeID_TPM 7;
BA_ "GenSigSendType" SG_ 1305 CtrlBitVector_TPM_Bit0_RMR 7;
BA_ "GenSigSendType" SG_ 1305 usrData2_TPM 7;
BA_ "GenSigSendType" SG_ 1305 usrData4_TPM_PN_Info1 7;
BA_ "GenSigSendType" SG_ 1305 usrData5_TPM_PN_Info2 7;
BA_ "GenSigSendType" SG_ 1305 usrData3_TPM 7;
BA_ "GenSigSendType" SG_ 1913 TPMS_MEAS_ID 7;
BA_ "GenSigSendType" SG_ 1913 Meas_TPM_1H 7;
BA_ "GenSigSendType" SG_ 1913 Meas_TPM_1G 7;
BA_ "GenSigSendType" SG_ 1913 Meas_TPM_1F 7;
BA_ "GenSigSendType" SG_ 1913 Meas_TPM_1E 7;
BA_ "GenSigSendType" SG_ 1913 Meas_TPM_1D 7;
BA_ "GenSigSendType" SG_ 1913 Meas_TPM_1C 7;
BA_ "GenSigSendType" SG_ 1913 Meas_TPM_1B 7;
BA_ "GenSigSendType" SG_ 1913 Meas_TPM_1A 7;
BA_ "GenSigSendType" SG_ 1284 usrData1_VCU_Bit7_ECUSPEC_AWAKE 7;
BA_ "GenSigSendType" SG_ 1284 usrData1_VCU_Bit6_DIAGN_AWAKE 7;
BA_ "GenSigSendType" SG_ 1284 usrData1_VCU_Bit5_IGNITION_AWAKE 7;
BA_ "GenSigSendType" SG_ 1284 usrData1_VCU_Bit4_NETWORK_AWAKE 7;
BA_ "GenSigSendType" SG_ 1284 usrData1_VCU_Bit3_ECUSPEC_WAKEUP 7;
BA_ "GenSigSendType" SG_ 1284 usrData1_VCU_Bit2_NETWORK_WAKEUP 7;
BA_ "GenSigSendType" SG_ 1284 usrData1_VCU_Bit1_RESET_WAKEUP 7;
BA_ "GenSigSendType" SG_ 1284 CtrlBitVector_VCU_Bit7_Res 7;
BA_ "GenSigSendType" SG_ 1284 CtrlBitVector_VCU_Bit6_PNI 7;
BA_ "GenSigSendType" SG_ 1284 CtrlBitVector_VCU_Bit5_Res 7;
BA_ "GenSigSendType" SG_ 1284 CtrlBitVector_VCU_Bit4_ActWake 7;
BA_ "GenSigSendType" SG_ 1284 CtrlBitVector_VCU_Bit3_NMCoord 7;
BA_ "GenSigSendType" SG_ 1284 CtrlBitVector_VCU_Bit2_Res 7;
BA_ "GenSigSendType" SG_ 1284 CtrlBitVector_VCU_Bit1_Res 7;
BA_ "GenSigSendType" SG_ 1284 usrData1_VCU_Bit0_IGN_WAKEUP 7;
BA_ "GenSigSendType" SG_ 1284 usrData0_VCU 7;
BA_ "GenSigSendType" SG_ 1284 srcNodeID_VCU 7;
BA_ "GenSigSendType" SG_ 1284 CtrlBitVector_VCU_Bit0_RMR 7;
BA_ "GenSigSendType" SG_ 1284 usrData2_VCU 7;
BA_ "GenSigSendType" SG_ 1284 usrData4_VCU_PN_Info1 7;
BA_ "GenSigSendType" SG_ 1284 usrData5_VCU_PN_Info2 7;
BA_ "GenSigSendType" SG_ 1284 usrData3_VCU 7;
BA_ "GenSigStartValue" SG_ 594 SAS_SteerWheelAngle 9600;
BA_ "GenSigStartValue" SG_ 327 EDU_F_HVActvDcha_Sts 6;
BA_ "GenSigStartValue" SG_ 328 EDU_R_HVActvDcha_Sts 6;
BA_ "GenSigSendType" SG_ 589 Syn_RstCtrlVal 2;
BA_ "GenSigSendType" SG_ 589 Syn_TripCtrlVal 2;
BA_ "GenSigSendType" SG_ 1285 usrData1_FCM_Bit7_ECUSPEC_AWAKE 7;
BA_ "GenSigSendType" SG_ 1285 usrData1_FCM_Bit6_DIAGN_AWAKE 7;
BA_ "GenSigSendType" SG_ 1285 usrData1_FCM_Bit5_IGNITION_AWAKE 7;
BA_ "GenSigSendType" SG_ 1285 usrData1_FCM_Bit4_NETWORK_AWAKE 7;
BA_ "GenSigSendType" SG_ 1285 usrData1_FCM_Bit3_ECUSPEC_WAKEUP 7;
BA_ "GenSigSendType" SG_ 1285 usrData1_FCM_Bit2_NETWORK_WAKEUP 7;
BA_ "GenSigSendType" SG_ 1285 usrData1_FCM_Bit1_RESET_WAKEUP 7;
BA_ "GenSigSendType" SG_ 1285 CtrlBitVector_FCM_Bit7_Res 7;
BA_ "GenSigSendType" SG_ 1285 CtrlBitVector_FCM_Bit6_PNI 7;
BA_ "GenSigSendType" SG_ 1285 CtrlBitVector_FCM_Bit5_Res 7;
BA_ "GenSigSendType" SG_ 1285 CtrlBitVector_FCM_Bit4_ActWake 7;
BA_ "GenSigSendType" SG_ 1285 CtrlBitVector_FCM_Bit3_NMCoord 7;
BA_ "GenSigSendType" SG_ 1285 CtrlBitVector_FCM_Bit2_Res 7;
BA_ "GenSigSendType" SG_ 1285 CtrlBitVector_FCM_Bit1_Res 7;
BA_ "GenSigSendType" SG_ 1285 usrData1_FCM_Bit0_IGN_WAKEUP 7;
BA_ "GenSigSendType" SG_ 1285 usrData0_FCM 7;
BA_ "GenSigSendType" SG_ 1285 srcNodeID_FCM 7;
BA_ "GenSigSendType" SG_ 1285 CtrlBitVector_FCM_Bit0_RMR 7;
BA_ "GenSigSendType" SG_ 1285 usrData2_FCM 7;
BA_ "GenSigSendType" SG_ 1285 usrData4_FCM_PN_Info1 7;
BA_ "GenSigSendType" SG_ 1285 usrData5_FCM_PN_Info2 7;
BA_ "GenSigSendType" SG_ 1285 usrData3_FCM 7;
BA_ "GenSigSendType" SG_ 384 FCM_AEB_BrkDecelVal 1;
BA_ "GenSigStartValue" SG_ 384 FCM_AEB_BrkDecelVal 1000;
BA_ "GenSigSendType" SG_ 384 FCM_AEB_PrefillReq 1;
BA_ "GenSigSendType" SG_ 384 FCM_DBS_Req 1;
BA_ "GenSigSendType" SG_ 384 FCM_AEB_FCWAlertReq 1;
BA_ "GenSigSendType" SG_ 384 FCM_ASA_Fuli_MainSignSL 1;
BA_ "GenSigSendType" SG_ 384 FCM_ASA_TFMapExpired 1;
BA_ "GenSigSendType" SG_ 384 FCM_ASA_TFDrivgSide 1;
BA_ "GenSigSendType" SG_ 384 FCM_ASA_ReconstructorSts 1;
BA_ "GenSigSendType" SG_ 384 FCM_ASA_CondlInfoMapSL 1;
BA_ "GenSigSendType" SG_ 384 FCM_ASA_SpdLimMai 1;
BA_ "GenSigStartValue" SG_ 384 FCM_ADAS_LatTqReq 32768;
BA_ "GenSigStartValue" SG_ 384 FCM_ADAS_SteerAgReq 32768;
BA_ "GenSigStartValue" SG_ 384 FCM_ACC_AReq 2048;
BA_ "GenSigSendType" SG_ 384 FCM_ASA_DrvgContext 1;
BA_ "GenSigSendType" SG_ 384 FCM_ASA_SpdLimMap 1;
BA_ "GenSigSendType" SG_ 384 FCM_ASA_SpdUnit 1;
BA_ "GenSigSendType" SG_ 384 FCM_ASA_OperCtry 1;
BA_ "GenSigSendType" SG_ 384 FCM_ASA_FailrReasn 1;
BA_ "GenSigSendType" SG_ 384 FCM_ASA_ConditionalInfo 1;
BA_ "GenSigSendType" SG_ 384 FCM_ASA_Mod 1;
BA_ "GenSigSendType" SG_ 384 FCM_ASA_SpdLimConfd 1;
BA_ "GenSigStartValue" SG_ 422 VCU_HVActvDchaReq_EDU_R 2;
BA_ "GenSigStartValue" SG_ 422 VCU_HVActvDchaReq_EDU_F 2;
BA_ "GenSigSendType" SG_ 145 Syn_TripCntrVal_Byte0_All 2;
BA_ "GenSigSendType" SG_ 145 Syn_TripCntrVal_Byte1_All 2;
BA_ "GenSigSendType" SG_ 145 Syn_RstCntrVal_Byte0_All 2;
BA_ "GenSigSendType" SG_ 145 Syn_RstCntrVal_Byte1_All 2;
BA_ "GenSigSendType" SG_ 145 Syn_RstCntrVal_Byte2_All 2;
BA_ "GenSigSendType" SG_ 145 Syn_MACInfo_Byte0_All 2;
BA_ "GenSigSendType" SG_ 145 Syn_MACInfo_Byte1_All 2;
BA_ "GenSigSendType" SG_ 145 Syn_MACInfo_Byte2_All 2;
BA_ "GenSigStartValue" SG_ 856 VCU_LV_Batt_Temp 40;
BA_ "GenSigSendType" SG_ 1936 EPS1_Rx_CCP_TPCI 1;
BA_ "GenSigSendType" SG_ 1936 EPS1_Rx_CCP_Byte2 1;
BA_ "GenSigSendType" SG_ 1936 EPS1_Rx_CCP_Byte3 1;
BA_ "GenSigSendType" SG_ 1936 EPS1_Rx_CCP_Byte4 1;
BA_ "GenSigSendType" SG_ 1936 EPS1_Rx_CCP_Byte5 1;
BA_ "GenSigSendType" SG_ 1936 EPS1_Rx_CCP_Byte6 1;
BA_ "GenSigSendType" SG_ 1936 EPS1_Rx_CCP_Byte7 1;
BA_ "GenSigSendType" SG_ 1936 EPS1_Rx_CCP_Byte8 1;
BA_ "GenSigSendType" SG_ 1983 EPS1_Tx_CCP_TPCI 1;
BA_ "GenSigSendType" SG_ 1983 EPS1_Tx_CCP_Byte2 1;
BA_ "GenSigSendType" SG_ 1983 EPS1_Tx_CCP_Byte3 1;
BA_ "GenSigSendType" SG_ 1983 EPS1_Tx_CCP_Byte4 1;
BA_ "GenSigSendType" SG_ 1983 EPS1_Tx_CCP_Byte5 1;
BA_ "GenSigSendType" SG_ 1983 EPS1_Tx_CCP_Byte6 1;
BA_ "GenSigSendType" SG_ 1983 EPS1_Tx_CCP_Byte7 1;
BA_ "GenSigSendType" SG_ 1983 EPS1_Tx_CCP_Byte8 1;
BA_ "GenSigSendType" SG_ 2564485392 Diag_Resp_EPS1 1;
BA_ "GenSigSendType" SG_ 2564485391 Diag_Resp_ESC 1;
BA_ "GenSigSendType" SG_ 2564485390 Diag_Resp_IM 1;
BA_ "GenSigSendType" SG_ 2564428017 Diag_PhyReq_EPS1 1;
BA_ "GenSigSendType" SG_ 2564427761 Diag_PhyReq_ESC 1;
BA_ "GenSigSendType" SG_ 2564427505 Diag_PhyReq_IM 1;
BA_ "GenSigSendType" SG_ 2564485381 Diag_Resp_FCM 1;
BA_ "GenSigSendType" SG_ 2564425201 Diag_PhyReq_FCM 1;
VAL_ 264 BCM_charging_flap_ajar_status 3 "Invalid" 2 "Reserved" 1 "Opened" 0 "Closed" ;
VAL_ 264 STAT_BonnetAjar 3 "Signal invalid" 2 "Reserved" 1 "Opened" 0 "Closed" ;
VAL_ 264 STAT_TrunkAjar 3 "Signal invalid" 2 "Reserved" 1 "Opened" 0 "Closed" ;
VAL_ 264 STAT_DoorAjarRR 3 "Signal invalid" 2 "Reserved" 1 "Opened" 0 "Closed" ;
VAL_ 264 STAT_DoorAjarPass 3 "Signal invalid" 2 "Reserved" 1 "Opened" 0 "Closed" ;
VAL_ 264 STAT_DoorAjarRL 3 "Signal invalid" 2 "Reserved" 1 "Opened" 0 "Closed" ;
VAL_ 264 STAT_DoorAjarDriver 3 "Signal invalid" 2 "Reserved" 1 "Opened" 0 "Closed" ;
VAL_ 264 STAT_DoorLockPassenger 3 "Signal invalid" 2 "Reserved" 1 "Locked" 0 "Unlocked" ;
VAL_ 264 STAT_CDL_LED 3 "Signal invalid" 2 "blinking" 1 "ON" 0 "OFF" ;
VAL_ 264 STAT_ATWS 7 "Signal invalid" 6 "Reserved" 5 "Reserved" 4 "Reserved" 3 "Partially set" 2 "Triggered" 1 "Unset" 0 "Set" ;
VAL_ 264 STAT_DoorLockDriver 3 "Signal invalid" 2 "Reserved" 1 "Locked" 0 "Unlocked" ;
VAL_ 433 VEH_State 7 "End-Drive" 15 "Signal invalid" 14 "Reserved" 13 "Reserved" 6 "Diagnostic" 5 "Charging" 4 "Drive" 3 "Prepare" 2 "Standby" 1 "Access" 0 "Sleep" ;
VAL_ 433 CGW_OBDConnectStatus 3 "Invalid" 2 "Not connected" 1 "Connected" 0 "Initial" ;
VAL_ 1040 BitBlinking_EPS1 3 "Signal invalid" 2 "3Hz" 1 "1Hz" 0 "No action" ;
VAL_ 1040 BitStatus_EPS1 3 "Signal invalid" 2 "Reserved" 1 "Reset" 0 "Set" ;
VAL_ 1039 BitBlinking_ESC 3 "Signal invalid" 2 "3Hz" 1 "1Hz" 0 "No action" ;
VAL_ 1039 BitStatus_ESC 3 "Signal invalid" 2 "Reserved" 1 "Reset" 0 "Set" ;
VAL_ 1038 BitBlinking_IM 3 "Signal invalid" 2 "3Hz" 1 "1Hz" 0 "No action" ;
VAL_ 1038 BitStatus_IM 3 "Signal invalid" 2 "Reserved" 1 "Reset" 0 "Set" ;
VAL_ 247 BMS_SOHlastUpdateInterval 16383 "Invalid" ;
VAL_ 247 BMS_BattCellstartframeNum 65535 "Invalid" ;
VAL_ 247 BMS_HvBattSocinstalled 1023 "Invalid" ;
VAL_ 247 BMS_HvBattSt 5 "HV_shutdownOngoing" 4 "Emergency_off" 7 "Invalid" 6 "Shutdown" 3 "HV_Ready" 2 "Pre_charging" 1 "HV_Standby" 0 "Init" ;
VAL_ 247 BMS_HvBattIMaxDchaLon 2047 "Invalid" 2046 "Error" ;
VAL_ 247 BMS_HvBattI 65535 "Invalid" ;
VAL_ 247 BMS_HvBattRlyPosSt 3 "invalid" 2 "ongoing opening" 1 "closed" 0 "open" ;
VAL_ 247 BMS_HvBattRlyNegSt 3 "invalid" 2 "ongoing opening" 1 "closed" 0 "open" ;
VAL_ 247 BMS_HvBattT30CVolt 32767 "reserved" ;
VAL_ 247 BMS_HvBattPackUDchaLim 1023 "Invalid" ;
VAL_ 247 BMS_HvBattSoeAct 2047 "Invalid" ;
VAL_ 247 BMS_HvBattU 16383 "Invalid" ;
VAL_ 247 BMS_HvBattPackUChrgnLim 1023 "Invalid" 1022 "SNA/Fault" ;
VAL_ 247 BMS_HvBattDynChrgILim 2047 "Invalid" 2046 "SNA/Fault" ;
VAL_ 247 BMS_HvBattIMaxChrgLon 2047 "Invalid" 2046 "Error" ;
VAL_ 247 BMS_HvBattSoh 127 "Init" 126 "Error" ;
VAL_ 247 BMS_HvBattChrgnAllwd 1 "charing allowed" 0 "charing not allowed" ;
VAL_ 247 BMS_HvBattSdilSt 3 "fault" 2 "open" 1 "closed" 0 "Init" ;
VAL_ 247 BMS_HVBattCellVolt 65535 "Invalid" ;
VAL_ 247 BMS_HvBattIMaxDchaMidLon 2047 "Invalid" 2046 "Error" ;
VAL_ 247 BMS_HvBattUint 8191 "Invalid" ;
VAL_ 247 BMS_HvBattIsoR_status 1 "running" 0 "disabled" ;
VAL_ 247 BMS_HvBattHvilSt 3 "fault" 2 "open" 1 "closed" 0 "Init" ;
VAL_ 247 BMS_HvBattIsoRNegGND_Ohm 65535 "Invalid" ;
VAL_ 247 BMS_HvBattIsoRPosGND_Ohm 65535 "Invalid" ;
VAL_ 247 BMS_HvBattCellVoltMax 65535 "Invalid" ;
VAL_ 247 BMS_HvBattCellVoltNom 65535 "Invalid" ;
VAL_ 247 BMS_HvBattCellVoltMin 65535 "Invalid" ;
VAL_ 247 BMS_HvBattT30Volt 32767 "Invalid" ;
VAL_ 247 BMS_HvBattRlyPrechSt 3 "invalid" 2 "ongoing opening" 1 "closed" 0 "open" ;
VAL_ 247 BMS_HvBattIMaxChrgMidLon 2047 "Invalid" 2046 "Error" ;
VAL_ 247 BMS_HvBattDynDchaILim 2047 "Invalid" ;
VAL_ 247 BMS_HvBattCellUChrgnLim 65535 "Invalid" ;
VAL_ 247 BMS_HvBattSocAct_usable 1023 "Invalid" ;
VAL_ 1029 BitBlinking_FCM 3 "Signal invalid" 2 "3Hz" 1 "1Hz" 0 "No action" ;
VAL_ 1029 BitStatus_FCM 3 "Signal invalid" 2 "Reserved" 1 "Reset" 0 "Set" ;
VAL_ 258 STAT_StartStopButton 3 "Signal Invalid" 2 "Reserved" 1 "Pressed" 0 "Not Pressed" ;
VAL_ 258 BCM_Cl30R_Off_Announcement 3 "Reserved" 2 "Cl30R_Shutdown_Announcement" 1 "No_Cl30R_Announcement" 0 "NotAvailable" ;
VAL_ 258 BCM_Cl30s_Off_Announcement 3 "Reserved" 2 "Cl30s_Shutdown_Announcement" 1 "No_Cl30s_Announcement" 0 "NotAvailable" ;
VAL_ 258 BCM_STAT_TransportMode 3 "Invalid" 2 "Reserved" 1 "Active" 0 "Not Active" ;
VAL_ 258 BCM_KL15_Off_Announcement 0 "NotAvailable" 1 "No_Announcement" 2 "KL15_shutdown_announced" 3 "Reserved" ;
VAL_ 258 BCM_ST_KL 15 "Signal invalid" 2 "KL30" 0 "Init" ;
VAL_ 258 BCM_STAT_Terminal 7 "Signal invalid" 6 "Reserved" 5 "Reserved" 4 "Reserved" 3 "30s + 30R + 15 on" 2 "30s + 30R on" 1 "30s" 0 "OFF" ;
VAL_ 258 BCM_STAT_CL30R_L 3 "Signal invalid" 2 "Failure" 1 "Cl.30R_L ON" 0 "Cl.30R_L OFF" ;
VAL_ 258 BCM_STAT_CL30s_L 3 "Signal invalid" 2 "Failure" 1 "Cl.30s ON" 0 "Cl.30s OFF" ;
VAL_ 258 BCM_STAT_CL15_L 3 "Signal invalid" 2 "Failure" 1 "Cl.15_L ON" 0 "Cl.15_L OFF" ;
VAL_ 513 ST_OCS_CalRespSts 3 "Sts_InProgs" 2 "Sts_CmplOk (Default Value)" 1 "Sts_Err" 0 "Sts_Resd" ;
VAL_ 513 ST_OCS_CalVal 7 "CalVal_Resd4" 6 "CalVal_Resd3" 5 "CalVal_Resd2" 4 "CalVal_Resd1" 3 "CalVal_DiagcTroCodPres" 2 "CalVal_ValOutOfRng" 1 "CalVal_SeatNotCal" 0 "CalVal_CalCmplOk (Default Value)" ;
VAL_ 513 ST_OCS_EOL 1 "Ok" 0 "NotOk" ;
VAL_ 513 ST_OCS_EcuFailr 1 "Boolean_TRUE" 0 "Boolean_FALSE" ;
VAL_ 513 ST_OCS_AirbAllwdSts 3 "Undefd2" 2 "AirbActvnAllwd" 1 "AirbActvnInhb (Default Value)" 0 "Undefd1" ;
VAL_ 513 ST_OCS_ERROR 7 "Multiple Error / Reserved" 6 "Indeterminate Class Error" 5 "Build Check Error" 4 "Vbatt too Low Error" 3 "Vbatt too High Error" 2 "Wet Seat Error" 1 "ECU Error" 0 "No Error" ;
VAL_ 513 ST_SEAT_POS_PAS 3 "Invalid / system fault" 2 "Init / reserved" 1 "Seat in the front" 0 "Seat in the rear" ;
VAL_ 513 ST_SEAT_POS_DRV 3 "Invalid / system fault" 2 "Init / reserved" 1 "Seat in the front" 0 "Seat in the rear" ;
VAL_ 513 ST_PAB_SW 0 "PAB switch in State off" 1 "PAB switch in State on" 2 "Init" 3 "Invalid / system fault" ;
VAL_ 513 ST_PAB_ON 0 "LED off" 1 "LED on" ;
VAL_ 513 ST_BELT_BUCK_RM 0 "not buckled" 1 "buckled" 2 "init" 3 "signal invalid" ;
VAL_ 513 ST_IGN_ACM 0 "CL15 Input ACM inactive" 1 "CL15 Input ACM active" ;
VAL_ 513 ST_CRS_DET 0 "Crash Detection not available" 1 "Crash Detection available" 2 "Limited Crash Detection availabl" 3 "Invalid / System Fault" ;
VAL_ 513 ST_COD 7 "Invalid" 6 "Reserved" 5 "GLOBAL" 4 "CHINA" 0 "Not coded" 1 "ECE" 2 "US" 3 "ROW" ;
VAL_ 513 ST_BELT_BUCK_RR 0 "not buckled" 1 "buckled" 2 "init" 3 "signal invalid" ;
VAL_ 513 ST_BELT_BUCK_RL 0 "not buckled" 1 "buckled" 2 "init" 3 "signal invalid" ;
VAL_ 513 ST_BELT_BUCK_PS 0 "not buckled" 1 "buckled" 2 "init" 3 "signal invalid" ;
VAL_ 513 ST_SEAT_OCCU_PS 2 "Init" 0 "Seat not occupied" 1 "Seat occupied" 3 "Signal not valid (failure state)" ;
VAL_ 513 ST_BELT_BUCK_DR 0 "not buckled" 1 "buckled" 2 "init" 3 "signal invalid" ;
VAL_ 513 ST_PAB_OFF 0 "LED off" 1 "LED on" ;
VAL_ 1305 usrData1_TPM_Bit7_ECUSPEC_AWAKE 0 "inactive" 1 "active" ;
VAL_ 1305 usrData1_TPM_Bit6_DIAGN_AWAKE 0 "inactive" 1 "active" ;
VAL_ 1305 usrData1_TPM_Bit5_IGNITION_AWAKE 0 "inactive" 1 "active" ;
VAL_ 1305 usrData1_TPM_Bit4_NETWORK_AWAKE 0 "inactive" 1 "active" ;
VAL_ 1305 usrData1_TPM_Bit3_ECUSPEC_WAKEUP 0 "inactive" 1 "active" ;
VAL_ 1305 usrData1_TPM_Bit2_NETWORK_WAKEUP 0 "inactive" 1 "active" ;
VAL_ 1305 usrData1_TPM_Bit1_RESET_WAKEUP 0 "inactive" 1 "active" ;
VAL_ 1305 CtrlBitVector_TPM_Bit3_NMCoord 0 "Start of synchronized shutdown is not requested by main coordinator" 1 "Start of synchronized shutdown is requested by main coordinator" ;
VAL_ 1305 usrData1_TPM_Bit0_IGN_WAKEUP 0 "inactive" 1 "active" ;
VAL_ 1305 usrData0_TPM 0 "User data for current vehicle without partial networking" 1 "User data for current vehicle with partial networking" 255 "User data not used" ;
VAL_ 1284 usrData1_VCU_Bit7_ECUSPEC_AWAKE 0 "inactive" 1 "active" ;
VAL_ 1284 usrData1_VCU_Bit6_DIAGN_AWAKE 0 "inactive" 1 "active" ;
VAL_ 1284 usrData1_VCU_Bit5_IGNITION_AWAKE 0 "inactive" 1 "active" ;
VAL_ 1284 usrData1_VCU_Bit4_NETWORK_AWAKE 0 "inactive" 1 "active" ;
VAL_ 1284 usrData1_VCU_Bit3_ECUSPEC_WAKEUP 0 "inactive" 1 "active" ;
VAL_ 1284 usrData1_VCU_Bit2_NETWORK_WAKEUP 0 "inactive" 1 "active" ;
VAL_ 1284 usrData1_VCU_Bit1_RESET_WAKEUP 0 "inactive" 1 "active" ;
VAL_ 1284 CtrlBitVector_VCU_Bit3_NMCoord 0 "Start of synchronized shutdown is not requested by main coordinator" 1 "Start of synchronized shutdown is requested by main coordinator" ;
VAL_ 1284 usrData1_VCU_Bit0_IGN_WAKEUP 0 "inactive" 1 "active" ;
VAL_ 1284 usrData0_VCU 0 "User data for current vehicle without partial networking" 1 "User data for current vehicle with partial networking" 255 "User data not used" ;
VAL_ 594 SAS_TrimmingSts 1 "Sensor trimmed" 0 "Sensor not trimmed" ;
VAL_ 594 SAS_CalibrationSts 1 "Valid" 0 "Invalid" ;
VAL_ 594 SAS_FailureSts 1 "Valid" 0 "Invalid" ;
VAL_ 594 SAS_SteerWheelRotSpd 255 "Signal invalid" ;
VAL_ 594 SAS_SteerWheelAngle 32767 "Signal invalid" ;
VAL_ 592 SCM_SteeringWheel_rotation_flag 1 "rotation" 0 "no rotation" ;
VAL_ 592 SCM_IHBC_MenuReq 1 "Pressed" 0 "Released" ;
VAL_ 592 SCM_IHBC_MenuReqInvalid 1 "Invalid" 0 "Valid" ;
VAL_ 592 SCM_SW_MasterLightSwitch 15 "Signal invalid" 14 "Reserved" 13 "Reserved" 12 "Reserved" 11 "Reserved" 10 "Resvered" 9 "Resvered" 8 "Position light on" 7 "Resvered" 6 "Resvered" 5 "Resvered" 4 "Resvered" 3 "Resvered" 2 "Auto light on" 1 "Low beam on" 0 "Light off" ;
VAL_ 592 SCM_SW_DaytimeLight 1 "Pressed" 0 "Released" ;
VAL_ 592 SCM_SW_DaytimeLightInvalid 1 "Invalid" 0 "Valid" ;
VAL_ 592 SCM_SW_Trip 3 "Invalid" 2 "Longpress" 1 "Pressed" 0 "Released" ;
VAL_ 592 SCM_Req_TurnIndicationAct 3 "Invalid" 2 "Turn Right" 1 "Turn Left" 0 "Default" ;
VAL_ 592 SCM_RearWipingMode 3 "Invalid" 2 "Rear Wiper Interval" 1 "Rear Wiper Uniformity Speed" 0 "Rear Wiper Off" ;
VAL_ 592 SCM_SW_FrontFogLight 1 "Pressed" 0 "Released" ;
VAL_ 592 SCM_SW_FrontFogLightInvalid 1 "Invalid" 0 "Valid" ;
VAL_ 592 SCM_SW_RearFogLight 1 "Pressed" 0 "Released" ;
VAL_ 592 SCM_SW_RearFogLightInvalid 1 "Invalid" 0 "Valid" ;
VAL_ 592 SCM_WipingInterval_Sensitvity 7 "Reserved" 6 "Sensitivity 6" 5 "Sensitivity 5" 4 "Sensitivity 4" 3 "Sensitivity 3" 2 "Sensitivity 2" 1 "Sensitivity 1" 0 "Sensitivity 0" ;
VAL_ 592 SCM_FrontWipingMode 7 "Invalid" 6 "Reserved" 5 "Reserved" 4 "FrontWiperAuto/Int" 3 "FrontWiperMist" 2 "FrontWiperHigh" 1 "FrontWiperLow" 0 "FrontWiperOff" ;
VAL_ 592 SCM_SW_FlashLightSts 1 "Pressed" 0 "Released" ;
VAL_ 592 SCM_SW_FlashLightStsInvalid 1 "Invalid" 0 "Valid" ;
VAL_ 592 SCM_SW_RWasherSts 1 "Pressed" 0 "Release" ;
VAL_ 592 SCM_SW_RWasherStsInvalid 1 "Invalid" 0 "Valid" ;
VAL_ 592 SCM_SW_FWasherSts 1 "Pressed" 0 "Released" ;
VAL_ 592 SCM_SW_FWasherStsInvalid 1 "Invalid" 0 "Valid" ;
VAL_ 592 SCM_SW_HighBeam 1 "On" 0 "Off" ;
VAL_ 592 SCM_SW_HighBeamInvalid 1 "Invalid" 0 "Valid" ;
VAL_ 389 FCM_PDC_ROR_USSSts 2 "Cover" 1 "Fault" 0 "No fault" ;
VAL_ 389 FCM_PDC_ROL_USSSts 2 "Cover" 1 "Fault" 0 "No fault" ;
VAL_ 389 FCM_PDC_FOR_USSSts 2 "Cover" 1 "Fault" 0 "No fault" ;
VAL_ 389 FCM_PDC_FOL_USSSts 2 "Cover" 1 "Fault" 0 "No fault" ;
VAL_ 389 FCM_PDC_RIR_USSSts 2 "Cover" 1 "Fault" 0 "No fault" ;
VAL_ 389 FCM_PDC_RIL_USSSts 2 "Cover" 1 "Fault" 0 "No fault" ;
VAL_ 389 FCM_PDC_RearAudWarn 4 "Reserved " 3 "BuzzerReq_BuzzerONat2Hz" 2 "BuzzerReq_BuzzerONat4Hz" 1 "BuzzerReq_BuzzerON" 0 "BuzzerReq_BuzzerOFF" ;
VAL_ 389 FCM_PDC_FrontAudWarn 4 "Reserved " 3 "BuzzerReq_BuzzerONat2Hz" 2 "BuzzerReq_BuzzerONat4Hz" 1 "BuzzerReq_BuzzerON" 0 "BuzzerReq_BuzzerOFF" ;
VAL_ 389 FCM_PDC_FailrWarn 1 "WarningInd_Warning" 0 "WarningInd_NoWarning" ;
VAL_ 389 FCM_PDC_ToneVol 1 "PDC_Volume_ON" 0 "PDC_Volume_OFF" ;
VAL_ 389 FCM_PDC_Mode 9 "Reserved" 8 "Rear active & front failure" 7 "Front active & rear failure" 6 "Half failure standby" 5 "Failure" 4 "RearActive" 3 "FrontActive" 2 "FrontRearActive" 1 "Standby" 0 "Off" ;
VAL_ 389 FCM_PDC_Distance_ROR 7 "PDC_SensorDistance_Range7" 6 "PDC_SensorDistance_Range6" 5 "PDC_SensorDistance_Range5" 4 "PDC_SensorDistance_Range4" 3 "PDC_SensorDistance_Range3" 2 "PDC_SensorDistance_Range2" 1 "PDC_SensorDistance_Range1" 0 "PDC_SensorDistance_NoDistance" ;
VAL_ 389 FCM_PDC_Distance_RIR 7 "PDC_SensorDistance_Range7" 6 "PDC_SensorDistance_Range6" 5 "PDC_SensorDistance_Range5" 4 "PDC_SensorDistance_Range4" 3 "PDC_SensorDistance_Range3" 2 "PDC_SensorDistance_Range2" 1 "PDC_SensorDistance_Range1" 0 "PDC_SensorDistance_NoDistance" ;
VAL_ 389 FCM_PDC_Distance_RIL 7 "PDC_SensorDistance_Range7" 6 "PDC_SensorDistance_Range6" 5 "PDC_SensorDistance_Range5" 4 "PDC_SensorDistance_Range4" 3 "PDC_SensorDistance_Range3" 2 "PDC_SensorDistance_Range2" 1 "PDC_SensorDistance_Range1" 0 "PDC_SensorDistance_NoDistance" ;
VAL_ 389 FCM_PDC_Distance_ROL 0 "PDC_SensorDistance_NoDistance" 7 "PDC_SensorDistance_Range7" 6 "PDC_SensorDistance_Range6" 5 "PDC_SensorDistance_Range5" 4 "PDC_SensorDistance_Range4" 3 "PDC_SensorDistance_Range3" 2 "PDC_SensorDistance_Range2" 1 "PDC_SensorDistance_Range1" ;
VAL_ 389 FCM_PDC_Distance_FOR 7 "PDC_SensorDistance_Range7" 6 "PDC_SensorDistance_Range6" 5 "PDC_SensorDistance_Range5" 4 "PDC_SensorDistance_Range4" 3 "PDC_SensorDistance_Range3" 2 "PDC_SensorDistance_Range2" 1 "PDC_SensorDistance_Range1" 0 "PDC_SensorDistance_NoDistance" ;
VAL_ 389 FCM_PDC_Distance_FIR 7 "PDC_SensorDistance_Range7" 6 "PDC_SensorDistance_Range6" 5 "PDC_SensorDistance_Range5" 4 "PDC_SensorDistance_Range4" 3 "PDC_SensorDistance_Range3" 2 "PDC_SensorDistance_Range2" 1 "PDC_SensorDistance_Range1" 0 "PDC_SensorDistance_NoDistance" ;
VAL_ 389 FCM_PDC_Distance_FIL 7 "PDC_SensorDistance_Range7" 6 "PDC_SensorDistance_Range6" 5 "PDC_SensorDistance_Range5" 4 "PDC_SensorDistance_Range4" 3 "PDC_SensorDistance_Range3" 2 "PDC_SensorDistance_Range2" 1 "PDC_SensorDistance_Range1" 0 "PDC_SensorDistance_NoDistance" ;
VAL_ 389 FCM_PDC_Distance_FOL 7 "PDC_SensorDistance_Range7" 6 "PDC_SensorDistance_Range6" 5 "PDC_SensorDistance_Range5" 4 "PDC_SensorDistance_Range4" 3 "PDC_SensorDistance_Range3" 2 "PDC_SensorDistance_Range2" 1 "PDC_SensorDistance_Range1" 0 "PDC_SensorDistance_NoDistance" ;
VAL_ 389 FCM_PDC_FIR_USSSts 2 "Cover" 1 "Fault" 0 "No fault" ;
VAL_ 389 FCM_PDC_FIL_USSSts 2 "Cover" 1 "Fault" 0 "No fault" ;
VAL_ 389 FCM_PDC_FltMod 5 "TrailerMode & FrontUSSFault" 4 "TrailerMode" 3 "FrontAndRearUSSFault" 2 "RearUSSFault" 1 "FrontUSSFault" 0 "Normal" ;
VAL_ 389 FCM_PDC_USSCoverSt 3 "FrontAndRearUSSCovered" 2 "RearUSSCovered" 1 "FrontUSSCovered" 0 "Normal" ;
VAL_ 389 FCM_PDC_FrntPDCBtnSts 2 "Inhibit" 1 "ON" 0 "OFF" ;
VAL_ 272 VCU_AccelPedalSts 3 "Fault" 2 "Unavaiable" 1 "Pressed" 0 "Not Pressed" ;
VAL_ 272 VCU_CC_SpdLim_Sts 7 "Invalid" 6 "Reserved - SpeedLim Standby" 5 "Reserved - CC Standby" 4 "Error" 3 "LIM active" 2 "CC active" 1 "Not active" 0 "Init" ;
VAL_ 272 VCU_ActSt 0 "Sleep" 1 "Init" 2 "Active" 3 "Prepare shutdown" 4 "Shutdown" 5 "Reserved" 6 "Reserved" 7 "Reserved" 8 "Reserved" ;
VAL_ 272 VCU_GearSig 0 "Undefined_initial_value" 1 "gear_P" 2 "gear_N" 3 "gear_R" 4 "grear_D" 5 "engage_P" 6 "Reserved" 7 "Reserved" 8 "Fault" 9 "Reserved" 10 "Reserved" 11 "Reserved" 12 "Reserved" 13 "Reserved" 14 "Reserved" 15 "Reserved" ;
VAL_ 272 VCU_GearSig_Q 0 "Initializing" 1 "Valid" 2 "Invalid" 3 "Reserved" ;
VAL_ 327 EDU_F_ParkLock_Sts 0 "state_undefined" 1 "Parklock_engaged" 2 "Parklock_disengaged" 3 "Shift in progress" 4 "Reserved" 5 "Reserved" 6 "Init" 7 "Error" ;
VAL_ 327 EDU_F_ActTq_Q 0 "Initializing" 1 "Valid" 2 "Invalid" 3 "Reserved" ;
VAL_ 327 EDU_F_ActSpd 32767 "Invalid" ;
VAL_ 327 EDU_F_ActTq 511 "Invalid" ;
VAL_ 327 EDU_F_ActSpdSig_Q 0 "Initializing" 1 "Valid" 2 "Invalid" 3 "Reserved" ;
VAL_ 327 EDU_F_ActMod 15 "Invalid" 0 "Init(default)" 1 "LV Ready" 2 "Standby" 3 "Freewheeling" 4 "Torque_mode" 5 "Reserved" 6 "Reserved" 7 "Postrun(BusActive)" 8 "Sleep ready (BusIdle)" 9 "Service Job" 10 "Reserved" 11 "Reserved" 12 "Reserved" 13 "Reserved" 14 "Reserved" ;
VAL_ 327 EDU_F_HVActvDcha_Sts 0 "Not_discharged" 1 "Discharging" 2 "Discharge_complete" 3 "Discharge_failure" 4 "Reserved" 5 "Reserved" 6 "Init_(dbc_init_value)" 7 "Invalid" ;
VAL_ 327 EDU_F_SlipCtrlAct_Sts 0 "Slip_control_deactivated" 1 "Slip_control_idling" 2 "Slip_control_working" 3 "Fault" ;
VAL_ 327 EDU_F_WarningLamp_FS 0 "Disable" 1 "Enable" ;
VAL_ 327 EDU_F_HVChkEnd_Sts 0 "Not_completed" 1 "Completed" ;
VAL_ 328 EDU_R_Trans_gear_Sts 15 "invalid" 5 "Fail" 4 "InTransition" 3 "N" 2 "2" 1 "1" 0 "Init" ;
VAL_ 328 EDU_R_ActSpd 32767 "Invalid" ;
VAL_ 328 EDU_R_ActTq 511 "Invalid" ;
VAL_ 328 EDU_R_ActTq_Q 0 "Initializing" 1 "Valid" 2 "Invalid" 3 "Reserved" ;
VAL_ 328 EDU_R_ActSpdSig_Q 0 "Initializing" 1 "Valid" 2 "Invalid" 3 "Reserved" ;
VAL_ 328 EDU_R_ActMod 15 "Invalid" 0 "Init(default)" 1 "LV Ready" 2 "Standby" 3 "Freewheeling" 4 "Torque_mode" 5 "Reserved" 6 "Reserved" 7 "Postrun(BusActive)" 8 "Sleep ready (BusIdle)" 9 "Service Job" 10 "Reserved" 11 "Reserved" 12 "Reserved" 13 "Reserved" 14 "Reserved" ;
VAL_ 328 EDU_R_HVActvDcha_Sts 0 "Not_discharged" 1 "Discharging" 2 "Discharge_complete" 3 "Discharge_failure" 4 "Reserved" 5 "Reserved" 6 "Init_(dbc_init_value)" 7 "Invalid" ;
VAL_ 328 EDU_R_SlipCtrlAct_Sts 0 "Slip_control_deactivated" 1 "Slip_control_idling" 2 "Slip_control_working" 3 "Fault" ;
VAL_ 328 EDU_R_Warninglamp_FS 0 "Disable" 1 "Enable" ;
VAL_ 328 EDU_R_HVChkEnd_Sts 0 "Not_completed" 1 "Completed" ;
VAL_ 1285 usrData1_FCM_Bit7_ECUSPEC_AWAKE 0 "inactive" 1 "active" ;
VAL_ 1285 usrData1_FCM_Bit6_DIAGN_AWAKE 0 "inactive" 1 "active" ;
VAL_ 1285 usrData1_FCM_Bit5_IGNITION_AWAKE 0 "inactive" 1 "active" ;
VAL_ 1285 usrData1_FCM_Bit4_NETWORK_AWAKE 0 "inactive" 1 "active" ;
VAL_ 1285 usrData1_FCM_Bit3_ECUSPEC_WAKEUP 0 "inactive" 1 "active" ;
VAL_ 1285 usrData1_FCM_Bit2_NETWORK_WAKEUP 0 "inactive" 1 "active" ;
VAL_ 1285 usrData1_FCM_Bit1_RESET_WAKEUP 0 "inactive" 1 "active" ;
VAL_ 1285 CtrlBitVector_FCM_Bit3_NMCoord 0 "Start of synchronized shutdown is not requested by main coordinator" 1 "Start of synchronized shutdown is requested by main coordinator" ;
VAL_ 1285 usrData1_FCM_Bit0_IGN_WAKEUP 0 "inactive" 1 "active" ;
VAL_ 1285 usrData0_FCM 0 "User data for current vehicle without partial networking" 1 "User data for current vehicle with partial networking" 255 "User data not used" ;
VAL_ 384 FCM_AESA_IndcrLiReq 5 "Invalid" 4 "Turn indicator OFF" 3 "Hazard" 2 "Right turn indicator" 1 "Left turn indicator" 0 "No request" ;
VAL_ 384 FCM_PDC_BtnLEDSts 1 "ON" 0 "OFF" ;
VAL_ 384 FCM_ELK_WarnLvl 2 "ACOUSTIC WARNING" 1 "OPTICAL WARNING" 0 "NO WARNING" 3 "ACOUSTIC & OPTICAL WARNING" ;
VAL_ 384 FCM_AEB_Req 3 "Invalid" 2 "Fault" 1 "Request" 0 "No request" ;
VAL_ 384 FCM_AEB_PrefillReq 1 "PREFILL_REQUESTED" 0 "PREFILL_NOT_REQUESTED" ;
VAL_ 384 FCM_DBS_Req 3 "Invalid" 2 "Fault" 1 "Request" 0 "No request" ;
VAL_ 384 FCM_AEB_FCWAlertReq 3 "ALERT_REMINDER" 2 "COLLISION_ALERT" 1 "APPROACH_ALERT" 0 "NO_ALERT" ;
VAL_ 384 FCM_AEB_CnclReasn 15 "ADAS_ECU_PERMANENT_FAILURE" 14 "ADAS_ECU_TEMPORARY_FAILURE" 13 "ACCEL_PEDAL_HIGH_TEMP" 12 "BAD_WEATHER" 11 "RACE_MODE" 10 "TRAILER_PRESENCE" 9 "FR_SIDE_RADAR_PERMANENT_FAILURE" 8 "FRONT_SIDE_RADAR_BLOCKED" 7 "RADAR_PERMANENT_FAILURE" 6 "RADAR_BLOCKED" 5 "FRCAM_PERMANENT_FAILURE" 4 "FRCAM_HIGH_TEMPERATURE" 3 "FRCAM_BLOCKED" 2 "VDC_IN_REGULATION" 1 "VDC_DEACTIVATED_BY_DRIVER" 0 "NO_DISPLAY" ;
VAL_ 384 FCM_AEB_FCWSnvtySt 3 "LATE" 2 "STANDARD" 1 "EARLY" 0 "UNAVAILABLE" ;
VAL_ 384 FCM_AEB_StsDisp 7 "RESERVED" 6 "INITIAL" 5 "PERMANENT_FAILURE" 4 "TEMPORARY_FAILURE" 3 "NO_OPERATION" 2 "OPERATION" 1 "AEB_OFF" 0 "NO_DISPLAY" ;
VAL_ 384 FCM_AEB_ActvnSt 3 "AEB_ON/FCW_ON" 2 "Reserved" 1 "AEB_OFF/FCW_ON" 0 "AEB_OFF/FCW_OFF" 4 "Error" ;
VAL_ 384 FCM_ASA_Fuli_MainSignSL 255 "UNKOWN" 254 "No_SPEED" ;
VAL_ 384 FCM_ASA_TFMapExpired 1 "True" 0 "False" ;
VAL_ 384 FCM_ASA_TFDrivgSide 3 "Unknown" 2 "Left side" 1 "Right side" 0 "Unavailable value" ;
VAL_ 384 FCM_ASA_ReconstructorSts 7 "RESERVED" 6 "RESERVED" 5 "RESERVED" 4 "MISSING_ADASIS_FRAME" 3 "RECONSTRUCTION_ONLINE:NORMAL" 2 "ERROR" 1 "INITIALIZING" 0 "DISABLED" ;
VAL_ 384 FCM_ASA_CondlInfoMapSL 15 "NOT_USED" 14 "NOT_USED" 13 "NOT_USED" 12 "NOT_USED" 11 "NOT_USED" 10 "NOT_USED" 9 "NOT_USED" 8 "NOT_USED" 7 "RAIN" 6 "NOT_USED" 5 "NOT_USED" 4 "NOT_USED" 3 "TRAILER" 2 "SNOW" 1 "TIME" 0 "NCONDITIONAL_SPEED_LIMIT" ;
VAL_ 384 FCM_ASA_SpdLimMai 255 "UNKNOWN" 254 "NO_SPEED" ;
VAL_ 384 FCM_LCDAS_SoundWarnReq 1 "Acoustic_Warning" 0 "No_Warning" ;
VAL_ 384 FCM_RCTA_RiAlertSt 3 "ACTION_ALERT" 2 "WARN_ALERT" 1 "INFO_ALERT" 0 "NO_ALERT" ;
VAL_ 384 FCM_RCTA_LeAlertSt 3 "ACTION_ALERT" 2 "WARN_ALERT" 1 "INFO_ALERT" 0 "NO_ALERT" ;
VAL_ 384 FCM_LCDAS_RiAlertSt 3 "Selftest" 1 "Warning_Level_1" 0 "No_Warning_OFF" 7 "Invalid" 2 "Warning_Level_2" 6 "Reserved" 5 "Reserved" 4 "Reserved" ;
VAL_ 384 FCM_LCDAS_LeAlertSt 3 "Selftest" 1 "Warning_Level_1" 0 "No_Warning_OFF" 2 "Warning_Level_2" 7 "Invalid" 6 "Reserved" 5 "Reserved" 4 "Reserved" ;
VAL_ 384 FCM_LCDAS_Sts 3 "LCDAS_Error" 2 "LCDAS_Active" 1 "LCDAS_Passive" 0 "LCDAS_Off" 7 "Invalid" 6 "Reserved" 5 "Reserved" 4 "Reserved" ;
VAL_ 384 FCM_HzrdLampReq 1 "Request" 0 "No Request" ;
VAL_ 384 FCM_SteerWheelTakeoverAlert 7 "RESERVED" 6 "ALERT LEVEL 4" 5 "ALERT LEVEL 3 MRM LEVEL 2" 4 "ALERT LEVEL 3 MRM LEVEL 1" 3 "ALERT LEVEL 3" 2 "ALERT LEVEL 2" 1 "ALERT LEVEL 1" 0 "NO ALERT" ;
VAL_ 384 FCM_LKA_WarnLvl 2 "ACOUSTICAL WARNING" 1 "OPTICAL WARNING" 0 "NO WARNING" ;
VAL_ 384 FCM_LCS_Actv 1 "Active" 0 "Not Active" ;
VAL_ 384 FCM_LCA_Actv 1 "Active" 0 "Not Active" ;
VAL_ 384 FCM_LatFctCnclReason 0 "tbd" ;
VAL_ 384 FCM_LatFctSts 5 "SERVICE" 4 "FAILURE" 3 "RUN" 2 "READY" 1 "SUSPEND" 0 "STANDBY" ;
VAL_ 384 FCM_SteerWhlCtrlOrder 1 "lateral control requested" 0 "lateral control not requested" ;
VAL_ 384 FCM_ACC_WarnLvl 2 "ACOUSTICAL WARNING" 1 "OPTICAL WARNING" 0 "NO WARNING" ;
VAL_ 384 FCM_ACC_SetSpdUnit 3 "Signal Invalid" 1 "miles/h" 0 "km/h" ;
VAL_ 384 FCM_ACC_SetSpd 255 "Signal Invalid" ;
VAL_ 384 FCM_ACC_SetDst 7 "Reserved" 6 "Reserved" 5 "Reserved" 4 "4th level distance" 3 "3rd level distance" 2 "2nd level distance" 1 "1st level distance" 0 "No time gap" ;
VAL_ 384 FCM_ACC_CuttingInSts 1 "Detected" 0 "Not detected" ;
VAL_ 384 FCM_ACC_OffWeather 1 "On" 0 "Off" ;
VAL_ 384 FCM_ACC_DrvrBrkReq 1 "Request" 0 "No Request" ;
VAL_ 384 FCM_ACC_CtrlActv 1 "Active" 0 "Not Active" ;
VAL_ 384 FCM_ACC_LeadingCarDisplay 1 "DISPLAY_REQUESTED" 0 "DISPLAY_NOT_REQUESTED" ;
VAL_ 384 FCM_ACC_CnclReasn 0 "tbd" ;
VAL_ 384 FCM_ACC_Sts 8 "Fault" 7 "Standstill Wait" 6 "Standstill Active" 5 "Override" 4 "Active" 3 "Standby" 2 "Inhibited" 1 "OFF" 0 "Initialization" ;
VAL_ 384 FCM_ASA_DrvgContext 7 "RESERVED" 6 "MOTORWAY" 5 "COUNTRY_ROAD" 4 "HIGHWAY" 3 "PEDESTRIAN_AREA" 2 "RESIDENTIAL_AREA" 1 "CITY" 0 "UNKNOWN" ;
VAL_ 384 FCM_ASA_SpdLimMap 255 "UNKNOWN" 254 "NO_SPEED" ;
VAL_ 384 FCM_ASA_SpdUnit 3 "UNAVAIABLE" 2 "MILES/HOUR" 1 "KM/HOUR" 0 "UNKOWN" ;
VAL_ 384 FCM_ASA_FailrReasn 7 "RESERVED" 6 "RESERVED" 5 "RESERVED" 4 "RESERVED" 3 "FRONT_CAMERA_TEMPORARY_FAILURE" 2 "CAMERA_HW_PERMANENT_FAILURE" 1 "VISION_IMPAIRED" 0 "NFAILURE" ;
VAL_ 384 FCM_ASA_ConditionalInfo 15 "Reserved" 14 "BUMP" 13 "ZONE_END" 12 "ZONE" 11 "FOG" 10 "GENERIC" 9 "LANE_SPECIFIC" 8 "DISATANCE_FOR" 7 "RAIN" 6 "CONSTRUCTION_AREA" 5 "EGIN_EXIT_RIGHT" 4 "EGIN_EXIT_LEFT" 3 "TRAILER" 2 "SNOW" 1 "TIME" 0 "NCONDITIONAL_SL" ;
VAL_ 384 FCM_ASA_Mod 7 "Active:INIT" 6 "Reserved" 5 "DEACTIVE" 4 "FAILURE" 3 "ACTIVE:WAITING" 2 "ACTIVE:MAP_ONLY " 1 "ACTIVE:FUSION" 0 "INITIALIZING " ;
VAL_ 384 FCM_ASA_SpdLimConfd 100 "Signal Invalid" ;
VAL_ 384 FCM_DRA_AESA_DoorUnlock_Req 1 "Requested" 0 "No request" ;
VAL_ 384 FCM_ADB_Failr 3 "Invalid" 2 "AHL No Failure" 1 "AHL Failure" 0 "Not used" ;
VAL_ 384 FCM_ADB_Req 3 "Invalid" 2 "AHL High Beam Request" 1 "AHL Low Beam Request" 0 "Not used" ;
VAL_ 416 EDU_F_Difflock_Sts 6 "Engaged" 5 "Change in progress to engaged" 4 "Change in progress to disengaged" 3 "Disengaged" 2 "Not assembled" 1 "Error" 0 "Init" ;
VAL_ 416 EDU_F_Interlock_Sts 3 "Invalid" 2 "Active" 1 "Not active" 0 "Init" ;
VAL_ 419 EDU_R_Difflock_Sts 6 "Engaged" 5 "Change in progress to engaged" 4 "Change in progress to disengaged" 3 "Disengaged" 2 "Not assembled" 1 "Error" 0 "Init" ;
VAL_ 419 EDU_R_Interlock_Sts 3 "Invalid" 2 "Active" 1 "Not active" 0 "Init" ;
VAL_ 422 VCU_ModeReq_EDU_R 7 "Reserved" 6 "Reserved" 5 "Reserved" 4 "Torque Mode" 3 "Freewheeling" 2 "Standby" 1 "Reserved" 0 "Init" ;
VAL_ 422 VCU_Difflockreq_EDU_R 2 "Disengage" 1 "Engage" 0 "Init" ;
VAL_ 422 VCU_Difflockreq_EDU_F 2 "Disengage" 1 "Engage" 0 "Init" ;
VAL_ 422 VCU_HVActvDchaReq_EDU_R 2 "init" 1 "discharge" 0 "no_discharge" ;
VAL_ 422 VCU_HVActvDchaReq_EDU_F 2 "init" 1 "discharge" 0 "no_discharge" ;
VAL_ 422 VCU_AntiOsciReq_EDU_R 3 "Invalid" 2 "Active" 1 "Not active" 0 "Init" ;
VAL_ 422 VCU_DriveMode 5 "Offroad_Wading" 4 "Offroad" 3 "Gravel" 2 "Comfort" 1 "ECO" 0 "Init" ;
VAL_ 422 VCU_ModeReq_EDU_F 7 "Reserved" 6 "Reserved" 5 "Reserved" 4 "Torque Mode" 3 "Freewheeling" 2 "Standby" 1 "Reserved" 0 "Init" ;
VAL_ 422 VCU_ParklockReq_EDU_F 2 "Disengange_Parklock" 1 "Engange_Parklock" 0 "Init" ;
VAL_ 422 VCU_AntiOsciReq_EDU_F 3 "Invalid" 2 "Active" 1 "Not active" 0 "Init" ;
VAL_ 422 VCU_EmgyReq 1 "Active" 0 "Not active" ;
VAL_ 422 VCU_TransgearReq_EDU_R 15 "Invalid" 4 "Reserved" 3 "N" 2 "2" 1 "1" 0 "Init" ;
VAL_ 300 iBooster_ExtBrkReqSts 0 "EBR_Initializing" 1 "EBR_NotAvailable" 2 "EBR_Available" 3 "Reserved" ;
VAL_ 300 iBooster_ExtReqPrioFlg 0 "EBR_Not_Dominate_The_Brake_Torque" 1 "EBR_Dominate_The_Brake_Torque" ;
VAL_ 300 iBooster_DrvrBrkPedlTrvlSts 0 "Initializing" 1 "Valid" 2 "Invalid" 3 "Reserved" ;
VAL_ 300 iBooster_MstCylBrkPedlActTrvlSts 0 "Initializing" 1 "Valid" 2 "Invalid" 3 "Reserved" ;
VAL_ 300 iBooster_StopBackupState2Main 0 "NotAvailable_Temporary" 1 "NotAvailable_NotReleased" 2 "NotAvailable_Permanent" 3 "NotActivated_Fullavailable" 4 "Activation_Preparation" 5 "Activation_Pending" 6 "Activation_PendingRedundancyLost" 7 "Activation_PendingFailOperation" 8 "Acivated_Fullavailable" 9 "Acivated_FailOperation" 10 "Acivated_RedundancyLost" 11 "Deactivation_Pending" 12 "Reserved" 13 "Reserved" 14 "Reserved" 15 "Reserved" ;
VAL_ 300 iBooster_TarStgyMod 0 "RPR_Passive" 1 "RPR_Preload" 2 "RPR_Hold" 3 "RPR_Suction" 4 "RPR_Hold_Low_Pressure" 5 "RPR_Abort" 6 "Reserved" 7 "Reserved" ;
VAL_ 300 iBooster_ReqFlg_HBC 0 "No_HBC_Support_Requested" 1 "HBC_Full_Support_Requested" ;
VAL_ 300 iBooster_PdelFPotlPSts 0 "Initializing" 1 "Valid" 2 "Invalid" 3 "Reserved" ;
VAL_ 300 iBooster_MaxMstCylPSts 0 "Initializing" 1 "Valid" 2 "Invalid" 3 "Reserved" ;
VAL_ 300 iBooster_DiagFlg 0 "IBooster_Diagnosis_Is_Inactive" 1 "IBooster_Diagnosis_Is_Active" ;
VAL_ 448 FCM_LDW_SteerWheelVibrReq 3 "reserved" 2 "reserved" 1 "LDW vibration on" 0 "LDW vibration off" ;
VAL_ 448 ADAS_FCM_ACC_PopUpMsg 15 "Reserved" 14 "Reserved" 13 "Reserved" 12 "Reserved" 11 "Reserved" 10 "Take over driving ACC Overspeed" 9 "Take over driving SpeedAssistOff" 8 "Take over driving now!" 7 "Speed Assist off below 20kph" 6 "Speed Assist is unavailable" 5 "Resume not available Please acti" 4 "Speed Assist is unavailable Cond" 3 "Press gas pedal to re-engage" 2 "None (Feature Off)" 1 "None (Feature On)" 0 "-" ;
VAL_ 448 FCM_ACC_StandstillReq 3 "Invalid" 2 "DriveOff request" 1 "Standstill request" 0 "No request (default)" ;
VAL_ 448 FCM_ADAS_LatCtrlSts 0 "Inactive" 1 "Active" 2 "Degraded" 3 "Failure" 4 "Severe_Failure" 5 "Dyno_Mode_On_(controller_inactive)" 6 "Workshop_Mode_On_(controller_inactive)" 7 "Reserved" ;
VAL_ 448 FCM_ADAS_LatCtrlStsVld 0 "Initializing" 1 "Valid" 2 "Invalid" 3 "Reserved" ;
VAL_ 448 FCM_ADAS_LatCtrlDrvrOvrd 0 "No_override" 1 "driver_override" ;
VAL_ 448 FCM_ADAS_LatCtrlDrvrOvrdVld 0 "Initializing" 1 "Valid" 2 "Invalid" 3 "Reserved" ;
VAL_ 448 FCM_ADAS_LatCtrlTyp 0 "Not_active" 1 "LKA activation" 2 "ELKA activation" 3 "DRA activation" 4 "Reserved" ;
VAL_ 448 FCM_ADAS_LatCtrlReqVld 0 "Not_valid" 1 "Steering_angle_request_valid" 2 "Reserved" 3 "Reserved" ;
VAL_ 448 FCM_ADAS_LatCtrlReq 0 "Not_active" 1 "Angle_request_active" 2 "Reserved" 3 "Reserved" ;
VAL_ 448 FCM_ACC_AccelDecelFlg 3 "Invalid" 2 "Acceleration" 1 "Deceleration" 0 "No request" ;
VAL_ 856 VCU_IntSocket230VButtonLEDSts 3 "Reserved" 2 "Blinking/Error" 1 "ON" 0 "OFF" ;
VAL_ 856 VCU_IMMO_Sts 3 "Invalid" 2 "Reserved" 1 "Immo Inactive" 0 "Immo Active" ;
VAL_ 856 VCU_BattVolt 65535 "Invalid" ;
VAL_ 1016 TBOX_OTA_ownCondchk 0 "No_Request" 1 "Request" 3 "Invalid" ;
VAL_ 1016 TBOX_Flsflg 0 "Initial_Value" 1 "HV_Flash_Mode" 2 "LV_Flash_Mode" 3 "HV_Light_Flash_Mode" 7 "Invalid" ;
VAL_ 1016 TBOX_RemFlsh 0 "Without_Request" 1 "RemFlash_Req_Active" 2 "RemCoding_Req_Active" 3 "Precheck_Req_Active" 7 "Invalid" ;
VAL_ 450 EPS_DrvrSteerTqDir 0 "Postive_counterclockwise" 1 "Negative_clockwise" 2 "No_direction" 3 "Invalid" ;
VAL_ 450 EPS_DrvrSteerTqVld 0 "Initializing" 1 "Valid" 2 "Invalid" 3 "Reserved" ;
VAL_ 450 EPS_DrvrSteerTq 4095 "Invalid" ;
VAL_ 450 EPS_OTARdy_Fb 0 "Initial" 1 "Ready" 2 "Not_Ready" 3 "Invalid" ;
VAL_ 450 EPS_DrvrIntvSteerWhlDetd 0 "False_Unintervened" 1 "True_intervention" ;
VAL_ 450 EPS_DrvrIntvSteerWhlVld 0 "Initializing" 1 "Valid" 2 "Invalid" 3 "Reserved" ;
VAL_ 450 EPS_PinionAg 65534 "Initializing" 65535 "Invalid" ;
VAL_ 450 EPS_AbortFb 0 "No_Abort" 1 "Driver_Interference_StrWhl" 2 "Reserved" 3 "Reserved" 4 "Reserved" 5 "Reserved" 6 "EPS_Internal_Failure" 7 "Vehilce_Speed_Exceeds_Limits_When_In_Control" 8 "CAN_communication_issue" 9 "Other_Abort_Reasons" 10 "Reserved" 11 "Reserved" 12 "Reserved" 13 "Reserved" 14 "Reserved" 15 "Reserved" ;
VAL_ 450 EPS_AdasLatCtrlSts 0 "Off" 1 "Available_For_Control" 2 "Active" 3 "Failure" ;
VAL_ 450 EPS_AdasLatCtrlStsVld 0 "Initializing" 1 "Valid" 2 "Active" 3 "Reserved" ;
VAL_ 450 EPS_AsscMotCrtTq 255 "Invalid" ;
VAL_ 880 EPSdeedlatCtrlMod 3 "No activation" 2 "TJA activation" 1 "ELK activation" 0 "LKA activation" ;
VAL_ 880 EPS_PwrSplyOverVoltFlt 0 "Normal" 1 "Abnormal" ;
VAL_ 880 EPS_PwrSplyUnderVoltFlt 0 "Normal" 1 "Abnormal" ;
VAL_ 880 EPS_SnsrSplyVoltFlt 0 "Normal" 1 "Abnormal" ;
VAL_ 880 EPS_MotShoOpenFlt 0 "Normal" 1 "Abnormal" ;
VAL_ 880 EPS_ThermProtnFlt 0 "Normal" 1 "Abnormal" ;
VAL_ 880 EPS_NVMFlt 0 "Normal" 1 "Abnormal" ;
VAL_ 880 EPS_RunngRstFlt 0 "Normal" 1 "Abnormal" ;
VAL_ 880 EPS_ModSts 0 "Normal" 1 "Offroad" 2 "Reserved" 3 "Invalid" ;
VAL_ 880 EPS_IninSts 0 "Incomplete_initialization" 1 "initialization_completed" ;
VAL_ 880 EPS_CrtSts 0 "Normal_operating_state" 1 "Fault_state" ;
VAL_ 880 EPS_SteerWhlBackStsFb 0 "Standby" 1 "Not_completed" 2 "Completed" 3 "Reserved" ;
VAL_ 880 EPS_TqSnsrSigErr 0 "Normal" 1 "Abnormal" ;
VAL_ 880 EPS_TSnsrFlt 0 "Normal" 1 "Abnormal" ;
VAL_ 880 EPS_ComLostFlt_ESP 0 "Normal" 1 "Abnormal" ;
VAL_ 880 EPS_SpdDataErr 0 "Normal" 1 "Abnormal" ;
VAL_ 880 EPS_HwFlt 0 "Normal" 1 "Abnormal" ;
VAL_ 880 EPS_RlyFlt 0 "Normal" 1 "Abnormal" ;
VAL_ 880 EPS_MotPosnSnsrFlt 0 "Normal" 1 "Abnormal" ;
VAL_ 880 EPS_MotCrtFlt 0 "Normal" 1 "Abnormal" ;
SIG_GROUP_ 1913 Multiplex_TPMS2 1 : Meas_TPM_1E Meas_TPM_1F;
SIG_GROUP_ 1913 Multiplex_TPMS 1 : Meas_TPM_1A Meas_TPM_1B Meas_TPM_1C Meas_TPM_1D Meas_TPM_1G Meas_TPM_1H;
